VERSION ""

NS_ :

BS_:

BU_: VMCU VGGSECUSystem TECU TACHO RECU_Virt HMIIOM GSSA EMS EBS DACU CIOM BBM ATCU ACM

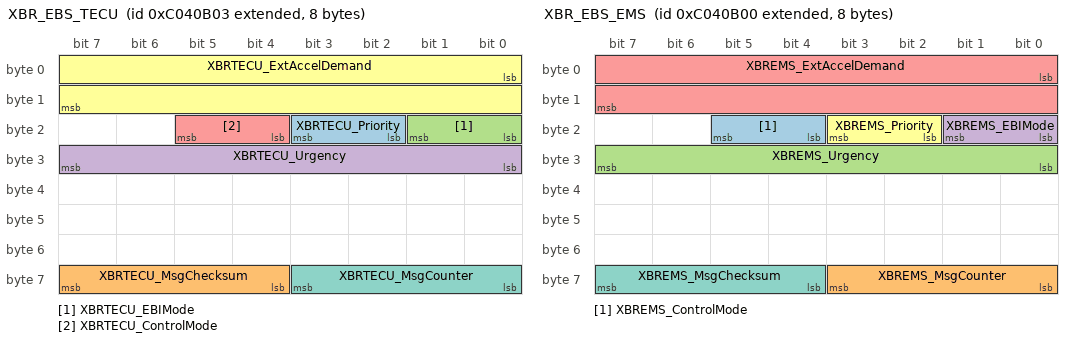
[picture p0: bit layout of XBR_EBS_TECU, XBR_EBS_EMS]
BO_ 2349075203 XBR_EBS_TECU: 8 TECU
 SG_ XBRTECU_Priority : 18|2@1+ (1,0) [0|0] ""  EBS
 SG_ XBRTECU_MsgChecksum : 60|4@1+ (1,0) [0|15] "Count"  EBS
 SG_ XBRTECU_EBIMode : 16|2@1+ (1,0) [0|0] ""  EBS
 SG_ XBRTECU_Urgency : 24|8@1+ (0.4,0) [0|102] "Percent"  EBS
 SG_ XBRTECU_ControlMode : 20|2@1+ (1,0) [0|0] ""  EBS
 SG_ XBRTECU_ExtAccelDemand : 0|16@1+ (0.00048828125,-15.687) [-15.687|16.31251171875] "m_per_s_squared"  EBS
 SG_ XBRTECU_MsgCounter : 56|4@1+ (1,0) [0|15] "Count"  EBS

BO_ 2349075200 XBR_EBS_EMS: 8 EMS
 SG_ XBREMS_ControlMode : 20|2@1+ (1,0) [0|0] ""  EBS
 SG_ XBREMS_MsgCounter : 56|4@1+ (1,0) [0|15] "Count"  EBS
 SG_ XBREMS_Urgency : 24|8@1+ (0.4,0) [0|102] "Percent"  EBS
 SG_ XBREMS_EBIMode : 16|2@1+ (1,0) [0|0] ""  EBS
 SG_ XBREMS_ExtAccelDemand : 0|16@1+ (0.00048828125,-15.687) [-15.687|16.31251171875] "m_per_s_squared"  EBS
 SG_ XBREMS_Priority : 18|2@1+ (1,0) [0|0] ""  EBS
 SG_ XBREMS_MsgChecksum : 60|4@1+ (1,0) [0|15] "Count"  EBS

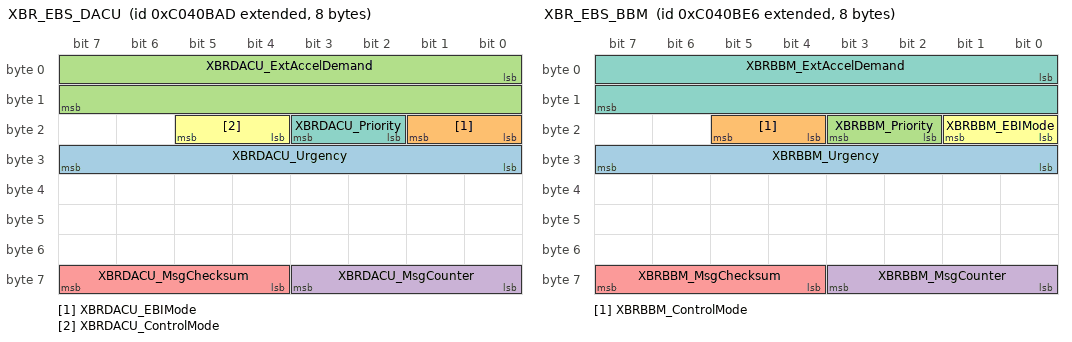
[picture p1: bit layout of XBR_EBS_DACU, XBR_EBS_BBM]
BO_ 2349075373 XBR_EBS_DACU: 8 DACU
 SG_ XBRDACU_Urgency : 24|8@1+ (0.4,0) [0|102] "Percent"  EBS,TECU
 SG_ XBRDACU_EBIMode : 16|2@1+ (1,0) [0|0] ""  EBS,TECU
 SG_ XBRDACU_ExtAccelDemand : 0|16@1+ (0.00048828125,-15.687) [-15.687|16.31251171875] "m_per_s_squared"  EBS,TECU
 SG_ XBRDACU_MsgCounter : 56|4@1+ (1,0) [0|15] "Count"  TECU,EBS
 SG_ XBRDACU_MsgChecksum : 60|4@1+ (1,0) [0|15] "Count"  TECU,EBS
 SG_ XBRDACU_ControlMode : 20|2@1+ (1,0) [0|0] ""  TECU,EBS
 SG_ XBRDACU_Priority : 18|2@1+ (1,0) [0|0] ""  EBS,TECU

BO_ 2349075430 XBR_EBS_BBM: 8 BBM
 SG_ XBRBBM_Urgency : 24|8@1+ (0.4,0) [0|102] "Percent"  EBS,VMCU
 SG_ XBRBBM_ControlMode : 20|2@1+ (1,0) [0|0] ""  EBS,VMCU
 SG_ XBRBBM_Priority : 18|2@1+ (1,0) [0|0] ""  VMCU,EBS
 SG_ XBRBBM_MsgCounter : 56|4@1+ (1,0) [0|15] "Count"  VMCU,EBS
 SG_ XBRBBM_MsgChecksum : 60|4@1+ (1,0) [0|15] "Count"  VMCU,EBS
 SG_ XBRBBM_EBIMode : 16|2@1+ (1,0) [0|0] ""  EBS,VMCU
 SG_ XBRBBM_ExtAccelDemand : 0|16@1+ (0.00048828125,-15.687) [-15.687|16.31251171875] "m_per_s_squared"  VMCU,EBS

BO_ 2566848256 WFI_X_EMS: 8 EMS
 SG_ WaterInFuelAlarm_ISig_3 : 0|2@1+ (1,0) [0|0] ""  BBM,HMIIOM,VGGSECUSystem

BO_ 2499751697 VMCU_BB1_04P: 8 VMCU
 SG_ TrailerConnected_UB_ISig_3 : 23|1@1+ (1,0) [0|0] ""  EBS
 SG_ RearAxle2DiffLock_stat_ISig_3 : 2|2@1+ (1,0) [0|0] ""  BBM,TECU,HMIIOM
 SG_ EngineStopReqBackup : 12|2@1+ (1,0) [0|0] ""  EMS
 SG_ DifferentialLockStateCentral_ISi : 6|2@1+ (1,0) [0|0] ""  HMIIOM,BBM,TECU,EBS,EMS
 SG_ RearAxle2DiffLock_stat_UB_ISig_3 : 17|1@1+ (1,0) [0|0] ""  BBM,TECU,HMIIOM
 SG_ RearPropulsionStat_Rear1Axle_ISi : 24|4@1+ (1,0) [0|0] ""  HMIIOM,EBS,EMS,TECU,BBM,DACU
 SG_ DifferentialLockStateCentral2 : 36|2@1+ (1,0) [0|0] ""  EBS,HMIIOM
 SG_ SetHSAOperation_ISig_3 : 40|3@1+ (1,0) [0|0] ""  HMIIOM,EBS
 SG_ CentralRearDiffLock_stat_ISig_3 : 4|2@1+ (1,0) [0|0] ""  HMIIOM,TECU,BBM
 SG_ LowAirPressureAlert_ISig_3 : 10|2@1+ (1,0) [0|0] ""  VGGSECUSystem,HMIIOM,EMS
 SG_ RearPropulsionStat_Rear3Axle_ISi : 32|4@1+ (1,0) [0|0] ""  DACU,HMIIOM,EMS,BBM,EBS,TECU
 SG_ DifferentialLockStateFrAxle2 : 38|2@1+ (1,0) [0|0] ""  HMIIOM,EBS
 SG_ TrailerConnected_ISig_3 : 21|2@1+ (1,0) [0|0] ""  EBS
 SG_ TrailerWithoutABS_ISig_3 : 18|2@1+ (1,0) [0|0] ""  TECU,EMS,DACU,EBS,HMIIOM
 SG_ DifferentialLockStateFrAxle1_UB_ : 14|1@1+ (1,0) [0|0] ""  BBM,EBS,HMIIOM
 SG_ DifferentialLockStateFrAxle1_ISi : 8|2@1+ (1,0) [0|0] ""  EBS,HMIIOM,BBM
 SG_ RearAxle1DiffLock_stat_UB_ISig_3 : 16|1@1+ (1,0) [0|0] ""  BBM,TECU,HMIIOM
 SG_ RearPropulsionStat_Rear2Axle_ISi : 28|4@1+ (1,0) [0|0] ""  EBS,BBM,EMS,HMIIOM,DACU,TECU
 SG_ CentralRearDiffLock_stat_UB_ISig : 15|1@1+ (1,0) [0|0] ""  HMIIOM,BBM,TECU
 SG_ RearAxle1DiffLock_stat_ISig_3 : 0|2@1+ (1,0) [0|0] ""  HMIIOM,BBM,TECU
 SG_ TrailerWithoutABS_UB_ISig_3 : 20|1@1+ (1,0) [0|0] ""  TECU,DACU,EBS,EMS,HMIIOM

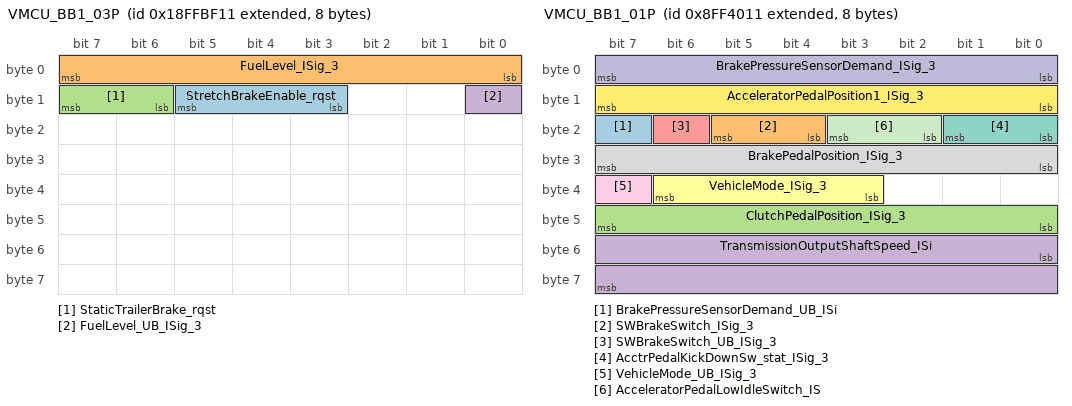
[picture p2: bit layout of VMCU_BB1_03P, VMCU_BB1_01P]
BO_ 2566897425 VMCU_BB1_03P: 8 VMCU
 SG_ StretchBrakeEnable_rqst : 11|3@1+ (1,0) [0|0] ""  EBS
 SG_ FuelLevel_ISig_3 : 0|8@1+ (0.4,0) [0|102] "Percent"  HMIIOM,BBM,CIOM,EMS
 SG_ StaticTrailerBrake_rqst : 14|2@1+ (1,0) [0|0] ""  EBS
 SG_ FuelLevel_UB_ISig_3 : 8|1@1+ (1,0) [0|0] ""  BBM,HMIIOM,CIOM,EMS

BO_ 2298429457 VMCU_BB1_01P: 8 VMCU
 SG_ BrakePressureSensorDemand_UB_ISi : 23|1@1+ (1,0) [0|0] ""  EBS
 SG_ SWBrakeSwitch_ISig_3 : 20|2@1+ (1,0) [0|0] ""  HMIIOM,EBS
 SG_ ClutchPedalPosition_ISig_3 : 40|8@1+ (0.4,0) [0|102] "Percent"  EBS
 SG_ TransmissionOutputShaftSpeed_ISi : 48|16@1+ (0.125,0) [0|8191.875] "rpm"  RECU_Virt,EMS,BBM
 SG_ SWBrakeSwitch_UB_ISig_3 : 22|1@1+ (1,0) [0|0] ""  HMIIOM,EBS
 SG_ VehicleMode_ISig_3 : 35|4@1+ (1,0) [0|0] ""  ACM,HMIIOM,CIOM,DACU,TECU,TACHO,EMS,VGGSECUSystem,BBM,EBS
 SG_ AcctrPedalKickDownSw_stat_ISig_3 : 16|2@1+ (1,0) [0|0] ""  BBM,TECU,HMIIOM,EMS,DACU
 SG_ BrakePedalPosition_ISig_3 : 24|8@1+ (0.4,0) [0|102] "Percent"  HMIIOM,TECU,EBS,CIOM,DACU,BBM
 SG_ VehicleMode_UB_ISig_3 : 39|1@1+ (1,0) [0|0] ""  EMS,CIOM,HMIIOM,DACU,TECU,VGGSECUSystem,ACM,TACHO,BBM,EBS
 SG_ BrakePressureSensorDemand_ISig_3 : 0|8@1+ (1,0) [0|255] "Percent"  EBS
 SG_ AcceleratorPedalLowIdleSwitch_IS : 18|2@1+ (1,0) [0|0] ""  HMIIOM,BBM,TECU
 SG_ AcceleratorPedalPosition1_ISig_3 : 8|8@1+ (0.4,0) [0|102] "Percent"  EMS,BBM,DACU,EBS,HMIIOM,TECU,CIOM

BO_ 2566906094 VDO1prop_X_TACHO: 32 TACHO
 SG_ RemningTimeTillNxtWklyRestPrd_IS : 160|16@1+ (1,0) [0|65535] "min"  HMIIOM
 SG_ RemainingCurDailyDrivingTime_ISi : 96|16@1+ (1,0) [0|65535] "min"  HMIIOM
 SG_ RemainingCurrentDrivingTime_ISig : 0|16@1+ (1,0) [0|65535] "min"  HMIIOM
 SG_ SingleMultiDriver_ISig_3 : 252|2@1+ (1,0) [0|0] ""  HMIIOM
 SG_ UnknownPeriods_ISig_3 : 246|2@1+ (1,0) [0|0] ""  HMIIOM
 SG_ OpenCompensationWeekBfrLast_ISig : 208|16@1+ (1,0) [0|65535] "min"  HMIIOM
 SG_ RemainingReducedDailyRestPrd_ISi : 243|3@1+ (1,0) [0|0] ""  HMIIOM
 SG_ RemainingDurOfCurBreakRest_ISig_ : 48|16@1+ (1,0) [0|65535] "min"  HMIIOM
 SG_ RemainingTimeTillNextRestBreak_I : 16|16@1+ (1,0) [0|65535] "min"  HMIIOM
 SG_ NextDrivingPeriod_ISig_3 : 80|16@1+ (1,0) [0|65535] "min"  HMIIOM
 SG_ DurationOfNextRestBreak_ISig_3 : 32|16@1+ (1,0) [0|65535] "min"  HMIIOM
 SG_ RemainingDrivTimeOfCurWeek_ISig_ : 144|16@1+ (1,0) [0|65535] "min"  HMIIOM
 SG_ DurationOfNextDailyRestPeriod_IS : 128|16@1+ (1,0) [0|65535] "min"  HMIIOM
 SG_ OpenCompensationInTheLastWeek_IS : 192|16@1+ (1,0) [0|65535] "min"  HMIIOM
 SG_ TimeOverlap_ISig_3 : 254|2@1+ (1,0) [0|0] ""  HMIIOM
 SG_ TimeBeforeStartOfNxtDrvngPrd_ISi : 64|16@1+ (1,0) [0|65535] "min"  HMIIOM
 SG_ WklyRestPrdCalcEnabledDisabled_I : 250|2@1+ (1,0) [0|0] ""  HMIIOM
 SG_ Remaining10hDrvTime_ISig_3 : 240|3@1+ (1,0) [0|0] ""  HMIIOM
 SG_ RemnngTimeTillNxtDailyRestPrd_IS : 112|16@1+ (1,0) [0|65535] "min"  HMIIOM
 SG_ DurationOfNextWeeklyRestPeriod_I : 176|16@1+ (1,0) [0|65535] "min"  HMIIOM
 SG_ OpenCompensation2ndWeekBfrLast_I : 224|16@1+ (1,0) [0|65535] "min"  HMIIOM
 SG_ SufficientData_ISig_3 : 248|2@1+ (1,0) [0|0] ""  HMIIOM

BO_ 2566832401 VDHR_X_VMCU: 8 VMCU
 SG_ TotalVehicleDistanceHighRes_ISig : 0|32@1+ (5,0) [0|21474836475] "m"  HMIIOM,EBS,EMS,ACM,DACU,TECU,CIOM,BBM,VGGSECUSystem

BO_ 2566832622 VDHR_X_TACHO: 8 TACHO
 SG_ TachoHighResTotalVehDistance : 0|32@1+ (5,0) [0|21474836475] "m"  VMCU

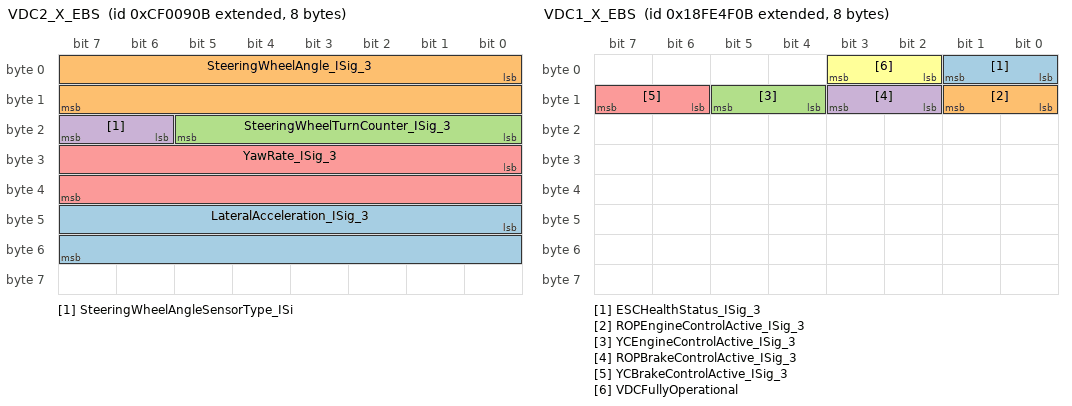
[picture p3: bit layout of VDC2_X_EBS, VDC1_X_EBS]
BO_ 2364541195 VDC2_X_EBS: 8 EBS
 SG_ LateralAcceleration_ISig_3 : 40|16@1+ (0.00048828125,-15.687) [-15.687|16.31251171875] "m_per_s_squared"  HMIIOM,BBM,DACU
 SG_ SteeringWheelAngle_ISig_3 : 0|16@1+ (0.0009765625,-31.374) [-31.374|32.6250234375] "rad"  CIOM,BBM,VMCU,DACU,VGGSECUSystem
 SG_ SteeringWheelTurnCounter_ISig_3 : 16|6@1+ (1,-32) [-32|31] "turns"  BBM
 SG_ SteeringWheelAngleSensorType_ISi : 22|2@1+ (1,0) [0|0] ""  BBM
 SG_ YawRate_ISig_3 : 24|16@1+ (0.000122,-3.92) [-3.92|4.07527] "Rad_per_s"  HMIIOM,BBM,DACU

BO_ 2566803211 VDC1_X_EBS: 8 EBS
 SG_ ESCHealthStatus_ISig_3 : 0|2@1+ (1,0) [0|0] ""  HMIIOM
 SG_ ROPEngineControlActive_ISig_3 : 8|2@1+ (1,0) [0|0] ""  VMCU,HMIIOM,DACU,TECU
 SG_ YCEngineControlActive_ISig_3 : 12|2@1+ (1,0) [0|0] ""  HMIIOM,DACU,VMCU,TECU
 SG_ ROPBrakeControlActive_ISig_3 : 10|2@1+ (1,0) [0|0] ""  TECU,VMCU,CIOM,DACU,HMIIOM
 SG_ YCBrakeControlActive_ISig_3 : 14|2@1+ (1,0) [0|0] ""  HMIIOM,DACU,TECU,VMCU,CIOM
 SG_ VDCFullyOperational : 2|2@1+ (1,0) [0|0] ""  DACU,HMIIOM

BO_ 2671902706 TesterFuncDiagMsg_BB1: 8 VMCU
 SG_ FuncDiagDataTester_ISig_3 : 0|64@1+ (1,0) [0|0] ""  EBS,TACHO,ACM

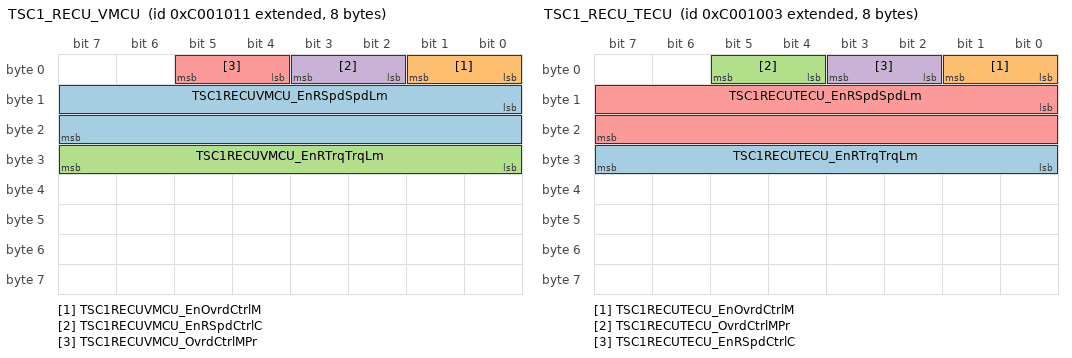
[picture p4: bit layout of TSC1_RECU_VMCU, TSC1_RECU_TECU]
BO_ 2348814353 TSC1_RECU_VMCU: 8 VMCU
 SG_ TSC1RECUVMCU_EnRSpdSpdLm : 8|16@1+ (0.125,0) [0|8191.875] "rpm"  RECU_Virt,EBS,VGGSECUSystem
 SG_ TSC1RECUVMCU_EnOvrdCtrlM : 0|2@1+ (1,0) [0|0] ""  EBS,VGGSECUSystem,RECU_Virt
 SG_ TSC1RECUVMCU_EnRTrqTrqLm : 24|8@1+ (1,-125) [-125|130] "Percent"  RECU_Virt,EBS,VGGSECUSystem
 SG_ TSC1RECUVMCU_EnRSpdCtrlC : 2|2@1+ (1,0) [0|0] ""  VGGSECUSystem,RECU_Virt,EBS
 SG_ TSC1RECUVMCU_OvrdCtrlMPr : 4|2@1+ (1,0) [0|0] ""  EBS,VGGSECUSystem,RECU_Virt

BO_ 2348814339 TSC1_RECU_TECU: 8 TECU
 SG_ TSC1RECUTECU_EnRTrqTrqLm : 24|8@1+ (1,-125) [-125|130] "Percent"  RECU_Virt
 SG_ TSC1RECUTECU_EnOvrdCtrlM : 0|2@1+ (1,0) [0|0] ""  RECU_Virt
 SG_ TSC1RECUTECU_OvrdCtrlMPr : 4|2@1+ (1,0) [0|0] ""  RECU_Virt
 SG_ TSC1RECUTECU_EnRSpdCtrlC : 2|2@1+ (1,0) [0|0] ""  RECU_Virt
 SG_ TSC1RECUTECU_EnRSpdSpdLm : 8|16@1+ (0.125,0) [0|8191.875] "rpm"  RECU_Virt

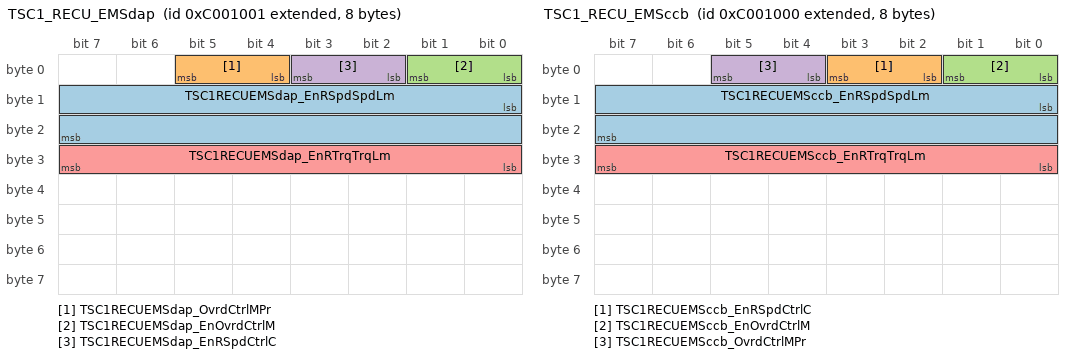
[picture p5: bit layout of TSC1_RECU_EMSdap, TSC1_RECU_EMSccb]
BO_ 2348814337 TSC1_RECU_EMSdap: 8 EMS
 SG_ TSC1RECUEMSdap_EnRSpdSpdLm : 8|16@1+ (0.125,0) [0|8191.875] "rpm"  VGGSECUSystem,RECU_Virt
 SG_ TSC1RECUEMSdap_OvrdCtrlMPr : 4|2@1+ (1,0) [0|0] ""  VGGSECUSystem,RECU_Virt
 SG_ TSC1RECUEMSdap_EnOvrdCtrlM : 0|2@1+ (1,0) [0|0] ""  RECU_Virt,VGGSECUSystem
 SG_ TSC1RECUEMSdap_EnRSpdCtrlC : 2|2@1+ (1,0) [0|0] ""  RECU_Virt,VGGSECUSystem
 SG_ TSC1RECUEMSdap_EnRTrqTrqLm : 24|8@1+ (1,-125) [-125|130] "Percent"  RECU_Virt,VGGSECUSystem

BO_ 2348814336 TSC1_RECU_EMSccb: 8 EMS
 SG_ TSC1RECUEMSccb_EnRSpdSpdLm : 8|16@1+ (0.125,0) [0|8191.875] "rpm"  RECU_Virt
 SG_ TSC1RECUEMSccb_EnRSpdCtrlC : 2|2@1+ (1,0) [0|0] ""  RECU_Virt
 SG_ TSC1RECUEMSccb_EnOvrdCtrlM : 0|2@1+ (1,0) [0|0] ""  RECU_Virt
 SG_ TSC1RECUEMSccb_OvrdCtrlMPr : 4|2@1+ (1,0) [0|0] ""  RECU_Virt
 SG_ TSC1RECUEMSccb_EnRTrqTrqLm : 24|8@1+ (1,-125) [-125|130] "Percent"  RECU_Virt

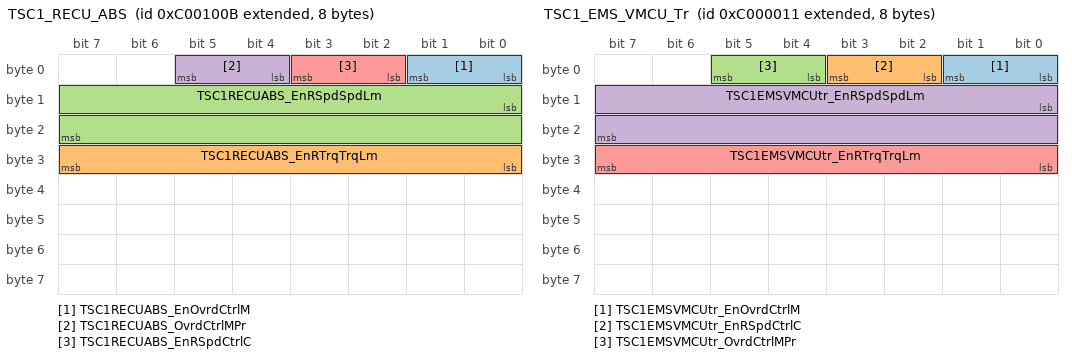
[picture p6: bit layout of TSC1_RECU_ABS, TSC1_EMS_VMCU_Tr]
BO_ 2348814347 TSC1_RECU_ABS: 8 EBS
 SG_ TSC1RECUABS_EnOvrdCtrlM : 0|2@1+ (1,0) [0|0] ""  VGGSECUSystem,RECU_Virt
 SG_ TSC1RECUABS_EnRTrqTrqLm : 24|8@1+ (1,-125) [-125|130] "Percent"  VGGSECUSystem,RECU_Virt
 SG_ TSC1RECUABS_EnRSpdSpdLm : 8|16@1+ (0.125,0) [0|8191.875] "rpm"  RECU_Virt,VGGSECUSystem
 SG_ TSC1RECUABS_OvrdCtrlMPr : 4|2@1+ (1,0) [0|0] ""  RECU_Virt,VGGSECUSystem
 SG_ TSC1RECUABS_EnRSpdCtrlC : 2|2@1+ (1,0) [0|0] ""  RECU_Virt,VGGSECUSystem

BO_ 2348810257 TSC1_EMS_VMCU_Tr: 8 VMCU
 SG_ TSC1EMSVMCUtr_EnOvrdCtrlM : 0|2@1+ (1,0) [0|0] ""  EMS
 SG_ TSC1EMSVMCUtr_EnRSpdCtrlC : 2|2@1+ (1,0) [0|0] ""  EMS
 SG_ TSC1EMSVMCUtr_OvrdCtrlMPr : 4|2@1+ (1,0) [0|0] ""  EMS
 SG_ TSC1EMSVMCUtr_EnRSpdSpdLm : 8|16@1+ (0.125,0) [0|8191.875] "rpm"  EMS
 SG_ TSC1EMSVMCUtr_EnRTrqTrqLm : 24|8@1+ (1,-125) [-125|130] "Percent"  EMS

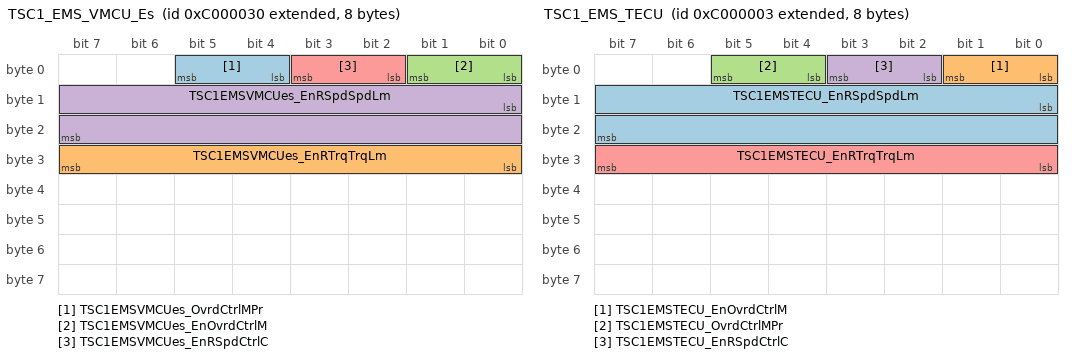
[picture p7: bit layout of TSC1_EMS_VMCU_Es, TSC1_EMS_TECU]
BO_ 2348810288 TSC1_EMS_VMCU_Es: 8 VMCU
 SG_ TSC1EMSVMCUes_OvrdCtrlMPr : 4|2@1+ (1,0) [0|0] ""  EMS,TECU
 SG_ TSC1EMSVMCUes_EnRTrqTrqLm : 24|8@1+ (1,-125) [-125|130] "Percent"  TECU,EMS
 SG_ TSC1EMSVMCUes_EnOvrdCtrlM : 0|2@1+ (1,0) [0|0] ""  TECU,EMS
 SG_ TSC1EMSVMCUes_EnRSpdSpdLm : 8|16@1+ (0.125,0) [0|8191.875] "rpm"  TECU,EMS
 SG_ TSC1EMSVMCUes_EnRSpdCtrlC : 2|2@1+ (1,0) [0|0] ""  EMS,TECU

BO_ 2348810243 TSC1_EMS_TECU: 8 TECU
 SG_ TSC1EMSTECU_EnRSpdSpdLm : 8|16@1+ (0.125,0) [0|8191.875] "rpm"  EMS
 SG_ TSC1EMSTECU_EnOvrdCtrlM : 0|2@1+ (1,0) [0|0] ""  EMS
 SG_ TSC1EMSTECU_OvrdCtrlMPr : 4|2@1+ (1,0) [0|0] ""  EMS
 SG_ TSC1EMSTECU_EnRSpdCtrlC : 2|2@1+ (1,0) [0|0] ""  EMS
 SG_ TSC1EMSTECU_EnRTrqTrqLm : 24|8@1+ (1,-125) [-125|130] "Percent"  EMS

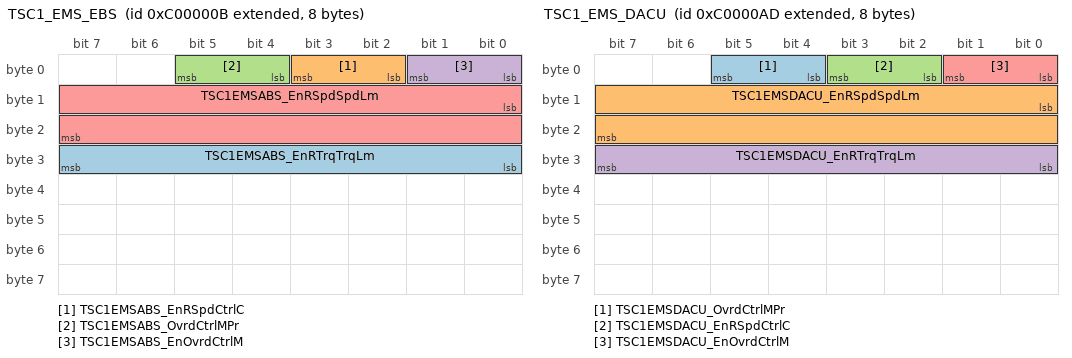
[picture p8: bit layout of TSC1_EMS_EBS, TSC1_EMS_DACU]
BO_ 2348810251 TSC1_EMS_EBS: 8 EBS
 SG_ TSC1EMSABS_EnRTrqTrqLm : 24|8@1+ (1,-125) [-125|130] "Percent"  EMS
 SG_ TSC1EMSABS_EnRSpdCtrlC : 2|2@1+ (1,0) [0|0] ""  EMS
 SG_ TSC1EMSABS_OvrdCtrlMPr : 4|2@1+ (1,0) [0|0] ""  EMS
 SG_ TSC1EMSABS_EnOvrdCtrlM : 0|2@1+ (1,0) [0|0] ""  EMS
 SG_ TSC1EMSABS_EnRSpdSpdLm : 8|16@1+ (0.125,0) [0|8191.875] "rpm"  EMS

BO_ 2348810413 TSC1_EMS_DACU: 8 DACU
 SG_ TSC1EMSDACU_OvrdCtrlMPr : 4|2@1+ (1,0) [0|0] ""  EMS
 SG_ TSC1EMSDACU_EnRSpdSpdLm : 8|16@1+ (0.125,0) [0|8191.875] "rpm"  EMS
 SG_ TSC1EMSDACU_EnRSpdCtrlC : 2|2@1+ (1,0) [0|0] ""  EMS
 SG_ TSC1EMSDACU_EnRTrqTrqLm : 24|8@1+ (1,-125) [-125|130] "Percent"  EMS
 SG_ TSC1EMSDACU_EnOvrdCtrlM : 0|2@1+ (1,0) [0|0] ""  EMS

CM_ "COM_MATRIX_1.31.X0";
CM_ BU_ VGGSECUSystem "Describes interfaces used by a couple of ECUs within VGGS system.";
CM_ BU_ GSSA "Gearshift Selector, Vendor";
CM_ BU_ ATCU "ATCU Represents Allison Transmission, reception of signal on BB1 to avoid that TECU receives signal on both BB1 & BB2.";
CM_ BO_ 2349075203 "PGN 1024 External Brake Request";
CM_ SG_ 2349075203 XBRTECU_Urgency "254 Error ; 255 Not available";
CM_ SG_ 2349075203 XBRTECU_ExtAccelDemand "65024 - 65279 Error ; 65280 - 65535 Not available";
CM_ BO_ 2349075200 "PGN 1024 External Brake Request";
CM_ BO_ 2349075373 "PGN 1024 External Brake Request";
CM_ SG_ 2349075373 XBRDACU_Urgency "254 Error ; 255 Not available";
CM_ SG_ 2349075373 XBRDACU_ExtAccelDemand "65024 - 65279 Error ; 65280 - 65535 Not available";
CM_ BO_ 2349075430 "PGN 1024 External Brake Request";
CM_ SG_ 2349075430 XBRBBM_Urgency "254 Error ; 255 Not available";
CM_ SG_ 2349075430 XBRBBM_ExtAccelDemand "65024 - 65279 Error ; 65280 - 65535 Not available";
CM_ BO_ 2566848256 "PGN 65279 Water in Fuel Indicator";
CM_ SG_ 2566897425 FuelLevel_ISig_3 "254 Error ; 255 Not available";
CM_ SG_ 2298429457 ClutchPedalPosition_ISig_3 "254 Error ; 255 Not available";
CM_ SG_ 2298429457 TransmissionOutputShaftSpeed_ISi "65024 - 65279 Error ; 65280 - 65535 Not available";
CM_ SG_ 2298429457 BrakePedalPosition_ISig_3 "254 Error ; 255 Not available";
CM_ SG_ 2298429457 BrakePressureSensorDemand_ISig_3 "254 Error ; 255 Not available";
CM_ SG_ 2298429457 AcceleratorPedalPosition1_ISig_3 "254 Error ; 255 Not available";
CM_ SG_ 2566906094 RemningTimeTillNxtWklyRestPrd_IS "65024 - 65279 Error ; 65280 - 65535 Not available";
CM_ SG_ 2566906094 RemainingCurDailyDrivingTime_ISi "65024 - 65279 Error ; 65280 - 65535 Not available";
CM_ SG_ 2566906094 RemainingCurrentDrivingTime_ISig "65024 - 65279 Error ; 65280 - 65535 Not available";
CM_ SG_ 2566906094 OpenCompensationWeekBfrLast_ISig "65024 - 65279 Error ; 65280 - 65535 Not available";
CM_ SG_ 2566906094 RemainingDurOfCurBreakRest_ISig_ "65024 - 65279 Error ; 65280 - 65535 Not available";
CM_ SG_ 2566906094 RemainingTimeTillNextRestBreak_I "65024 - 65279 Error ; 65280 - 65535 Not available";
CM_ SG_ 2566906094 NextDrivingPeriod_ISig_3 "65024 - 65279 Error ; 65280 - 65535 Not available";
CM_ SG_ 2566906094 DurationOfNextRestBreak_ISig_3 "65024 - 65279 Error ; 65280 - 65535 Not available";
CM_ SG_ 2566906094 RemainingDrivTimeOfCurWeek_ISig_ "65024 - 65279 Error ; 65280 - 65535 Not available";
CM_ SG_ 2566906094 DurationOfNextDailyRestPeriod_IS "65024 - 65279 Error ; 65280 - 65535 Not available";
CM_ SG_ 2566906094 OpenCompensationInTheLastWeek_IS "65024 - 65279 Error ; 65280 - 65535 Not available";
CM_ SG_ 2566906094 TimeBeforeStartOfNxtDrvngPrd_ISi "65024 - 65279 Error ; 65280 - 65535 Not available";
CM_ SG_ 2566906094 RemnngTimeTillNxtDailyRestPrd_IS "65024 - 65279 Error ; 65280 - 65535 Not available";
CM_ SG_ 2566906094 DurationOfNextWeeklyRestPeriod_I "65024 - 65279 Error ; 65280 - 65535 Not available";
CM_ SG_ 2566906094 OpenCompensation2ndWeekBfrLast_I "65024 - 65279 Error ; 65280 - 65535 Not available";
CM_ BO_ 2566832401 "PGN 65217 High Resolution Vehicle Distance";
CM_ SG_ 2566832401 TotalVehicleDistanceHighRes_ISig "4261412864 - 4278190079 Error ; 4278190080 - 4294967295 Not available";
CM_ BO_ 2566832622 "PGN 65217 High Resolution Vehicle Distance, From TACHO";
CM_ SG_ 2566832622 TachoHighResTotalVehDistance "4261412864 - 4278190079 Error ; 4278190080 - 4294967295 Not available";
CM_ BO_ 2364541195 "PGN 61449 Vehicle Dynamic Stability Control 2";
CM_ SG_ 2364541195 LateralAcceleration_ISig_3 "65024 - 65279 Error ; 65280 - 65535 Not available";
CM_ SG_ 2364541195 SteeringWheelAngle_ISig_3 "65024 - 65279 Error ; 65280 - 65535 Not available";
CM_ SG_ 2364541195 SteeringWheelTurnCounter_ISig_3 "62 Error; 63 Not available";
CM_ SG_ 2364541195 YawRate_ISig_3 "65024 - 65279 Error ; 65280 - 65535 Not available";
CM_ BO_ 2566803211 "PGN 65103 Vehicle Dynamic Stability Control 1";
CM_ BO_ 2348814353 "PGN 0 Torque/Speed Control 1, From VMCU to RECU";
CM_ SG_ 2348814353 TSC1RECUVMCU_EnRSpdSpdLm "65024 - 65279 Error ; 65280 - 65535 Not available";
CM_ SG_ 2348814353 TSC1RECUVMCU_EnRTrqTrqLm "254 Error ; 255 Not available";
CM_ BO_ 2348814339 "PGN 0 Torque/Speed Control 1";
CM_ BO_ 2348814337 "PGN 0 Torque/Speed Control 1";
CM_ SG_ 2348814337 TSC1RECUEMSdap_EnRSpdSpdLm "65024 - 65279 Error ; 65280 - 65535 Not available";
CM_ SG_ 2348814337 TSC1RECUEMSdap_EnRTrqTrqLm "254 Error ; 255 Not available";
CM_ BO_ 2348814336 "PGN 0 Torque/Speed Control 1";
CM_ SG_ 2348814336 TSC1RECUEMSccb_EnRSpdSpdLm "65024 - 65279 Error ; 65280 - 65535 Not available";
CM_ SG_ 2348814336 TSC1RECUEMSccb_EnRTrqTrqLm "254 Error ; 255 Not available";
CM_ BO_ 2348814347 "PGN 0 Torque/Speed Control 1";
CM_ SG_ 2348814347 TSC1RECUABS_EnRTrqTrqLm "254 Error ; 255 Not available";
CM_ SG_ 2348814347 TSC1RECUABS_EnRSpdSpdLm "65024 - 65279 Error ; 65280 - 65535 Not available";
CM_ BO_ 2348810257 "PGN 0 Torque/Speed Control 1, Torque control, From VMCU to EMS";
CM_ SG_ 2348810257 TSC1EMSVMCUtr_EnRSpdSpdLm "65024 - 65279 Error ; 65280 - 65535 Not available";
CM_ SG_ 2348810257 TSC1EMSVMCUtr_EnRTrqTrqLm "254 Error ; 255 Not available";
CM_ BO_ 2348810288 "PGN 0 Torque/Speed Control 1, Engine speed control, From VMCU to EMS";
CM_ SG_ 2348810288 TSC1EMSVMCUes_EnRTrqTrqLm "254 Error ; 255 Not available";
CM_ SG_ 2348810288 TSC1EMSVMCUes_EnRSpdSpdLm "65024 - 65279 Error ; 65280 - 65535 Not available";
CM_ BO_ 2348810243 "PGN 0 Torque/Speed Control 1, From TECU to EMS";
CM_ SG_ 2348810243 TSC1EMSTECU_EnRSpdSpdLm "65024 - 65279 Error ; 65280 - 65535 Not available";
CM_ SG_ 2348810243 TSC1EMSTECU_EnRTrqTrqLm "254 Error ; 255 Not available";
CM_ BO_ 2348810251 "PGN 0 Torque/Speed Control 1, From EBS to EMS";
CM_ SG_ 2348810251 TSC1EMSABS_EnRTrqTrqLm "254 Error ; 255 Not available";
CM_ SG_ 2348810251 TSC1EMSABS_EnRSpdSpdLm "65024 - 65279 Error ; 65280 - 65535 Not available";
CM_ BO_ 2348810413 "PGN 0 Torque/Speed Control 1, From DACU to EMS";
CM_ SG_ 2348810413 TSC1EMSDACU_EnRSpdSpdLm "65024 - 65279 Error ; 65280 - 65535 Not available";
CM_ SG_ 2348810413 TSC1EMSDACU_EnRTrqTrqLm "254 Error ; 255 Not available";
BA_DEF_ BO_  "GenMsgStartDelayTime" INT 0 0;
BA_DEF_ BO_  "GenMsgDelayTime" INT 0 0;
BA_DEF_ BO_  "GenMsgNrOfRepetition" INT 0 0;
BA_DEF_ BO_  "GenMsgCycleTimeFast" INT 0 0;
BA_DEF_ BO_  "GenMsgCycleTime" INT 0 0;
BA_DEF_ BO_  "GenMsgSendType" ENUM  "Cyclic","NotUsed","NotUsed","NotUsed","NotUsed","NotUsed","NotUsed","IfActive","NoMsgSendType","NotUsed";
BA_DEF_ SG_  "GenSigStartValue" INT 0 0;
BA_DEF_ SG_  "GenSigCycleTimeActive" INT 0 0;
BA_DEF_ SG_  "GenSigCycleTime" INT 0 0;
BA_DEF_ SG_  "GenSigSendType" ENUM  "Cyclic","OnWrite","OnWriteWithRepetition","OnChange","OnChangeWithRepetition","IfActive","IfActiveWithRepetition","NoSigSendType","NotUsed","NotUsed","NotUsed","NotUsed","NotUsed";
BA_DEF_  "Baudrate" INT 0 1000000;
BA_DEF_  "BusType" STRING ;
BA_DEF_  "NmType" STRING ;
BA_DEF_  "Manufacturer" STRING ;
BA_DEF_  "VersionYear" INT 0 99;
BA_DEF_  "VersionNumber" INT 0 99;
BA_DEF_  "VersionMonth" INT 1 12;
BA_DEF_  "VersionDay" INT 1 31;
BA_DEF_ BO_  "VFrameFormat" ENUM  "StandardCAN","ExtendedCAN","reserved","J1939PG";
BA_DEF_ BU_  "TpOwnSystemEcuNumber" HEX 0 255;
BA_DEF_ BO_  "TpJ1939VarDlc" ENUM  "No","Yes";
BA_DEF_ SG_  "SigType" ENUM  "Default","Range","RangeSigned","ASCII","Discrete","Control","ReferencePGN","DTC","StringDelimiter","StringLength","StringLengthControl";
BA_DEF_ SG_  "SeToolVersion_SIGNAL" STRING ;
BA_DEF_ SG_  "SeToolUniqueID_SIGNAL" STRING ;
BA_DEF_ SG_  "SeToolOwnerSigGroup_SIGNAL" STRING ;
BA_DEF_ SG_  "SeToolOwnerSigGroupID_SIGNAL" STRING ;
BA_DEF_ SG_  "SeToolName_SIGNAL" STRING ;
BA_DEF_ SG_  "SeToolItemID_SIGNAL" STRING ;
BA_DEF_ SG_  "SeToolAncestorID_SIGNAL" STRING ;
BA_DEF_ SG_  "SPN" INT 0 524287;
BA_DEF_  "ProtocolType" STRING ;
BA_DEF_ SG_  "Platform_VMCU1_Sig" ENUM  "No","Yes";
BA_DEF_ BU_  "NmStationAddress" INT 0 255;
BA_DEF_ BU_  "NmJ1939IdentityNumber" INT 0 2097151;
BA_DEF_  "NmAsrWaitBusSleepTime" INT 0 65535;
BA_DEF_  "NmAsrTimeoutTime" INT 0 65535;
BA_DEF_  "NmAsrRepeatMessageTime" INT 0 65535;
BA_DEF_ BU_  "NmAsrNodeIdentifier" HEX 0 253;
BA_DEF_ BU_  "NmAsrNode" ENUM  "No","Yes";
BA_DEF_  "NmAsrMessageCount" INT 1 256;
BA_DEF_  "NmAsrCanMsgCycleTime" INT 0 65535;
BA_DEF_  "NmAsrBaseAddress" HEX 0 536870911;
BA_DEF_ SG_  "NeedsUpdateBit" ENUM  "No","Yes";
BA_DEF_ BU_  "IsOBDrelevant" ENUM  "No","Yes";
BA_DEF_ SG_  "GenSigMaxLatency" INT 0 65535;
BA_DEF_ SG_  "GenSigILSupport" ENUM  "Yes","No";
BA_DEF_ BO_  "GenMsgRequestable" INT 0 1;
BA_DEF_ BO_  "GenMsgILSupport" ENUM  "No","Yes";
BA_DEF_ BU_  "DiagnosticClientAddress" HEX 0 255;
BA_DEF_ BO_  "DiagUUDTResponse" ENUM  "No","Yes";
BA_DEF_ BO_  "DiagState" ENUM  "No","Yes";
BA_DEF_ BU_  "DiagRole" ENUM  "None","OBDTester","ExternalTester","InternalTester";
BA_DEF_ BO_  "DiagResponse" ENUM  "No","Yes";
BA_DEF_ BO_  "DiagRequest" ENUM  "No","Yes";
BA_DEF_ BO_  "DiagConnection" HEX 0 65535;
BA_DEF_  "DBName" STRING ;
BA_DEF_ BO_  "CanTpFcFrameId" HEX 0 2147483647;
BA_DEF_ BO_  "CanTpBs" INT 0 255;
BA_DEF_ SG_  "SystemSignalLongSymbol" STRING ;
BA_DEF_REL_ BU_SG_REL_  "GenSigTimeoutTime" INT 0 65535;
BA_DEF_REL_ BU_SG_REL_  "GenSigFirstTimeoutTime" INT 0 65535;
BA_DEF_DEF_  "GenMsgStartDelayTime" 0;
BA_DEF_DEF_  "GenMsgDelayTime" 0;
BA_DEF_DEF_  "GenMsgNrOfRepetition" 0;
BA_DEF_DEF_  "GenMsgCycleTimeFast" 0;
BA_DEF_DEF_  "GenMsgCycleTime" 0;
BA_DEF_DEF_  "GenMsgSendType" "Cyclic";
BA_DEF_DEF_  "GenSigStartValue" 0;
BA_DEF_DEF_  "GenSigCycleTimeActive" 0;
BA_DEF_DEF_  "GenSigCycleTime" 0;
BA_DEF_DEF_  "GenSigSendType" "Cyclic";
BA_DEF_DEF_  "Baudrate" 500000;
BA_DEF_DEF_  "BusType" "";
BA_DEF_DEF_  "NmType" "";
BA_DEF_DEF_  "Manufacturer" "VOLVO_AB";
BA_DEF_DEF_  "VersionYear" 0;
BA_DEF_DEF_  "VersionNumber" 0;
BA_DEF_DEF_  "VersionMonth" 1;
BA_DEF_DEF_  "VersionDay" 1;
BA_DEF_DEF_  "VFrameFormat" "ExtendedCAN";
BA_DEF_DEF_  "TpOwnSystemEcuNumber" 0;
BA_DEF_DEF_  "TpJ1939VarDlc" "No";
BA_DEF_DEF_  "SigType" "Default";
BA_DEF_DEF_  "SeToolVersion_SIGNAL" "";
BA_DEF_DEF_  "SeToolUniqueID_SIGNAL" "";
BA_DEF_DEF_  "SeToolOwnerSigGroup_SIGNAL" "";
BA_DEF_DEF_  "SeToolOwnerSigGroupID_SIGNAL" "";
BA_DEF_DEF_  "SeToolName_SIGNAL" "";
BA_DEF_DEF_  "SeToolItemID_SIGNAL" "";
BA_DEF_DEF_  "SeToolAncestorID_SIGNAL" "";
BA_DEF_DEF_  "SPN" 0;
BA_DEF_DEF_  "ProtocolType" "";
BA_DEF_DEF_  "Platform_VMCU1_Sig" "No";
BA_DEF_DEF_  "NmStationAddress" 254;
BA_DEF_DEF_  "NmJ1939IdentityNumber" 0;
BA_DEF_DEF_  "NmAsrWaitBusSleepTime" 750;
BA_DEF_DEF_  "NmAsrTimeoutTime" 5000;
BA_DEF_DEF_  "NmAsrRepeatMessageTime" 300;
BA_DEF_DEF_  "NmAsrNodeIdentifier" 0;
BA_DEF_DEF_  "NmAsrNode" "Yes";
BA_DEF_DEF_  "NmAsrMessageCount" 256;
BA_DEF_DEF_  "NmAsrCanMsgCycleTime" 200;
BA_DEF_DEF_  "NmAsrBaseAddress" 486506496;
BA_DEF_DEF_  "NeedsUpdateBit" "No";
BA_DEF_DEF_  "IsOBDrelevant" "No";
BA_DEF_DEF_  "GenSigMaxLatency" 0;
BA_DEF_DEF_  "GenSigILSupport" "Yes";
BA_DEF_DEF_  "GenMsgRequestable" 1;
BA_DEF_DEF_  "GenMsgILSupport" "Yes";
BA_DEF_DEF_  "DiagnosticClientAddress" 0;
BA_DEF_DEF_  "DiagUUDTResponse" "No";
BA_DEF_DEF_  "DiagState" "No";
BA_DEF_DEF_  "DiagRole" "None";
BA_DEF_DEF_  "DiagResponse" "No";
BA_DEF_DEF_  "DiagRequest" "No";
BA_DEF_DEF_  "DiagConnection" 0;
BA_DEF_DEF_  "DBName" "";
BA_DEF_DEF_  "CanTpFcFrameId" 2147483647;
BA_DEF_DEF_  "CanTpBs" 255;
BA_DEF_DEF_REL_ "GenSigTimeoutTime" 0;
BA_DEF_DEF_REL_ "GenSigFirstTimeoutTime" 0;
BA_DEF_DEF_  "SystemSignalLongSymbol" "";
BA_ "BusType" "CAN";
BA_ "Baudrate" 250000;
BA_ "ProtocolType" "J1939";
BA_ "VersionDay" 28;
BA_ "VersionMonth" 2;
BA_ "VersionNumber" 1;
BA_ "VersionYear" 18;
BA_ "DBName" "Backbone1J1939";
BA_ "IsOBDrelevant" BU_ VMCU 1;
BA_ "TpOwnSystemEcuNumber" BU_ VMCU 36;
BA_ "NmAsrNode" BU_ VMCU 0;
BA_ "NmAsrNodeIdentifier" BU_ VMCU 17;
BA_ "NmJ1939IdentityNumber" BU_ VMCU 17;
BA_ "NmStationAddress" BU_ VMCU 17;
BA_ "NmAsrNode" BU_ VGGSECUSystem 0;
BA_ "TpOwnSystemEcuNumber" BU_ TECU 24;
BA_ "NmAsrNode" BU_ TECU 0;
BA_ "NmAsrNodeIdentifier" BU_ TECU 3;
BA_ "NmJ1939IdentityNumber" BU_ TECU 3;
BA_ "NmStationAddress" BU_ TECU 3;
BA_ "TpOwnSystemEcuNumber" BU_ TACHO 238;
BA_ "NmAsrNode" BU_ TACHO 0;
BA_ "NmAsrNodeIdentifier" BU_ TACHO 238;
BA_ "NmJ1939IdentityNumber" BU_ TACHO 238;
BA_ "NmStationAddress" BU_ TACHO 238;
BA_ "TpOwnSystemEcuNumber" BU_ RECU_Virt 16;
BA_ "NmAsrNode" BU_ RECU_Virt 0;
BA_ "NmAsrNodeIdentifier" BU_ RECU_Virt 16;
BA_ "NmJ1939IdentityNumber" BU_ RECU_Virt 16;
BA_ "NmStationAddress" BU_ RECU_Virt 16;
BA_ "DiagRole" BU_ HMIIOM 3;
BA_ "DiagnosticClientAddress" BU_ HMIIOM 243;
BA_ "TpOwnSystemEcuNumber" BU_ HMIIOM 96;
BA_ "NmAsrNode" BU_ HMIIOM 0;
BA_ "NmAsrNodeIdentifier" BU_ HMIIOM 23;
BA_ "NmJ1939IdentityNumber" BU_ HMIIOM 23;
BA_ "NmStationAddress" BU_ HMIIOM 23;
BA_ "NmAsrNode" BU_ GSSA 0;
BA_ "NmAsrNodeIdentifier" BU_ GSSA 5;
BA_ "NmJ1939IdentityNumber" BU_ GSSA 5;
BA_ "NmStationAddress" BU_ GSSA 5;
BA_ "IsOBDrelevant" BU_ EMS 1;
BA_ "TpOwnSystemEcuNumber" BU_ EMS 16;
BA_ "NmAsrNode" BU_ EMS 0;
BA_ "NmStationAddress" BU_ EMS 0;
BA_ "TpOwnSystemEcuNumber" BU_ EBS 40;
BA_ "NmAsrNode" BU_ EBS 0;
BA_ "NmAsrNodeIdentifier" BU_ EBS 11;
BA_ "NmJ1939IdentityNumber" BU_ EBS 11;
BA_ "NmStationAddress" BU_ EBS 11;
BA_ "TpOwnSystemEcuNumber" BU_ DACU 80;
BA_ "NmAsrNode" BU_ DACU 0;
BA_ "NmAsrNodeIdentifier" BU_ DACU 173;
BA_ "NmJ1939IdentityNumber" BU_ DACU 173;
BA_ "NmStationAddress" BU_ DACU 173;
BA_ "TpOwnSystemEcuNumber" BU_ CIOM 64;
BA_ "NmAsrNode" BU_ CIOM 0;
BA_ "NmAsrNodeIdentifier" BU_ CIOM 49;
BA_ "NmJ1939IdentityNumber" BU_ CIOM 49;
BA_ "NmStationAddress" BU_ CIOM 49;
BA_ "TpOwnSystemEcuNumber" BU_ BBM 230;
BA_ "NmAsrNode" BU_ BBM 0;
BA_ "NmAsrNodeIdentifier" BU_ BBM 230;
BA_ "NmJ1939IdentityNumber" BU_ BBM 230;
BA_ "NmStationAddress" BU_ BBM 230;
BA_ "TpOwnSystemEcuNumber" BU_ ATCU 24;
BA_ "NmAsrNode" BU_ ATCU 0;
BA_ "NmAsrNodeIdentifier" BU_ ATCU 3;
BA_ "NmJ1939IdentityNumber" BU_ ATCU 3;
BA_ "NmStationAddress" BU_ ATCU 3;
BA_ "IsOBDrelevant" BU_ ACM 1;
BA_ "TpOwnSystemEcuNumber" BU_ ACM 17;
BA_ "NmAsrNode" BU_ ACM 0;
BA_ "NmAsrNodeIdentifier" BU_ ACM 61;
BA_ "NmJ1939IdentityNumber" BU_ ACM 61;
BA_ "NmStationAddress" BU_ ACM 61;
BA_ "GenMsgSendType" BO_ 2349075203 8;
BA_ "GenMsgDelayTime" BO_ 2349075203 15;
BA_ "VFrameFormat" BO_ 2349075203 3;
BA_ "GenMsgSendType" BO_ 2349075200 8;
BA_ "GenMsgDelayTime" BO_ 2349075200 15;
BA_ "VFrameFormat" BO_ 2349075200 3;
BA_ "GenMsgSendType" BO_ 2349075373 8;
BA_ "GenMsgDelayTime" BO_ 2349075373 15;
BA_ "VFrameFormat" BO_ 2349075373 3;
BA_ "GenMsgSendType" BO_ 2349075430 8;
BA_ "GenMsgDelayTime" BO_ 2349075430 15;
BA_ "VFrameFormat" BO_ 2349075430 3;
BA_ "GenMsgCycleTime" BO_ 2566848256 10000;
BA_ "GenMsgStartDelayTime" BO_ 2566848256 660;
BA_ "VFrameFormat" BO_ 2566848256 3;
BA_ "GenMsgCycleTime" BO_ 2499751697 100;
BA_ "GenMsgStartDelayTime" BO_ 2499751697 55;
BA_ "VFrameFormat" BO_ 2499751697 3;
BA_ "GenMsgCycleTime" BO_ 2566897425 500;
BA_ "GenMsgStartDelayTime" BO_ 2566897425 15;
BA_ "VFrameFormat" BO_ 2566897425 3;
BA_ "GenMsgCycleTime" BO_ 2298429457 10;
BA_ "VFrameFormat" BO_ 2298429457 3;
BA_ "GenMsgCycleTime" BO_ 2566906094 60000;
BA_ "GenMsgDelayTime" BO_ 2566906094 995;
BA_ "VFrameFormat" BO_ 2566906094 3;
BA_ "GenMsgCycleTime" BO_ 2566832401 1000;
BA_ "GenMsgStartDelayTime" BO_ 2566832401 235;
BA_ "VFrameFormat" BO_ 2566832401 3;
BA_ "GenMsgCycleTime" BO_ 2566832622 1000;
BA_ "VFrameFormat" BO_ 2566832622 3;
BA_ "GenMsgCycleTime" BO_ 2364541195 10;
BA_ "VFrameFormat" BO_ 2364541195 3;
BA_ "GenMsgCycleTime" BO_ 2566803211 100;
BA_ "GenMsgStartDelayTime" BO_ 2566803211 55;
BA_ "VFrameFormat" BO_ 2566803211 3;
BA_ "DiagConnection" BO_ 2671902706 62190;
BA_ "DiagState" BO_ 2671902706 1;
BA_ "GenMsgILSupport" BO_ 2671902706 0;
BA_ "GenMsgSendType" BO_ 2671902706 8;
BA_ "VFrameFormat" BO_ 2671902706 3;
BA_ "GenMsgSendType" BO_ 2348814353 7;
BA_ "GenMsgCycleTimeFast" BO_ 2348814353 50;
BA_ "GenMsgNrOfRepetition" BO_ 2348814353 3;
BA_ "VFrameFormat" BO_ 2348814353 3;
BA_ "GenMsgSendType" BO_ 2348814339 7;
BA_ "GenMsgCycleTimeFast" BO_ 2348814339 50;
BA_ "GenMsgNrOfRepetition" BO_ 2348814339 3;
BA_ "VFrameFormat" BO_ 2348814339 3;
BA_ "GenMsgSendType" BO_ 2348814337 7;
BA_ "GenMsgCycleTimeFast" BO_ 2348814337 50;
BA_ "GenMsgNrOfRepetition" BO_ 2348814337 3;
BA_ "VFrameFormat" BO_ 2348814337 3;
BA_ "GenMsgSendType" BO_ 2348814336 7;
BA_ "GenMsgCycleTimeFast" BO_ 2348814336 50;
BA_ "GenMsgNrOfRepetition" BO_ 2348814336 3;
BA_ "VFrameFormat" BO_ 2348814336 3;
BA_ "GenMsgSendType" BO_ 2348814347 7;
BA_ "GenMsgCycleTimeFast" BO_ 2348814347 50;
BA_ "GenMsgNrOfRepetition" BO_ 2348814347 3;
BA_ "VFrameFormat" BO_ 2348814347 3;
BA_ "GenMsgSendType" BO_ 2348810257 7;
BA_ "GenMsgCycleTimeFast" BO_ 2348810257 20;
BA_ "GenMsgNrOfRepetition" BO_ 2348810257 3;
BA_ "VFrameFormat" BO_ 2348810257 3;
BA_ "GenMsgSendType" BO_ 2348810288 7;
BA_ "GenMsgCycleTimeFast" BO_ 2348810288 20;
BA_ "GenMsgNrOfRepetition" BO_ 2348810288 3;
BA_ "VFrameFormat" BO_ 2348810288 3;
BA_ "GenMsgSendType" BO_ 2348810243 7;
BA_ "GenMsgCycleTimeFast" BO_ 2348810243 10;
BA_ "GenMsgNrOfRepetition" BO_ 2348810243 3;
BA_ "VFrameFormat" BO_ 2348810243 3;
BA_ "GenMsgSendType" BO_ 2348810251 7;
BA_ "GenMsgCycleTimeFast" BO_ 2348810251 10;
BA_ "GenMsgNrOfRepetition" BO_ 2348810251 3;
BA_ "VFrameFormat" BO_ 2348810251 3;
BA_ "GenMsgSendType" BO_ 2348810413 7;
BA_ "GenMsgCycleTimeFast" BO_ 2348810413 20;
BA_ "GenMsgNrOfRepetition" BO_ 2348810413 3;
BA_ "VFrameFormat" BO_ 2348810413 3;
BA_ "GenSigSendType" SG_ 2349075203 XBRTECU_Priority 1;
BA_ "GenSigStartValue" SG_ 2349075203 XBRTECU_Priority 3;
BA_ "Platform_VMCU1_Sig" SG_ 2349075203 XBRTECU_Priority 1;
BA_ "SPN" SG_ 2349075203 XBRTECU_Priority 2915;
BA_ "SeToolAncestorID_SIGNAL" SG_ 2349075203 XBRTECU_Priority "x0000001D0415DF81";
BA_ "SeToolItemID_SIGNAL" SG_ 2349075203 XBRTECU_Priority "x0000001D0415DF81";
BA_ "SeToolName_SIGNAL" SG_ 2349075203 XBRTECU_Priority "Priority";
BA_ "SeToolOwnerSigGroupID_SIGNAL" SG_ 2349075203 XBRTECU_Priority "x0000001D043D6E5C";
BA_ "SeToolOwnerSigGroup_SIGNAL" SG_ 2349075203 XBRTECU_Priority "XBRTECU";
BA_ "SeToolVersion_SIGNAL" SG_ 2349075203 XBRTECU_Priority "1";
BA_ "GenSigSendType" SG_ 2349075203 XBRTECU_MsgChecksum 1;
BA_ "Platform_VMCU1_Sig" SG_ 2349075203 XBRTECU_MsgChecksum 1;
BA_ "SPN" SG_ 2349075203 XBRTECU_MsgChecksum 3188;
BA_ "SeToolAncestorID_SIGNAL" SG_ 2349075203 XBRTECU_MsgChecksum "x0000001D043103C0";
BA_ "SeToolItemID_SIGNAL" SG_ 2349075203 XBRTECU_MsgChecksum "x0000001D043103C0";
BA_ "SeToolName_SIGNAL" SG_ 2349075203 XBRTECU_MsgChecksum "MsgChecksum";
BA_ "SeToolOwnerSigGroupID_SIGNAL" SG_ 2349075203 XBRTECU_MsgChecksum "x0000001D043D6E5C";
BA_ "SeToolOwnerSigGroup_SIGNAL" SG_ 2349075203 XBRTECU_MsgChecksum "XBRTECU";
BA_ "SeToolVersion_SIGNAL" SG_ 2349075203 XBRTECU_MsgChecksum "1";
BA_ "GenSigSendType" SG_ 2349075203 XBRTECU_EBIMode 1;
BA_ "GenSigStartValue" SG_ 2349075203 XBRTECU_EBIMode 3;
BA_ "Platform_VMCU1_Sig" SG_ 2349075203 XBRTECU_EBIMode 1;
BA_ "SPN" SG_ 2349075203 XBRTECU_EBIMode 2914;
BA_ "SeToolAncestorID_SIGNAL" SG_ 2349075203 XBRTECU_EBIMode "x0000001D0410D0BE";
BA_ "SeToolItemID_SIGNAL" SG_ 2349075203 XBRTECU_EBIMode "x0000001D0410D0BE";
BA_ "SeToolName_SIGNAL" SG_ 2349075203 XBRTECU_EBIMode "EBIMode";
BA_ "SeToolOwnerSigGroupID_SIGNAL" SG_ 2349075203 XBRTECU_EBIMode "x0000001D043D6E5C";
BA_ "SeToolOwnerSigGroup_SIGNAL" SG_ 2349075203 XBRTECU_EBIMode "XBRTECU";
BA_ "SeToolVersion_SIGNAL" SG_ 2349075203 XBRTECU_EBIMode "1";
BA_ "GenSigSendType" SG_ 2349075203 XBRTECU_Urgency 1;
BA_ "GenSigStartValue" SG_ 2349075203 XBRTECU_Urgency 255;
BA_ "Platform_VMCU1_Sig" SG_ 2349075203 XBRTECU_Urgency 1;
BA_ "SPN" SG_ 2349075203 XBRTECU_Urgency 4099;
BA_ "SeToolAncestorID_SIGNAL" SG_ 2349075203 XBRTECU_Urgency "x0000001D04162231";
BA_ "SeToolItemID_SIGNAL" SG_ 2349075203 XBRTECU_Urgency "x0000001D04162231";
BA_ "SeToolName_SIGNAL" SG_ 2349075203 XBRTECU_Urgency "Urgency";
BA_ "SeToolOwnerSigGroupID_SIGNAL" SG_ 2349075203 XBRTECU_Urgency "x0000001D043D6E5C";
BA_ "SeToolOwnerSigGroup_SIGNAL" SG_ 2349075203 XBRTECU_Urgency "XBRTECU";
BA_ "SeToolVersion_SIGNAL" SG_ 2349075203 XBRTECU_Urgency "1";
BA_ "GenSigSendType" SG_ 2349075203 XBRTECU_ControlMode 1;
BA_ "GenSigStartValue" SG_ 2349075203 XBRTECU_ControlMode 3;
BA_ "Platform_VMCU1_Sig" SG_ 2349075203 XBRTECU_ControlMode 1;
BA_ "SPN" SG_ 2349075203 XBRTECU_ControlMode 2916;
BA_ "SeToolAncestorID_SIGNAL" SG_ 2349075203 XBRTECU_ControlMode "x0000001D0415DF83";
BA_ "SeToolItemID_SIGNAL" SG_ 2349075203 XBRTECU_ControlMode "x0000001D0415DF83";
BA_ "SeToolName_SIGNAL" SG_ 2349075203 XBRTECU_ControlMode "ControlMode";
BA_ "SeToolOwnerSigGroupID_SIGNAL" SG_ 2349075203 XBRTECU_ControlMode "x0000001D043D6E5C";
BA_ "SeToolOwnerSigGroup_SIGNAL" SG_ 2349075203 XBRTECU_ControlMode "XBRTECU";
BA_ "SeToolVersion_SIGNAL" SG_ 2349075203 XBRTECU_ControlMode "1";
BA_ "GenSigSendType" SG_ 2349075203 XBRTECU_ExtAccelDemand 1;
BA_ "GenSigStartValue" SG_ 2349075203 XBRTECU_ExtAccelDemand 65535;
BA_ "Platform_VMCU1_Sig" SG_ 2349075203 XBRTECU_ExtAccelDemand 1;
BA_ "SPN" SG_ 2349075203 XBRTECU_ExtAccelDemand 2920;
BA_ "SeToolAncestorID_SIGNAL" SG_ 2349075203 XBRTECU_ExtAccelDemand "x0000001D0410D936";
BA_ "SeToolItemID_SIGNAL" SG_ 2349075203 XBRTECU_ExtAccelDemand "x0000001D0410D936";
BA_ "SeToolName_SIGNAL" SG_ 2349075203 XBRTECU_ExtAccelDemand "ExtAccelDemand";
BA_ "SeToolOwnerSigGroupID_SIGNAL" SG_ 2349075203 XBRTECU_ExtAccelDemand "x0000001D043D6E5C";
BA_ "SeToolOwnerSigGroup_SIGNAL" SG_ 2349075203 XBRTECU_ExtAccelDemand "XBRTECU";
BA_ "SeToolVersion_SIGNAL" SG_ 2349075203 XBRTECU_ExtAccelDemand "1";
BA_ "GenSigSendType" SG_ 2349075203 XBRTECU_MsgCounter 1;
BA_ "Platform_VMCU1_Sig" SG_ 2349075203 XBRTECU_MsgCounter 1;
BA_ "SPN" SG_ 2349075203 XBRTECU_MsgCounter 3189;
BA_ "SeToolAncestorID_SIGNAL" SG_ 2349075203 XBRTECU_MsgCounter "x0000001D043103C8";
BA_ "SeToolItemID_SIGNAL" SG_ 2349075203 XBRTECU_MsgCounter "x0000001D043103C8";
BA_ "SeToolName_SIGNAL" SG_ 2349075203 XBRTECU_MsgCounter "MsgCounter";
BA_ "SeToolOwnerSigGroupID_SIGNAL" SG_ 2349075203 XBRTECU_MsgCounter "x0000001D043D6E5C";
BA_ "SeToolOwnerSigGroup_SIGNAL" SG_ 2349075203 XBRTECU_MsgCounter "XBRTECU";
BA_ "SeToolVersion_SIGNAL" SG_ 2349075203 XBRTECU_MsgCounter "1";
BA_ "GenSigSendType" SG_ 2349075200 XBREMS_ControlMode 1;
BA_ "GenSigStartValue" SG_ 2349075200 XBREMS_ControlMode 3;
BA_ "Platform_VMCU1_Sig" SG_ 2349075200 XBREMS_ControlMode 1;
BA_ "SPN" SG_ 2349075200 XBREMS_ControlMode 2916;
BA_ "GenSigSendType" SG_ 2349075200 XBREMS_MsgCounter 1;
BA_ "GenSigStartValue" SG_ 2349075200 XBREMS_MsgCounter 15;
BA_ "Platform_VMCU1_Sig" SG_ 2349075200 XBREMS_MsgCounter 1;
BA_ "SPN" SG_ 2349075200 XBREMS_MsgCounter 3189;
BA_ "GenSigSendType" SG_ 2349075200 XBREMS_Urgency 1;
BA_ "GenSigStartValue" SG_ 2349075200 XBREMS_Urgency 255;
BA_ "Platform_VMCU1_Sig" SG_ 2349075200 XBREMS_Urgency 1;
BA_ "SPN" SG_ 2349075200 XBREMS_Urgency 4099;
BA_ "GenSigSendType" SG_ 2349075200 XBREMS_EBIMode 1;
BA_ "GenSigStartValue" SG_ 2349075200 XBREMS_EBIMode 3;
BA_ "Platform_VMCU1_Sig" SG_ 2349075200 XBREMS_EBIMode 1;
BA_ "SPN" SG_ 2349075200 XBREMS_EBIMode 2914;
BA_ "GenSigSendType" SG_ 2349075200 XBREMS_ExtAccelDemand 1;
BA_ "GenSigStartValue" SG_ 2349075200 XBREMS_ExtAccelDemand 65535;
BA_ "Platform_VMCU1_Sig" SG_ 2349075200 XBREMS_ExtAccelDemand 1;
BA_ "SPN" SG_ 2349075200 XBREMS_ExtAccelDemand 2920;
BA_ "GenSigSendType" SG_ 2349075200 XBREMS_Priority 1;
BA_ "GenSigStartValue" SG_ 2349075200 XBREMS_Priority 3;
BA_ "Platform_VMCU1_Sig" SG_ 2349075200 XBREMS_Priority 1;
BA_ "SPN" SG_ 2349075200 XBREMS_Priority 2915;
BA_ "GenSigSendType" SG_ 2349075200 XBREMS_MsgChecksum 1;
BA_ "GenSigStartValue" SG_ 2349075200 XBREMS_MsgChecksum 15;
BA_ "Platform_VMCU1_Sig" SG_ 2349075200 XBREMS_MsgChecksum 1;
BA_ "SPN" SG_ 2349075200 XBREMS_MsgChecksum 3188;
BA_ "GenSigSendType" SG_ 2349075373 XBRDACU_Urgency 1;
BA_ "GenSigStartValue" SG_ 2349075373 XBRDACU_Urgency 255;
BA_ "Platform_VMCU1_Sig" SG_ 2349075373 XBRDACU_Urgency 1;
BA_ "SPN" SG_ 2349075373 XBRDACU_Urgency 4099;
BA_ "SeToolAncestorID_SIGNAL" SG_ 2349075373 XBRDACU_Urgency "x0000001D04162231";
BA_ "SeToolItemID_SIGNAL" SG_ 2349075373 XBRDACU_Urgency "x0000001D04162231";
BA_ "SeToolName_SIGNAL" SG_ 2349075373 XBRDACU_Urgency "Urgency";
BA_ "SeToolOwnerSigGroupID_SIGNAL" SG_ 2349075373 XBRDACU_Urgency "x0000001D043D6E8E";
BA_ "SeToolOwnerSigGroup_SIGNAL" SG_ 2349075373 XBRDACU_Urgency "XBRDACU";
BA_ "SeToolVersion_SIGNAL" SG_ 2349075373 XBRDACU_Urgency "1";
BA_ "GenSigSendType" SG_ 2349075373 XBRDACU_EBIMode 1;
BA_ "GenSigStartValue" SG_ 2349075373 XBRDACU_EBIMode 3;
BA_ "Platform_VMCU1_Sig" SG_ 2349075373 XBRDACU_EBIMode 1;
BA_ "SPN" SG_ 2349075373 XBRDACU_EBIMode 2914;
BA_ "SeToolAncestorID_SIGNAL" SG_ 2349075373 XBRDACU_EBIMode "x0000001D0410D0BE";
BA_ "SeToolItemID_SIGNAL" SG_ 2349075373 XBRDACU_EBIMode "x0000001D0410D0BE";
BA_ "SeToolName_SIGNAL" SG_ 2349075373 XBRDACU_EBIMode "EBIMode";
BA_ "SeToolOwnerSigGroupID_SIGNAL" SG_ 2349075373 XBRDACU_EBIMode "x0000001D043D6E8E";
BA_ "SeToolOwnerSigGroup_SIGNAL" SG_ 2349075373 XBRDACU_EBIMode "XBRDACU";
BA_ "SeToolVersion_SIGNAL" SG_ 2349075373 XBRDACU_EBIMode "1";
BA_ "GenSigSendType" SG_ 2349075373 XBRDACU_ExtAccelDemand 1;
BA_ "GenSigStartValue" SG_ 2349075373 XBRDACU_ExtAccelDemand 65535;
BA_ "Platform_VMCU1_Sig" SG_ 2349075373 XBRDACU_ExtAccelDemand 1;
BA_ "SPN" SG_ 2349075373 XBRDACU_ExtAccelDemand 2920;
BA_ "SeToolAncestorID_SIGNAL" SG_ 2349075373 XBRDACU_ExtAccelDemand "x0000001D0410D936";
BA_ "SeToolItemID_SIGNAL" SG_ 2349075373 XBRDACU_ExtAccelDemand "x0000001D0410D936";
BA_ "SeToolName_SIGNAL" SG_ 2349075373 XBRDACU_ExtAccelDemand "ExtAccelDemand";
BA_ "SeToolOwnerSigGroupID_SIGNAL" SG_ 2349075373 XBRDACU_ExtAccelDemand "x0000001D043D6E8E";
BA_ "SeToolOwnerSigGroup_SIGNAL" SG_ 2349075373 XBRDACU_ExtAccelDemand "XBRDACU";
BA_ "SeToolVersion_SIGNAL" SG_ 2349075373 XBRDACU_ExtAccelDemand "1";
BA_ "GenSigSendType" SG_ 2349075373 XBRDACU_MsgCounter 1;
BA_ "Platform_VMCU1_Sig" SG_ 2349075373 XBRDACU_MsgCounter 1;
BA_ "SPN" SG_ 2349075373 XBRDACU_MsgCounter 3189;
BA_ "SeToolAncestorID_SIGNAL" SG_ 2349075373 XBRDACU_MsgCounter "x0000001D043103C8";
BA_ "SeToolItemID_SIGNAL" SG_ 2349075373 XBRDACU_MsgCounter "x0000001D043103C8";
BA_ "SeToolName_SIGNAL" SG_ 2349075373 XBRDACU_MsgCounter "MsgCounter";
BA_ "SeToolOwnerSigGroupID_SIGNAL" SG_ 2349075373 XBRDACU_MsgCounter "x0000001D043D6E8E";
BA_ "SeToolOwnerSigGroup_SIGNAL" SG_ 2349075373 XBRDACU_MsgCounter "XBRDACU";
BA_ "SeToolVersion_SIGNAL" SG_ 2349075373 XBRDACU_MsgCounter "1";
BA_ "GenSigSendType" SG_ 2349075373 XBRDACU_MsgChecksum 1;
BA_ "Platform_VMCU1_Sig" SG_ 2349075373 XBRDACU_MsgChecksum 1;
BA_ "SPN" SG_ 2349075373 XBRDACU_MsgChecksum 3188;
BA_ "SeToolAncestorID_SIGNAL" SG_ 2349075373 XBRDACU_MsgChecksum "x0000001D043103C0";
BA_ "SeToolItemID_SIGNAL" SG_ 2349075373 XBRDACU_MsgChecksum "x0000001D043103C0";
BA_ "SeToolName_SIGNAL" SG_ 2349075373 XBRDACU_MsgChecksum "MsgChecksum";
BA_ "SeToolOwnerSigGroupID_SIGNAL" SG_ 2349075373 XBRDACU_MsgChecksum "x0000001D043D6E8E";
BA_ "SeToolOwnerSigGroup_SIGNAL" SG_ 2349075373 XBRDACU_MsgChecksum "XBRDACU";
BA_ "SeToolVersion_SIGNAL" SG_ 2349075373 XBRDACU_MsgChecksum "1";
BA_ "GenSigSendType" SG_ 2349075373 XBRDACU_ControlMode 1;
BA_ "GenSigStartValue" SG_ 2349075373 XBRDACU_ControlMode 3;
BA_ "Platform_VMCU1_Sig" SG_ 2349075373 XBRDACU_ControlMode 1;
BA_ "SPN" SG_ 2349075373 XBRDACU_ControlMode 2916;
BA_ "SeToolAncestorID_SIGNAL" SG_ 2349075373 XBRDACU_ControlMode "x0000001D0415DF83";
BA_ "SeToolItemID_SIGNAL" SG_ 2349075373 XBRDACU_ControlMode "x0000001D0415DF83";
BA_ "SeToolName_SIGNAL" SG_ 2349075373 XBRDACU_ControlMode "ControlMode";
BA_ "SeToolOwnerSigGroupID_SIGNAL" SG_ 2349075373 XBRDACU_ControlMode "x0000001D043D6E8E";
BA_ "SeToolOwnerSigGroup_SIGNAL" SG_ 2349075373 XBRDACU_ControlMode "XBRDACU";
BA_ "SeToolVersion_SIGNAL" SG_ 2349075373 XBRDACU_ControlMode "1";
BA_ "GenSigSendType" SG_ 2349075373 XBRDACU_Priority 1;
BA_ "GenSigStartValue" SG_ 2349075373 XBRDACU_Priority 3;
BA_ "Platform_VMCU1_Sig" SG_ 2349075373 XBRDACU_Priority 1;
BA_ "SPN" SG_ 2349075373 XBRDACU_Priority 2915;
BA_ "SeToolAncestorID_SIGNAL" SG_ 2349075373 XBRDACU_Priority "x0000001D0415DF81";
BA_ "SeToolItemID_SIGNAL" SG_ 2349075373 XBRDACU_Priority "x0000001D0415DF81";
BA_ "SeToolName_SIGNAL" SG_ 2349075373 XBRDACU_Priority "Priority";
BA_ "SeToolOwnerSigGroupID_SIGNAL" SG_ 2349075373 XBRDACU_Priority "x0000001D043D6E8E";
BA_ "SeToolOwnerSigGroup_SIGNAL" SG_ 2349075373 XBRDACU_Priority "XBRDACU";
BA_ "SeToolVersion_SIGNAL" SG_ 2349075373 XBRDACU_Priority "1";
BA_ "GenSigSendType" SG_ 2349075430 XBRBBM_Urgency 1;
BA_ "GenSigStartValue" SG_ 2349075430 XBRBBM_Urgency 255;
BA_ "Platform_VMCU1_Sig" SG_ 2349075430 XBRBBM_Urgency 1;
BA_ "SPN" SG_ 2349075430 XBRBBM_Urgency 4099;
BA_ "GenSigSendType" SG_ 2349075430 XBRBBM_ControlMode 1;
BA_ "Platform_VMCU1_Sig" SG_ 2349075430 XBRBBM_ControlMode 1;
BA_ "SPN" SG_ 2349075430 XBRBBM_ControlMode 2916;
BA_ "GenSigSendType" SG_ 2349075430 XBRBBM_Priority 1;
BA_ "GenSigStartValue" SG_ 2349075430 XBRBBM_Priority 3;
BA_ "Platform_VMCU1_Sig" SG_ 2349075430 XBRBBM_Priority 1;
BA_ "SPN" SG_ 2349075430 XBRBBM_Priority 2915;
BA_ "GenSigSendType" SG_ 2349075430 XBRBBM_MsgCounter 1;
BA_ "Platform_VMCU1_Sig" SG_ 2349075430 XBRBBM_MsgCounter 1;
BA_ "SPN" SG_ 2349075430 XBRBBM_MsgCounter 3189;
BA_ "GenSigSendType" SG_ 2349075430 XBRBBM_MsgChecksum 1;
BA_ "Platform_VMCU1_Sig" SG_ 2349075430 XBRBBM_MsgChecksum 1;
BA_ "SPN" SG_ 2349075430 XBRBBM_MsgChecksum 3188;
BA_ "GenSigSendType" SG_ 2349075430 XBRBBM_EBIMode 1;
BA_ "Platform_VMCU1_Sig" SG_ 2349075430 XBRBBM_EBIMode 1;
BA_ "SPN" SG_ 2349075430 XBRBBM_EBIMode 2914;
BA_ "GenSigSendType" SG_ 2349075430 XBRBBM_ExtAccelDemand 1;
BA_ "GenSigStartValue" SG_ 2349075430 XBRBBM_ExtAccelDemand 65535;
BA_ "Platform_VMCU1_Sig" SG_ 2349075430 XBRBBM_ExtAccelDemand 1;
BA_ "SPN" SG_ 2349075430 XBRBBM_ExtAccelDemand 2920;
BA_ "GenSigCycleTime" SG_ 2566848256 WaterInFuelAlarm_ISig_3 100;
BA_ "GenSigCycleTimeActive" SG_ 2566848256 WaterInFuelAlarm_ISig_3 100;
BA_ "GenSigStartValue" SG_ 2566848256 WaterInFuelAlarm_ISig_3 3;
BA_ "Platform_VMCU1_Sig" SG_ 2566848256 WaterInFuelAlarm_ISig_3 1;
BA_ "SPN" SG_ 2566848256 WaterInFuelAlarm_ISig_3 97;
BA_ "SeToolAncestorID_SIGNAL" SG_ 2566848256 WaterInFuelAlarm_ISig_3 "x0000001D041412F3";
BA_ "SeToolItemID_SIGNAL" SG_ 2566848256 WaterInFuelAlarm_ISig_3 "x0000001D041412F3";
BA_ "SeToolName_SIGNAL" SG_ 2566848256 WaterInFuelAlarm_ISig_3 "WaterInFuelAlarm";
BA_ "SeToolVersion_SIGNAL" SG_ 2566848256 WaterInFuelAlarm_ISig_3 "1";
BA_ "GenSigSendType" SG_ 2499751697 TrailerConnected_UB_ISig_3 7;
BA_ "Platform_VMCU1_Sig" SG_ 2499751697 TrailerConnected_UB_ISig_3 1;
BA_ "GenSigCycleTime" SG_ 2499751697 RearAxle2DiffLock_stat_ISig_3 100;
BA_ "GenSigCycleTimeActive" SG_ 2499751697 RearAxle2DiffLock_stat_ISig_3 100;
BA_ "GenSigStartValue" SG_ 2499751697 RearAxle2DiffLock_stat_ISig_3 3;
BA_ "GenSigMaxLatency" SG_ 2499751697 RearAxle2DiffLock_stat_ISig_3 35;
BA_ "NeedsUpdateBit" SG_ 2499751697 RearAxle2DiffLock_stat_ISig_3 1;
BA_ "Platform_VMCU1_Sig" SG_ 2499751697 RearAxle2DiffLock_stat_ISig_3 1;
BA_ "SeToolAncestorID_SIGNAL" SG_ 2499751697 RearAxle2DiffLock_stat_ISig_3 "x0000001D04128800";
BA_ "SeToolItemID_SIGNAL" SG_ 2499751697 RearAxle2DiffLock_stat_ISig_3 "x0000001D04128800";
BA_ "SeToolName_SIGNAL" SG_ 2499751697 RearAxle2DiffLock_stat_ISig_3 "DifferentialLockState-RearAxle2";
BA_ "SeToolVersion_SIGNAL" SG_ 2499751697 RearAxle2DiffLock_stat_ISig_3 "1";
BA_ "GenSigCycleTime" SG_ 2499751697 EngineStopReqBackup 100;
BA_ "GenSigCycleTimeActive" SG_ 2499751697 EngineStopReqBackup 100;
BA_ "GenSigStartValue" SG_ 2499751697 EngineStopReqBackup 3;
BA_ "GenSigMaxLatency" SG_ 2499751697 EngineStopReqBackup 100;
BA_ "Platform_VMCU1_Sig" SG_ 2499751697 EngineStopReqBackup 1;
BA_ "GenSigCycleTime" SG_ 2499751697 DifferentialLockStateCentral_ISi 100;
BA_ "GenSigCycleTimeActive" SG_ 2499751697 DifferentialLockStateCentral_ISi 100;
BA_ "GenSigStartValue" SG_ 2499751697 DifferentialLockStateCentral_ISi 3;
BA_ "Platform_VMCU1_Sig" SG_ 2499751697 DifferentialLockStateCentral_ISi 1;
BA_ "SystemSignalLongSymbol" SG_ 2499751697 DifferentialLockStateCentral_ISi "DifferentialLockStateCentral_ISig_3";
BA_ "GenSigSendType" SG_ 2499751697 RearAxle2DiffLock_stat_UB_ISig_3 7;
BA_ "Platform_VMCU1_Sig" SG_ 2499751697 RearAxle2DiffLock_stat_UB_ISig_3 1;
BA_ "GenSigCycleTime" SG_ 2499751697 RearPropulsionStat_Rear1Axle_ISi 100;
BA_ "GenSigCycleTimeActive" SG_ 2499751697 RearPropulsionStat_Rear1Axle_ISi 100;
BA_ "GenSigStartValue" SG_ 2499751697 RearPropulsionStat_Rear1Axle_ISi 15;
BA_ "Platform_VMCU1_Sig" SG_ 2499751697 RearPropulsionStat_Rear1Axle_ISi 1;
BA_ "SystemSignalLongSymbol" SG_ 2499751697 RearPropulsionStat_Rear1Axle_ISi "RearPropulsionStat_Rear1Axle_ISig_3";
BA_ "GenSigCycleTime" SG_ 2499751697 DifferentialLockStateCentral2 100;
BA_ "GenSigCycleTimeActive" SG_ 2499751697 DifferentialLockStateCentral2 100;
BA_ "GenSigStartValue" SG_ 2499751697 DifferentialLockStateCentral2 3;
BA_ "Platform_VMCU1_Sig" SG_ 2499751697 DifferentialLockStateCentral2 1;
BA_ "GenSigCycleTime" SG_ 2499751697 SetHSAOperation_ISig_3 100;
BA_ "GenSigCycleTimeActive" SG_ 2499751697 SetHSAOperation_ISig_3 100;
BA_ "GenSigStartValue" SG_ 2499751697 SetHSAOperation_ISig_3 7;
BA_ "Platform_VMCU1_Sig" SG_ 2499751697 SetHSAOperation_ISig_3 1;
BA_ "GenSigCycleTime" SG_ 2499751697 CentralRearDiffLock_stat_ISig_3 100;
BA_ "GenSigCycleTimeActive" SG_ 2499751697 CentralRearDiffLock_stat_ISig_3 100;
BA_ "GenSigStartValue" SG_ 2499751697 CentralRearDiffLock_stat_ISig_3 3;
BA_ "GenSigMaxLatency" SG_ 2499751697 CentralRearDiffLock_stat_ISig_3 35;
BA_ "NeedsUpdateBit" SG_ 2499751697 CentralRearDiffLock_stat_ISig_3 1;
BA_ "Platform_VMCU1_Sig" SG_ 2499751697 CentralRearDiffLock_stat_ISig_3 1;
BA_ "SeToolAncestorID_SIGNAL" SG_ 2499751697 CentralRearDiffLock_stat_ISig_3 "x0000001D04119DA2";
BA_ "SeToolItemID_SIGNAL" SG_ 2499751697 CentralRearDiffLock_stat_ISig_3 "x0000001D04119DA2";
BA_ "SeToolName_SIGNAL" SG_ 2499751697 CentralRearDiffLock_stat_ISig_3 "Differential LockState-CentralRear";
BA_ "SeToolVersion_SIGNAL" SG_ 2499751697 CentralRearDiffLock_stat_ISig_3 "1";
BA_ "GenSigCycleTime" SG_ 2499751697 LowAirPressureAlert_ISig_3 100;
BA_ "GenSigCycleTimeActive" SG_ 2499751697 LowAirPressureAlert_ISig_3 100;
BA_ "GenSigStartValue" SG_ 2499751697 LowAirPressureAlert_ISig_3 3;
BA_ "GenSigMaxLatency" SG_ 2499751697 LowAirPressureAlert_ISig_3 35;
BA_ "Platform_VMCU1_Sig" SG_ 2499751697 LowAirPressureAlert_ISig_3 1;
BA_ "SeToolAncestorID_SIGNAL" SG_ 2499751697 LowAirPressureAlert_ISig_3 "x0000001D0414980D";
BA_ "SeToolItemID_SIGNAL" SG_ 2499751697 LowAirPressureAlert_ISig_3 "x0000001D04357133";
BA_ "SeToolName_SIGNAL" SG_ 2499751697 LowAirPressureAlert_ISig_3 "LowAirPressureAlert";
BA_ "SeToolVersion_SIGNAL" SG_ 2499751697 LowAirPressureAlert_ISig_3 "2";
BA_ "GenSigCycleTime" SG_ 2499751697 RearPropulsionStat_Rear3Axle_ISi 100;
BA_ "GenSigCycleTimeActive" SG_ 2499751697 RearPropulsionStat_Rear3Axle_ISi 100;
BA_ "GenSigStartValue" SG_ 2499751697 RearPropulsionStat_Rear3Axle_ISi 15;
BA_ "Platform_VMCU1_Sig" SG_ 2499751697 RearPropulsionStat_Rear3Axle_ISi 1;
BA_ "SystemSignalLongSymbol" SG_ 2499751697 RearPropulsionStat_Rear3Axle_ISi "RearPropulsionStat_Rear3Axle_ISig_3";
BA_ "GenSigCycleTime" SG_ 2499751697 DifferentialLockStateFrAxle2 100;
BA_ "GenSigCycleTimeActive" SG_ 2499751697 DifferentialLockStateFrAxle2 100;
BA_ "GenSigStartValue" SG_ 2499751697 DifferentialLockStateFrAxle2 3;
BA_ "Platform_VMCU1_Sig" SG_ 2499751697 DifferentialLockStateFrAxle2 1;
BA_ "GenSigCycleTime" SG_ 2499751697 TrailerConnected_ISig_3 100;
BA_ "GenSigCycleTimeActive" SG_ 2499751697 TrailerConnected_ISig_3 100;
BA_ "GenSigStartValue" SG_ 2499751697 TrailerConnected_ISig_3 3;
BA_ "NeedsUpdateBit" SG_ 2499751697 TrailerConnected_ISig_3 1;
BA_ "Platform_VMCU1_Sig" SG_ 2499751697 TrailerConnected_ISig_3 1;
BA_ "GenSigCycleTime" SG_ 2499751697 TrailerWithoutABS_ISig_3 100;
BA_ "GenSigCycleTimeActive" SG_ 2499751697 TrailerWithoutABS_ISig_3 100;
BA_ "GenSigStartValue" SG_ 2499751697 TrailerWithoutABS_ISig_3 3;
BA_ "NeedsUpdateBit" SG_ 2499751697 TrailerWithoutABS_ISig_3 1;
BA_ "Platform_VMCU1_Sig" SG_ 2499751697 TrailerWithoutABS_ISig_3 1;
BA_ "SeToolAncestorID_SIGNAL" SG_ 2499751697 TrailerWithoutABS_ISig_3 "x0000001D0410CF7C";
BA_ "SeToolItemID_SIGNAL" SG_ 2499751697 TrailerWithoutABS_ISig_3 "x0000001D0410CF7C";
BA_ "SeToolName_SIGNAL" SG_ 2499751697 TrailerWithoutABS_ISig_3 "TrailerWithoutABS";
BA_ "SeToolVersion_SIGNAL" SG_ 2499751697 TrailerWithoutABS_ISig_3 "1";
BA_ "GenSigSendType" SG_ 2499751697 DifferentialLockStateFrAxle1_UB_ 7;
BA_ "Platform_VMCU1_Sig" SG_ 2499751697 DifferentialLockStateFrAxle1_UB_ 1;
BA_ "SystemSignalLongSymbol" SG_ 2499751697 DifferentialLockStateFrAxle1_UB_ "DifferentialLockStateFrAxle1_UB_ISig_3";
BA_ "GenSigCycleTime" SG_ 2499751697 DifferentialLockStateFrAxle1_ISi 100;
BA_ "GenSigCycleTimeActive" SG_ 2499751697 DifferentialLockStateFrAxle1_ISi 100;
BA_ "GenSigStartValue" SG_ 2499751697 DifferentialLockStateFrAxle1_ISi 3;
BA_ "NeedsUpdateBit" SG_ 2499751697 DifferentialLockStateFrAxle1_ISi 1;
BA_ "Platform_VMCU1_Sig" SG_ 2499751697 DifferentialLockStateFrAxle1_ISi 1;
BA_ "SystemSignalLongSymbol" SG_ 2499751697 DifferentialLockStateFrAxle1_ISi "DifferentialLockStateFrAxle1_ISig_3";
BA_ "GenSigSendType" SG_ 2499751697 RearAxle1DiffLock_stat_UB_ISig_3 7;
BA_ "Platform_VMCU1_Sig" SG_ 2499751697 RearAxle1DiffLock_stat_UB_ISig_3 1;
BA_ "GenSigCycleTime" SG_ 2499751697 RearPropulsionStat_Rear2Axle_ISi 100;
BA_ "GenSigCycleTimeActive" SG_ 2499751697 RearPropulsionStat_Rear2Axle_ISi 100;
BA_ "GenSigStartValue" SG_ 2499751697 RearPropulsionStat_Rear2Axle_ISi 15;
BA_ "Platform_VMCU1_Sig" SG_ 2499751697 RearPropulsionStat_Rear2Axle_ISi 1;
BA_ "SystemSignalLongSymbol" SG_ 2499751697 RearPropulsionStat_Rear2Axle_ISi "RearPropulsionStat_Rear2Axle_ISig_3";
BA_ "GenSigSendType" SG_ 2499751697 CentralRearDiffLock_stat_UB_ISig 7;
BA_ "Platform_VMCU1_Sig" SG_ 2499751697 CentralRearDiffLock_stat_UB_ISig 1;
BA_ "SystemSignalLongSymbol" SG_ 2499751697 CentralRearDiffLock_stat_UB_ISig "CentralRearDiffLock_stat_UB_ISig_3";
BA_ "GenSigCycleTime" SG_ 2499751697 RearAxle1DiffLock_stat_ISig_3 100;
BA_ "GenSigCycleTimeActive" SG_ 2499751697 RearAxle1DiffLock_stat_ISig_3 100;
BA_ "GenSigStartValue" SG_ 2499751697 RearAxle1DiffLock_stat_ISig_3 3;
BA_ "GenSigMaxLatency" SG_ 2499751697 RearAxle1DiffLock_stat_ISig_3 35;
BA_ "NeedsUpdateBit" SG_ 2499751697 RearAxle1DiffLock_stat_ISig_3 1;
BA_ "Platform_VMCU1_Sig" SG_ 2499751697 RearAxle1DiffLock_stat_ISig_3 1;
BA_ "SeToolAncestorID_SIGNAL" SG_ 2499751697 RearAxle1DiffLock_stat_ISig_3 "x0000001D041287FE";
BA_ "SeToolItemID_SIGNAL" SG_ 2499751697 RearAxle1DiffLock_stat_ISig_3 "x0000001D043FB883";
BA_ "SeToolName_SIGNAL" SG_ 2499751697 RearAxle1DiffLock_stat_ISig_3 "DifferentialLockState-RearAxle1";
BA_ "SeToolVersion_SIGNAL" SG_ 2499751697 RearAxle1DiffLock_stat_ISig_3 "2";
BA_ "GenSigSendType" SG_ 2499751697 TrailerWithoutABS_UB_ISig_3 7;
BA_ "Platform_VMCU1_Sig" SG_ 2499751697 TrailerWithoutABS_UB_ISig_3 1;
BA_ "GenSigCycleTime" SG_ 2566897425 StretchBrakeEnable_rqst 100;
BA_ "GenSigCycleTimeActive" SG_ 2566897425 StretchBrakeEnable_rqst 100;
BA_ "GenSigStartValue" SG_ 2566897425 StretchBrakeEnable_rqst 7;
BA_ "Platform_VMCU1_Sig" SG_ 2566897425 StretchBrakeEnable_rqst 1;
BA_ "GenSigCycleTime" SG_ 2566897425 FuelLevel_ISig_3 100;
BA_ "GenSigCycleTimeActive" SG_ 2566897425 FuelLevel_ISig_3 100;
BA_ "GenSigStartValue" SG_ 2566897425 FuelLevel_ISig_3 255;
BA_ "GenSigMaxLatency" SG_ 2566897425 FuelLevel_ISig_3 510;
BA_ "NeedsUpdateBit" SG_ 2566897425 FuelLevel_ISig_3 1;
BA_ "Platform_VMCU1_Sig" SG_ 2566897425 FuelLevel_ISig_3 1;
BA_ "SeToolAncestorID_SIGNAL" SG_ 2566897425 FuelLevel_ISig_3 "x0000001D0416974D";
BA_ "SeToolItemID_SIGNAL" SG_ 2566897425 FuelLevel_ISig_3 "x0000001D0416974D";
BA_ "SeToolName_SIGNAL" SG_ 2566897425 FuelLevel_ISig_3 "FuelLevel";
BA_ "SeToolVersion_SIGNAL" SG_ 2566897425 FuelLevel_ISig_3 "1";
BA_ "GenSigCycleTime" SG_ 2566897425 StaticTrailerBrake_rqst 100;
BA_ "GenSigCycleTimeActive" SG_ 2566897425 StaticTrailerBrake_rqst 100;
BA_ "GenSigStartValue" SG_ 2566897425 StaticTrailerBrake_rqst 3;
BA_ "Platform_VMCU1_Sig" SG_ 2566897425 StaticTrailerBrake_rqst 1;
BA_ "GenSigSendType" SG_ 2566897425 FuelLevel_UB_ISig_3 7;
BA_ "Platform_VMCU1_Sig" SG_ 2566897425 FuelLevel_UB_ISig_3 1;
BA_ "GenSigSendType" SG_ 2298429457 BrakePressureSensorDemand_UB_ISi 7;
BA_ "Platform_VMCU1_Sig" SG_ 2298429457 BrakePressureSensorDemand_UB_ISi 1;
BA_ "SystemSignalLongSymbol" SG_ 2298429457 BrakePressureSensorDemand_UB_ISi "BrakePressureSensorDemand_UB_ISig_3";
BA_ "GenSigCycleTime" SG_ 2298429457 SWBrakeSwitch_ISig_3 100;
BA_ "GenSigCycleTimeActive" SG_ 2298429457 SWBrakeSwitch_ISig_3 100;
BA_ "GenSigStartValue" SG_ 2298429457 SWBrakeSwitch_ISig_3 3;
BA_ "GenSigMaxLatency" SG_ 2298429457 SWBrakeSwitch_ISig_3 35;
BA_ "NeedsUpdateBit" SG_ 2298429457 SWBrakeSwitch_ISig_3 1;
BA_ "Platform_VMCU1_Sig" SG_ 2298429457 SWBrakeSwitch_ISig_3 1;
BA_ "SeToolAncestorID_SIGNAL" SG_ 2298429457 SWBrakeSwitch_ISig_3 "x0000001D0432AB74";
BA_ "SeToolItemID_SIGNAL" SG_ 2298429457 SWBrakeSwitch_ISig_3 "x0000001D0432AB74";
BA_ "SeToolName_SIGNAL" SG_ 2298429457 SWBrakeSwitch_ISig_3 "SWBrakeSwitch";
BA_ "SeToolVersion_SIGNAL" SG_ 2298429457 SWBrakeSwitch_ISig_3 "1";
BA_ "GenSigCycleTime" SG_ 2298429457 ClutchPedalPosition_ISig_3 100;
BA_ "GenSigCycleTimeActive" SG_ 2298429457 ClutchPedalPosition_ISig_3 100;
BA_ "GenSigStartValue" SG_ 2298429457 ClutchPedalPosition_ISig_3 255;
BA_ "Platform_VMCU1_Sig" SG_ 2298429457 ClutchPedalPosition_ISig_3 1;
BA_ "GenSigCycleTime" SG_ 2298429457 TransmissionOutputShaftSpeed_ISi 100;
BA_ "GenSigCycleTimeActive" SG_ 2298429457 TransmissionOutputShaftSpeed_ISi 100;
BA_ "GenSigStartValue" SG_ 2298429457 TransmissionOutputShaftSpeed_ISi 65535;
BA_ "Platform_VMCU1_Sig" SG_ 2298429457 TransmissionOutputShaftSpeed_ISi 1;
BA_ "SeToolAncestorID_SIGNAL" SG_ 2298429457 TransmissionOutputShaftSpeed_ISi "x0000001D0412AAA9";
BA_ "SeToolItemID_SIGNAL" SG_ 2298429457 TransmissionOutputShaftSpeed_ISi "x0000001D0412AAA9";
BA_ "SeToolName_SIGNAL" SG_ 2298429457 TransmissionOutputShaftSpeed_ISi "TransmissionOutputShaftSpeed";
BA_ "SeToolVersion_SIGNAL" SG_ 2298429457 TransmissionOutputShaftSpeed_ISi "1";
BA_ "SystemSignalLongSymbol" SG_ 2298429457 TransmissionOutputShaftSpeed_ISi "TransmissionOutputShaftSpeed_ISig_3";
BA_ "GenSigSendType" SG_ 2298429457 SWBrakeSwitch_UB_ISig_3 7;
BA_ "Platform_VMCU1_Sig" SG_ 2298429457 SWBrakeSwitch_UB_ISig_3 1;
BA_ "GenSigCycleTime" SG_ 2298429457 VehicleMode_ISig_3 100;
BA_ "GenSigCycleTimeActive" SG_ 2298429457 VehicleMode_ISig_3 100;
BA_ "GenSigStartValue" SG_ 2298429457 VehicleMode_ISig_3 15;
BA_ "NeedsUpdateBit" SG_ 2298429457 VehicleMode_ISig_3 1;
BA_ "Platform_VMCU1_Sig" SG_ 2298429457 VehicleMode_ISig_3 1;
BA_ "GenSigCycleTime" SG_ 2298429457 AcctrPedalKickDownSw_stat_ISig_3 100;
BA_ "GenSigCycleTimeActive" SG_ 2298429457 AcctrPedalKickDownSw_stat_ISig_3 100;
BA_ "GenSigStartValue" SG_ 2298429457 AcctrPedalKickDownSw_stat_ISig_3 3;
BA_ "GenSigMaxLatency" SG_ 2298429457 AcctrPedalKickDownSw_stat_ISig_3 35;
BA_ "Platform_VMCU1_Sig" SG_ 2298429457 AcctrPedalKickDownSw_stat_ISig_3 1;
BA_ "SeToolAncestorID_SIGNAL" SG_ 2298429457 AcctrPedalKickDownSw_stat_ISig_3 "x0000001D0414E38D";
BA_ "SeToolItemID_SIGNAL" SG_ 2298429457 AcctrPedalKickDownSw_stat_ISig_3 "x0000001D0428D480";
BA_ "SeToolName_SIGNAL" SG_ 2298429457 AcctrPedalKickDownSw_stat_ISig_3 "AcceleratorPedalKickDwnSwtchStat";
BA_ "SeToolVersion_SIGNAL" SG_ 2298429457 AcctrPedalKickDownSw_stat_ISig_3 "2";
BA_ "GenSigCycleTime" SG_ 2298429457 BrakePedalPosition_ISig_3 100;
BA_ "GenSigCycleTimeActive" SG_ 2298429457 BrakePedalPosition_ISig_3 100;
BA_ "GenSigStartValue" SG_ 2298429457 BrakePedalPosition_ISig_3 255;
BA_ "GenSigMaxLatency" SG_ 2298429457 BrakePedalPosition_ISig_3 100;
BA_ "Platform_VMCU1_Sig" SG_ 2298429457 BrakePedalPosition_ISig_3 1;
BA_ "SeToolAncestorID_SIGNAL" SG_ 2298429457 BrakePedalPosition_ISig_3 "x0000001D04104A99";
BA_ "SeToolItemID_SIGNAL" SG_ 2298429457 BrakePedalPosition_ISig_3 "x0000001D04104A99";
BA_ "SeToolName_SIGNAL" SG_ 2298429457 BrakePedalPosition_ISig_3 "BrakePedalPosition";
BA_ "SeToolVersion_SIGNAL" SG_ 2298429457 BrakePedalPosition_ISig_3 "1";
BA_ "GenSigSendType" SG_ 2298429457 VehicleMode_UB_ISig_3 7;
BA_ "Platform_VMCU1_Sig" SG_ 2298429457 VehicleMode_UB_ISig_3 1;
BA_ "GenSigCycleTime" SG_ 2298429457 BrakePressureSensorDemand_ISig_3 100;
BA_ "GenSigCycleTimeActive" SG_ 2298429457 BrakePressureSensorDemand_ISig_3 100;
BA_ "GenSigStartValue" SG_ 2298429457 BrakePressureSensorDemand_ISig_3 255;
BA_ "GenSigMaxLatency" SG_ 2298429457 BrakePressureSensorDemand_ISig_3 35;
BA_ "NeedsUpdateBit" SG_ 2298429457 BrakePressureSensorDemand_ISig_3 1;
BA_ "Platform_VMCU1_Sig" SG_ 2298429457 BrakePressureSensorDemand_ISig_3 1;
BA_ "SeToolAncestorID_SIGNAL" SG_ 2298429457 BrakePressureSensorDemand_ISig_3 "x0000001D0422D695";
BA_ "SeToolItemID_SIGNAL" SG_ 2298429457 BrakePressureSensorDemand_ISig_3 "x0000001D042FD0DC";
BA_ "SeToolName_SIGNAL" SG_ 2298429457 BrakePressureSensorDemand_ISig_3 "BrakePressureSensorDemand";
BA_ "SeToolVersion_SIGNAL" SG_ 2298429457 BrakePressureSensorDemand_ISig_3 "2";
BA_ "GenSigCycleTime" SG_ 2298429457 AcceleratorPedalLowIdleSwitch_IS 100;
BA_ "GenSigCycleTimeActive" SG_ 2298429457 AcceleratorPedalLowIdleSwitch_IS 100;
BA_ "GenSigStartValue" SG_ 2298429457 AcceleratorPedalLowIdleSwitch_IS 3;
BA_ "Platform_VMCU1_Sig" SG_ 2298429457 AcceleratorPedalLowIdleSwitch_IS 1;
BA_ "SeToolAncestorID_SIGNAL" SG_ 2298429457 AcceleratorPedalLowIdleSwitch_IS "x0000001D0414E508";
BA_ "SeToolItemID_SIGNAL" SG_ 2298429457 AcceleratorPedalLowIdleSwitch_IS "x0000001D0414E508";
BA_ "SeToolName_SIGNAL" SG_ 2298429457 AcceleratorPedalLowIdleSwitch_IS "AcceleratorPedalLowIdleSwitch";
BA_ "SeToolVersion_SIGNAL" SG_ 2298429457 AcceleratorPedalLowIdleSwitch_IS "1";
BA_ "SystemSignalLongSymbol" SG_ 2298429457 AcceleratorPedalLowIdleSwitch_IS "AcceleratorPedalLowIdleSwitch_ISig_3";
BA_ "GenSigCycleTime" SG_ 2298429457 AcceleratorPedalPosition1_ISig_3 100;
BA_ "GenSigCycleTimeActive" SG_ 2298429457 AcceleratorPedalPosition1_ISig_3 100;
BA_ "GenSigStartValue" SG_ 2298429457 AcceleratorPedalPosition1_ISig_3 255;
BA_ "GenSigMaxLatency" SG_ 2298429457 AcceleratorPedalPosition1_ISig_3 35;
BA_ "Platform_VMCU1_Sig" SG_ 2298429457 AcceleratorPedalPosition1_ISig_3 1;
BA_ "SeToolAncestorID_SIGNAL" SG_ 2298429457 AcceleratorPedalPosition1_ISig_3 "x0000001D0410BACD";
BA_ "SeToolItemID_SIGNAL" SG_ 2298429457 AcceleratorPedalPosition1_ISig_3 "x0000001D04227E9E";
BA_ "SeToolName_SIGNAL" SG_ 2298429457 AcceleratorPedalPosition1_ISig_3 "AcceleratorPedalPosition1";
BA_ "SeToolVersion_SIGNAL" SG_ 2298429457 AcceleratorPedalPosition1_ISig_3 "2";
BA_ "GenSigSendType" SG_ 2566906094 RemningTimeTillNxtWklyRestPrd_IS 1;
BA_ "GenSigCycleTime" SG_ 2566906094 RemningTimeTillNxtWklyRestPrd_IS 100;
BA_ "GenSigCycleTimeActive" SG_ 2566906094 RemningTimeTillNxtWklyRestPrd_IS 100;
BA_ "GenSigStartValue" SG_ 2566906094 RemningTimeTillNxtWklyRestPrd_IS 65535;
BA_ "Platform_VMCU1_Sig" SG_ 2566906094 RemningTimeTillNxtWklyRestPrd_IS 1;
BA_ "SystemSignalLongSymbol" SG_ 2566906094 RemningTimeTillNxtWklyRestPrd_IS "RemningTimeTillNxtWklyRestPrd_ISig_3";
BA_ "GenSigSendType" SG_ 2566906094 RemainingCurDailyDrivingTime_ISi 1;
BA_ "GenSigCycleTime" SG_ 2566906094 RemainingCurDailyDrivingTime_ISi 100;
BA_ "GenSigCycleTimeActive" SG_ 2566906094 RemainingCurDailyDrivingTime_ISi 100;
BA_ "GenSigStartValue" SG_ 2566906094 RemainingCurDailyDrivingTime_ISi 65535;
BA_ "Platform_VMCU1_Sig" SG_ 2566906094 RemainingCurDailyDrivingTime_ISi 1;
BA_ "SystemSignalLongSymbol" SG_ 2566906094 RemainingCurDailyDrivingTime_ISi "RemainingCurDailyDrivingTime_ISig_3";
BA_ "GenSigSendType" SG_ 2566906094 RemainingCurrentDrivingTime_ISig 1;
BA_ "GenSigCycleTime" SG_ 2566906094 RemainingCurrentDrivingTime_ISig 100;
BA_ "GenSigCycleTimeActive" SG_ 2566906094 RemainingCurrentDrivingTime_ISig 100;
BA_ "GenSigStartValue" SG_ 2566906094 RemainingCurrentDrivingTime_ISig 65535;
BA_ "Platform_VMCU1_Sig" SG_ 2566906094 RemainingCurrentDrivingTime_ISig 1;
BA_ "SystemSignalLongSymbol" SG_ 2566906094 RemainingCurrentDrivingTime_ISig "RemainingCurrentDrivingTime_ISig_3";
BA_ "GenSigSendType" SG_ 2566906094 SingleMultiDriver_ISig_3 1;
BA_ "GenSigCycleTime" SG_ 2566906094 SingleMultiDriver_ISig_3 100;
BA_ "GenSigCycleTimeActive" SG_ 2566906094 SingleMultiDriver_ISig_3 100;
BA_ "GenSigStartValue" SG_ 2566906094 SingleMultiDriver_ISig_3 3;
BA_ "Platform_VMCU1_Sig" SG_ 2566906094 SingleMultiDriver_ISig_3 1;
BA_ "GenSigSendType" SG_ 2566906094 UnknownPeriods_ISig_3 1;
BA_ "GenSigCycleTime" SG_ 2566906094 UnknownPeriods_ISig_3 100;
BA_ "GenSigCycleTimeActive" SG_ 2566906094 UnknownPeriods_ISig_3 100;
BA_ "GenSigStartValue" SG_ 2566906094 UnknownPeriods_ISig_3 3;
BA_ "Platform_VMCU1_Sig" SG_ 2566906094 UnknownPeriods_ISig_3 1;
BA_ "GenSigSendType" SG_ 2566906094 OpenCompensationWeekBfrLast_ISig 1;
BA_ "GenSigCycleTime" SG_ 2566906094 OpenCompensationWeekBfrLast_ISig 100;
BA_ "GenSigCycleTimeActive" SG_ 2566906094 OpenCompensationWeekBfrLast_ISig 100;
BA_ "GenSigStartValue" SG_ 2566906094 OpenCompensationWeekBfrLast_ISig 65535;
BA_ "Platform_VMCU1_Sig" SG_ 2566906094 OpenCompensationWeekBfrLast_ISig 1;
BA_ "SystemSignalLongSymbol" SG_ 2566906094 OpenCompensationWeekBfrLast_ISig "OpenCompensationWeekBfrLast_ISig_3";
BA_ "GenSigSendType" SG_ 2566906094 RemainingReducedDailyRestPrd_ISi 1;
BA_ "GenSigCycleTime" SG_ 2566906094 RemainingReducedDailyRestPrd_ISi 100;
BA_ "GenSigCycleTimeActive" SG_ 2566906094 RemainingReducedDailyRestPrd_ISi 100;
BA_ "GenSigStartValue" SG_ 2566906094 RemainingReducedDailyRestPrd_ISi 7;
BA_ "Platform_VMCU1_Sig" SG_ 2566906094 RemainingReducedDailyRestPrd_ISi 1;
BA_ "SystemSignalLongSymbol" SG_ 2566906094 RemainingReducedDailyRestPrd_ISi "RemainingReducedDailyRestPrd_ISig_3";
BA_ "GenSigSendType" SG_ 2566906094 RemainingDurOfCurBreakRest_ISig_ 1;
BA_ "GenSigCycleTime" SG_ 2566906094 RemainingDurOfCurBreakRest_ISig_ 100;
BA_ "GenSigCycleTimeActive" SG_ 2566906094 RemainingDurOfCurBreakRest_ISig_ 100;
BA_ "GenSigStartValue" SG_ 2566906094 RemainingDurOfCurBreakRest_ISig_ 65535;
BA_ "Platform_VMCU1_Sig" SG_ 2566906094 RemainingDurOfCurBreakRest_ISig_ 1;
BA_ "SystemSignalLongSymbol" SG_ 2566906094 RemainingDurOfCurBreakRest_ISig_ "RemainingDurOfCurBreakRest_ISig_3";
BA_ "GenSigSendType" SG_ 2566906094 RemainingTimeTillNextRestBreak_I 1;
BA_ "GenSigCycleTime" SG_ 2566906094 RemainingTimeTillNextRestBreak_I 100;
BA_ "GenSigCycleTimeActive" SG_ 2566906094 RemainingTimeTillNextRestBreak_I 100;
BA_ "GenSigStartValue" SG_ 2566906094 RemainingTimeTillNextRestBreak_I 65535;
BA_ "Platform_VMCU1_Sig" SG_ 2566906094 RemainingTimeTillNextRestBreak_I 1;
BA_ "SystemSignalLongSymbol" SG_ 2566906094 RemainingTimeTillNextRestBreak_I "RemainingTimeTillNextRestBreak_ISig_3";
BA_ "GenSigSendType" SG_ 2566906094 NextDrivingPeriod_ISig_3 1;
BA_ "GenSigCycleTime" SG_ 2566906094 NextDrivingPeriod_ISig_3 100;
BA_ "GenSigCycleTimeActive" SG_ 2566906094 NextDrivingPeriod_ISig_3 100;
BA_ "GenSigStartValue" SG_ 2566906094 NextDrivingPeriod_ISig_3 65535;
BA_ "Platform_VMCU1_Sig" SG_ 2566906094 NextDrivingPeriod_ISig_3 1;
BA_ "GenSigSendType" SG_ 2566906094 DurationOfNextRestBreak_ISig_3 1;
BA_ "GenSigCycleTime" SG_ 2566906094 DurationOfNextRestBreak_ISig_3 100;
BA_ "GenSigCycleTimeActive" SG_ 2566906094 DurationOfNextRestBreak_ISig_3 100;
BA_ "GenSigStartValue" SG_ 2566906094 DurationOfNextRestBreak_ISig_3 65535;
BA_ "Platform_VMCU1_Sig" SG_ 2566906094 DurationOfNextRestBreak_ISig_3 1;
BA_ "GenSigSendType" SG_ 2566906094 RemainingDrivTimeOfCurWeek_ISig_ 1;
BA_ "GenSigCycleTime" SG_ 2566906094 RemainingDrivTimeOfCurWeek_ISig_ 100;
BA_ "GenSigCycleTimeActive" SG_ 2566906094 RemainingDrivTimeOfCurWeek_ISig_ 100;
BA_ "GenSigStartValue" SG_ 2566906094 RemainingDrivTimeOfCurWeek_ISig_ 65535;
BA_ "Platform_VMCU1_Sig" SG_ 2566906094 RemainingDrivTimeOfCurWeek_ISig_ 1;
BA_ "SystemSignalLongSymbol" SG_ 2566906094 RemainingDrivTimeOfCurWeek_ISig_ "RemainingDrivTimeOfCurWeek_ISig_3";
BA_ "GenSigSendType" SG_ 2566906094 DurationOfNextDailyRestPeriod_IS 1;
BA_ "GenSigCycleTime" SG_ 2566906094 DurationOfNextDailyRestPeriod_IS 100;
BA_ "GenSigCycleTimeActive" SG_ 2566906094 DurationOfNextDailyRestPeriod_IS 100;
BA_ "GenSigStartValue" SG_ 2566906094 DurationOfNextDailyRestPeriod_IS 65535;
BA_ "Platform_VMCU1_Sig" SG_ 2566906094 DurationOfNextDailyRestPeriod_IS 1;
BA_ "SystemSignalLongSymbol" SG_ 2566906094 DurationOfNextDailyRestPeriod_IS "DurationOfNextDailyRestPeriod_ISig_3";
BA_ "GenSigSendType" SG_ 2566906094 OpenCompensationInTheLastWeek_IS 1;
BA_ "GenSigCycleTime" SG_ 2566906094 OpenCompensationInTheLastWeek_IS 100;
BA_ "GenSigCycleTimeActive" SG_ 2566906094 OpenCompensationInTheLastWeek_IS 100;
BA_ "GenSigStartValue" SG_ 2566906094 OpenCompensationInTheLastWeek_IS 65535;
BA_ "Platform_VMCU1_Sig" SG_ 2566906094 OpenCompensationInTheLastWeek_IS 1;
BA_ "SystemSignalLongSymbol" SG_ 2566906094 OpenCompensationInTheLastWeek_IS "OpenCompensationInTheLastWeek_ISig_3";
BA_ "GenSigSendType" SG_ 2566906094 TimeOverlap_ISig_3 1;
BA_ "GenSigStartValue" SG_ 2566906094 TimeOverlap_ISig_3 3;
BA_ "Platform_VMCU1_Sig" SG_ 2566906094 TimeOverlap_ISig_3 1;
BA_ "GenSigSendType" SG_ 2566906094 TimeBeforeStartOfNxtDrvngPrd_ISi 1;
BA_ "GenSigCycleTime" SG_ 2566906094 TimeBeforeStartOfNxtDrvngPrd_ISi 100;
BA_ "GenSigCycleTimeActive" SG_ 2566906094 TimeBeforeStartOfNxtDrvngPrd_ISi 100;
BA_ "GenSigStartValue" SG_ 2566906094 TimeBeforeStartOfNxtDrvngPrd_ISi 65535;
BA_ "Platform_VMCU1_Sig" SG_ 2566906094 TimeBeforeStartOfNxtDrvngPrd_ISi 1;
BA_ "SystemSignalLongSymbol" SG_ 2566906094 TimeBeforeStartOfNxtDrvngPrd_ISi "TimeBeforeStartOfNxtDrvngPrd_ISig_3";
BA_ "GenSigSendType" SG_ 2566906094 WklyRestPrdCalcEnabledDisabled_I 1;
BA_ "GenSigCycleTime" SG_ 2566906094 WklyRestPrdCalcEnabledDisabled_I 100;
BA_ "GenSigCycleTimeActive" SG_ 2566906094 WklyRestPrdCalcEnabledDisabled_I 100;
BA_ "GenSigStartValue" SG_ 2566906094 WklyRestPrdCalcEnabledDisabled_I 3;
BA_ "Platform_VMCU1_Sig" SG_ 2566906094 WklyRestPrdCalcEnabledDisabled_I 1;
BA_ "SystemSignalLongSymbol" SG_ 2566906094 WklyRestPrdCalcEnabledDisabled_I "WklyRestPrdCalcEnabledDisabled_ISig_3";
BA_ "GenSigSendType" SG_ 2566906094 Remaining10hDrvTime_ISig_3 1;
BA_ "GenSigCycleTime" SG_ 2566906094 Remaining10hDrvTime_ISig_3 100;
BA_ "GenSigCycleTimeActive" SG_ 2566906094 Remaining10hDrvTime_ISig_3 100;
BA_ "GenSigStartValue" SG_ 2566906094 Remaining10hDrvTime_ISig_3 7;
BA_ "Platform_VMCU1_Sig" SG_ 2566906094 Remaining10hDrvTime_ISig_3 1;
BA_ "GenSigSendType" SG_ 2566906094 RemnngTimeTillNxtDailyRestPrd_IS 1;
BA_ "GenSigCycleTime" SG_ 2566906094 RemnngTimeTillNxtDailyRestPrd_IS 100;
BA_ "GenSigCycleTimeActive" SG_ 2566906094 RemnngTimeTillNxtDailyRestPrd_IS 100;
BA_ "GenSigStartValue" SG_ 2566906094 RemnngTimeTillNxtDailyRestPrd_IS 65535;
BA_ "Platform_VMCU1_Sig" SG_ 2566906094 RemnngTimeTillNxtDailyRestPrd_IS 1;
BA_ "SystemSignalLongSymbol" SG_ 2566906094 RemnngTimeTillNxtDailyRestPrd_IS "RemnngTimeTillNxtDailyRestPrd_ISig_3";
BA_ "GenSigSendType" SG_ 2566906094 DurationOfNextWeeklyRestPeriod_I 1;
BA_ "GenSigCycleTime" SG_ 2566906094 DurationOfNextWeeklyRestPeriod_I 100;
BA_ "GenSigCycleTimeActive" SG_ 2566906094 DurationOfNextWeeklyRestPeriod_I 100;
BA_ "GenSigStartValue" SG_ 2566906094 DurationOfNextWeeklyRestPeriod_I 65535;
BA_ "Platform_VMCU1_Sig" SG_ 2566906094 DurationOfNextWeeklyRestPeriod_I 1;
BA_ "SystemSignalLongSymbol" SG_ 2566906094 DurationOfNextWeeklyRestPeriod_I "DurationOfNextWeeklyRestPeriod_ISig_3";
BA_ "GenSigSendType" SG_ 2566906094 OpenCompensation2ndWeekBfrLast_I 1;
BA_ "GenSigCycleTime" SG_ 2566906094 OpenCompensation2ndWeekBfrLast_I 100;
BA_ "GenSigCycleTimeActive" SG_ 2566906094 OpenCompensation2ndWeekBfrLast_I 100;
BA_ "GenSigStartValue" SG_ 2566906094 OpenCompensation2ndWeekBfrLast_I 65535;
BA_ "Platform_VMCU1_Sig" SG_ 2566906094 OpenCompensation2ndWeekBfrLast_I 1;
BA_ "SystemSignalLongSymbol" SG_ 2566906094 OpenCompensation2ndWeekBfrLast_I "OpenCompensation2ndWeekBfrLast_ISig_3";
BA_ "GenSigSendType" SG_ 2566906094 SufficientData_ISig_3 1;
BA_ "GenSigCycleTime" SG_ 2566906094 SufficientData_ISig_3 100;
BA_ "GenSigCycleTimeActive" SG_ 2566906094 SufficientData_ISig_3 100;
BA_ "GenSigStartValue" SG_ 2566906094 SufficientData_ISig_3 3;
BA_ "Platform_VMCU1_Sig" SG_ 2566906094 SufficientData_ISig_3 1;
BA_ "GenSigCycleTime" SG_ 2566832401 TotalVehicleDistanceHighRes_ISig 100;
BA_ "GenSigCycleTimeActive" SG_ 2566832401 TotalVehicleDistanceHighRes_ISig 100;
BA_ "GenSigStartValue" SG_ 2566832401 TotalVehicleDistanceHighRes_ISig 4294967295;
BA_ "Platform_VMCU1_Sig" SG_ 2566832401 TotalVehicleDistanceHighRes_ISig 1;
BA_ "SPN" SG_ 2566832401 TotalVehicleDistanceHighRes_ISig 917;
BA_ "SeToolAncestorID_SIGNAL" SG_ 2566832401 TotalVehicleDistanceHighRes_ISig "x0000001D04109E2B";
BA_ "SeToolItemID_SIGNAL" SG_ 2566832401 TotalVehicleDistanceHighRes_ISig "x0000001D04109E2B";
BA_ "SeToolName_SIGNAL" SG_ 2566832401 TotalVehicleDistanceHighRes_ISig "HighResolutionTotalVehicleDistance";
BA_ "SeToolVersion_SIGNAL" SG_ 2566832401 TotalVehicleDistanceHighRes_ISig "1";
BA_ "SystemSignalLongSymbol" SG_ 2566832401 TotalVehicleDistanceHighRes_ISig "TotalVehicleDistanceHighRes_ISig_3";
BA_ "GenSigCycleTime" SG_ 2566832622 TachoHighResTotalVehDistance 100;
BA_ "GenSigCycleTimeActive" SG_ 2566832622 TachoHighResTotalVehDistance 100;
BA_ "GenSigStartValue" SG_ 2566832622 TachoHighResTotalVehDistance 4294967295;
BA_ "Platform_VMCU1_Sig" SG_ 2566832622 TachoHighResTotalVehDistance 1;
BA_ "SPN" SG_ 2566832622 TachoHighResTotalVehDistance 917;
BA_ "SeToolAncestorID_SIGNAL" SG_ 2566832622 TachoHighResTotalVehDistance "x0000001D041A218B";
BA_ "SeToolItemID_SIGNAL" SG_ 2566832622 TachoHighResTotalVehDistance "x0000001D041A218B";
BA_ "SeToolName_SIGNAL" SG_ 2566832622 TachoHighResTotalVehDistance "TachographHighResolutionTotalVehicleDistance";
BA_ "SeToolVersion_SIGNAL" SG_ 2566832622 TachoHighResTotalVehDistance "1";
BA_ "GenSigCycleTime" SG_ 2364541195 LateralAcceleration_ISig_3 100;
BA_ "GenSigCycleTimeActive" SG_ 2364541195 LateralAcceleration_ISig_3 100;
BA_ "GenSigStartValue" SG_ 2364541195 LateralAcceleration_ISig_3 65535;
BA_ "Platform_VMCU1_Sig" SG_ 2364541195 LateralAcceleration_ISig_3 1;
BA_ "SPN" SG_ 2364541195 LateralAcceleration_ISig_3 1809;
BA_ "GenSigCycleTime" SG_ 2364541195 SteeringWheelAngle_ISig_3 100;
BA_ "GenSigCycleTimeActive" SG_ 2364541195 SteeringWheelAngle_ISig_3 100;
BA_ "GenSigStartValue" SG_ 2364541195 SteeringWheelAngle_ISig_3 65535;
BA_ "Platform_VMCU1_Sig" SG_ 2364541195 SteeringWheelAngle_ISig_3 1;
BA_ "SPN" SG_ 2364541195 SteeringWheelAngle_ISig_3 1807;
BA_ "SeToolAncestorID_SIGNAL" SG_ 2364541195 SteeringWheelAngle_ISig_3 "x0000001D041258E9";
BA_ "SeToolItemID_SIGNAL" SG_ 2364541195 SteeringWheelAngle_ISig_3 "x0000001D041258E9";
BA_ "SeToolName_SIGNAL" SG_ 2364541195 SteeringWheelAngle_ISig_3 "SteeringWheelAngle";
BA_ "SeToolVersion_SIGNAL" SG_ 2364541195 SteeringWheelAngle_ISig_3 "1";
BA_ "GenSigCycleTime" SG_ 2364541195 SteeringWheelTurnCounter_ISig_3 100;
BA_ "GenSigCycleTimeActive" SG_ 2364541195 SteeringWheelTurnCounter_ISig_3 100;
BA_ "GenSigStartValue" SG_ 2364541195 SteeringWheelTurnCounter_ISig_3 63;
BA_ "Platform_VMCU1_Sig" SG_ 2364541195 SteeringWheelTurnCounter_ISig_3 1;
BA_ "SPN" SG_ 2364541195 SteeringWheelTurnCounter_ISig_3 1811;
BA_ "GenSigCycleTime" SG_ 2364541195 SteeringWheelAngleSensorType_ISi 100;
BA_ "GenSigCycleTimeActive" SG_ 2364541195 SteeringWheelAngleSensorType_ISi 100;
BA_ "GenSigStartValue" SG_ 2364541195 SteeringWheelAngleSensorType_ISi 3;
BA_ "Platform_VMCU1_Sig" SG_ 2364541195 SteeringWheelAngleSensorType_ISi 1;
BA_ "SPN" SG_ 2364541195 SteeringWheelAngleSensorType_ISi 1812;
BA_ "SystemSignalLongSymbol" SG_ 2364541195 SteeringWheelAngleSensorType_ISi "SteeringWheelAngleSensorType_ISig_3";
BA_ "GenSigCycleTime" SG_ 2364541195 YawRate_ISig_3 100;
BA_ "GenSigCycleTimeActive" SG_ 2364541195 YawRate_ISig_3 100;
BA_ "GenSigStartValue" SG_ 2364541195 YawRate_ISig_3 65535;
BA_ "Platform_VMCU1_Sig" SG_ 2364541195 YawRate_ISig_3 1;
BA_ "SPN" SG_ 2364541195 YawRate_ISig_3 1808;
BA_ "SeToolAncestorID_SIGNAL" SG_ 2364541195 YawRate_ISig_3 "x0000001D04146F42";
BA_ "SeToolItemID_SIGNAL" SG_ 2364541195 YawRate_ISig_3 "x0000001D04146F42";
BA_ "SeToolName_SIGNAL" SG_ 2364541195 YawRate_ISig_3 "YawRate";
BA_ "SeToolVersion_SIGNAL" SG_ 2364541195 YawRate_ISig_3 "1";
BA_ "GenSigCycleTime" SG_ 2566803211 ESCHealthStatus_ISig_3 100;
BA_ "GenSigCycleTimeActive" SG_ 2566803211 ESCHealthStatus_ISig_3 100;
BA_ "GenSigStartValue" SG_ 2566803211 ESCHealthStatus_ISig_3 3;
BA_ "Platform_VMCU1_Sig" SG_ 2566803211 ESCHealthStatus_ISig_3 1;
BA_ "SPN" SG_ 2566803211 ESCHealthStatus_ISig_3 1813;
BA_ "GenSigCycleTime" SG_ 2566803211 ROPEngineControlActive_ISig_3 100;
BA_ "GenSigCycleTimeActive" SG_ 2566803211 ROPEngineControlActive_ISig_3 100;
BA_ "GenSigStartValue" SG_ 2566803211 ROPEngineControlActive_ISig_3 3;
BA_ "Platform_VMCU1_Sig" SG_ 2566803211 ROPEngineControlActive_ISig_3 1;
BA_ "SPN" SG_ 2566803211 ROPEngineControlActive_ISig_3 1816;
BA_ "GenSigCycleTime" SG_ 2566803211 YCEngineControlActive_ISig_3 100;
BA_ "GenSigCycleTimeActive" SG_ 2566803211 YCEngineControlActive_ISig_3 100;
BA_ "GenSigStartValue" SG_ 2566803211 YCEngineControlActive_ISig_3 3;
BA_ "Platform_VMCU1_Sig" SG_ 2566803211 YCEngineControlActive_ISig_3 1;
BA_ "SPN" SG_ 2566803211 YCEngineControlActive_ISig_3 1817;
BA_ "GenSigCycleTime" SG_ 2566803211 ROPBrakeControlActive_ISig_3 100;
BA_ "GenSigCycleTimeActive" SG_ 2566803211 ROPBrakeControlActive_ISig_3 100;
BA_ "GenSigStartValue" SG_ 2566803211 ROPBrakeControlActive_ISig_3 3;
BA_ "Platform_VMCU1_Sig" SG_ 2566803211 ROPBrakeControlActive_ISig_3 1;
BA_ "SPN" SG_ 2566803211 ROPBrakeControlActive_ISig_3 1818;
BA_ "GenSigCycleTime" SG_ 2566803211 YCBrakeControlActive_ISig_3 100;
BA_ "GenSigCycleTimeActive" SG_ 2566803211 YCBrakeControlActive_ISig_3 100;
BA_ "GenSigStartValue" SG_ 2566803211 YCBrakeControlActive_ISig_3 3;
BA_ "Platform_VMCU1_Sig" SG_ 2566803211 YCBrakeControlActive_ISig_3 1;
BA_ "SPN" SG_ 2566803211 YCBrakeControlActive_ISig_3 1819;
BA_ "GenSigCycleTime" SG_ 2566803211 VDCFullyOperational 100;
BA_ "GenSigCycleTimeActive" SG_ 2566803211 VDCFullyOperational 100;
BA_ "GenSigStartValue" SG_ 2566803211 VDCFullyOperational 3;
BA_ "GenSigMaxLatency" SG_ 2566803211 VDCFullyOperational 60;
BA_ "Platform_VMCU1_Sig" SG_ 2566803211 VDCFullyOperational 1;
BA_ "SPN" SG_ 2566803211 VDCFullyOperational 1814;
BA_ "SeToolAncestorID_SIGNAL" SG_ 2566803211 VDCFullyOperational "x0000001D0414256F";
BA_ "SeToolItemID_SIGNAL" SG_ 2566803211 VDCFullyOperational "x0000001D0414256F";
BA_ "SeToolName_SIGNAL" SG_ 2566803211 VDCFullyOperational "VDCFullyOperational";
BA_ "SeToolVersion_SIGNAL" SG_ 2566803211 VDCFullyOperational "1";
BA_ "GenSigSendType" SG_ 2671902706 FuncDiagDataTester_ISig_3 7;
BA_ "Platform_VMCU1_Sig" SG_ 2671902706 FuncDiagDataTester_ISig_3 1;
BA_ "GenSigSendType" SG_ 2348814353 TSC1RECUVMCU_EnRSpdSpdLm 7;
BA_ "GenSigCycleTime" SG_ 2348814353 TSC1RECUVMCU_EnRSpdSpdLm 100;
BA_ "GenSigCycleTimeActive" SG_ 2348814353 TSC1RECUVMCU_EnRSpdSpdLm 100;
BA_ "GenSigStartValue" SG_ 2348814353 TSC1RECUVMCU_EnRSpdSpdLm 65535;
BA_ "Platform_VMCU1_Sig" SG_ 2348814353 TSC1RECUVMCU_EnRSpdSpdLm 1;
BA_ "SPN" SG_ 2348814353 TSC1RECUVMCU_EnRSpdSpdLm 898;
BA_ "GenSigSendType" SG_ 2348814353 TSC1RECUVMCU_EnOvrdCtrlM 6;
BA_ "Platform_VMCU1_Sig" SG_ 2348814353 TSC1RECUVMCU_EnOvrdCtrlM 1;
BA_ "SPN" SG_ 2348814353 TSC1RECUVMCU_EnOvrdCtrlM 695;
BA_ "GenSigSendType" SG_ 2348814353 TSC1RECUVMCU_EnRTrqTrqLm 7;
BA_ "GenSigCycleTime" SG_ 2348814353 TSC1RECUVMCU_EnRTrqTrqLm 100;
BA_ "GenSigCycleTimeActive" SG_ 2348814353 TSC1RECUVMCU_EnRTrqTrqLm 100;
BA_ "GenSigStartValue" SG_ 2348814353 TSC1RECUVMCU_EnRTrqTrqLm 255;
BA_ "Platform_VMCU1_Sig" SG_ 2348814353 TSC1RECUVMCU_EnRTrqTrqLm 1;
BA_ "SPN" SG_ 2348814353 TSC1RECUVMCU_EnRTrqTrqLm 518;
BA_ "GenSigSendType" SG_ 2348814353 TSC1RECUVMCU_EnRSpdCtrlC 7;
BA_ "GenSigCycleTime" SG_ 2348814353 TSC1RECUVMCU_EnRSpdCtrlC 100;
BA_ "GenSigCycleTimeActive" SG_ 2348814353 TSC1RECUVMCU_EnRSpdCtrlC 100;
BA_ "Platform_VMCU1_Sig" SG_ 2348814353 TSC1RECUVMCU_EnRSpdCtrlC 1;
BA_ "SPN" SG_ 2348814353 TSC1RECUVMCU_EnRSpdCtrlC 696;
BA_ "GenSigSendType" SG_ 2348814353 TSC1RECUVMCU_OvrdCtrlMPr 7;
BA_ "GenSigCycleTime" SG_ 2348814353 TSC1RECUVMCU_OvrdCtrlMPr 100;
BA_ "GenSigCycleTimeActive" SG_ 2348814353 TSC1RECUVMCU_OvrdCtrlMPr 100;
BA_ "GenSigStartValue" SG_ 2348814353 TSC1RECUVMCU_OvrdCtrlMPr 3;
BA_ "Platform_VMCU1_Sig" SG_ 2348814353 TSC1RECUVMCU_OvrdCtrlMPr 1;
BA_ "SPN" SG_ 2348814353 TSC1RECUVMCU_OvrdCtrlMPr 897;
BA_ "GenSigSendType" SG_ 2348814339 TSC1RECUTECU_EnRTrqTrqLm 7;
BA_ "GenSigStartValue" SG_ 2348814339 TSC1RECUTECU_EnRTrqTrqLm 255;
BA_ "Platform_VMCU1_Sig" SG_ 2348814339 TSC1RECUTECU_EnRTrqTrqLm 1;
BA_ "SPN" SG_ 2348814339 TSC1RECUTECU_EnRTrqTrqLm 518;
BA_ "GenSigSendType" SG_ 2348814339 TSC1RECUTECU_EnOvrdCtrlM 6;
BA_ "Platform_VMCU1_Sig" SG_ 2348814339 TSC1RECUTECU_EnOvrdCtrlM 1;
BA_ "SPN" SG_ 2348814339 TSC1RECUTECU_EnOvrdCtrlM 695;
BA_ "GenSigSendType" SG_ 2348814339 TSC1RECUTECU_OvrdCtrlMPr 7;
BA_ "GenSigStartValue" SG_ 2348814339 TSC1RECUTECU_OvrdCtrlMPr 3;
BA_ "Platform_VMCU1_Sig" SG_ 2348814339 TSC1RECUTECU_OvrdCtrlMPr 1;
BA_ "SPN" SG_ 2348814339 TSC1RECUTECU_OvrdCtrlMPr 897;
BA_ "GenSigSendType" SG_ 2348814339 TSC1RECUTECU_EnRSpdCtrlC 7;
BA_ "Platform_VMCU1_Sig" SG_ 2348814339 TSC1RECUTECU_EnRSpdCtrlC 1;
BA_ "SPN" SG_ 2348814339 TSC1RECUTECU_EnRSpdCtrlC 696;
BA_ "GenSigSendType" SG_ 2348814339 TSC1RECUTECU_EnRSpdSpdLm 7;
BA_ "GenSigStartValue" SG_ 2348814339 TSC1RECUTECU_EnRSpdSpdLm 65535;
BA_ "Platform_VMCU1_Sig" SG_ 2348814339 TSC1RECUTECU_EnRSpdSpdLm 1;
BA_ "SPN" SG_ 2348814339 TSC1RECUTECU_EnRSpdSpdLm 898;
BA_ "GenSigSendType" SG_ 2348814337 TSC1RECUEMSdap_EnRSpdSpdLm 7;
BA_ "GenSigCycleTime" SG_ 2348814337 TSC1RECUEMSdap_EnRSpdSpdLm 100;
BA_ "GenSigCycleTimeActive" SG_ 2348814337 TSC1RECUEMSdap_EnRSpdSpdLm 100;
BA_ "GenSigStartValue" SG_ 2348814337 TSC1RECUEMSdap_EnRSpdSpdLm 65535;
BA_ "Platform_VMCU1_Sig" SG_ 2348814337 TSC1RECUEMSdap_EnRSpdSpdLm 1;
BA_ "SPN" SG_ 2348814337 TSC1RECUEMSdap_EnRSpdSpdLm 898;
BA_ "GenSigSendType" SG_ 2348814337 TSC1RECUEMSdap_OvrdCtrlMPr 7;
BA_ "GenSigCycleTime" SG_ 2348814337 TSC1RECUEMSdap_OvrdCtrlMPr 100;
BA_ "GenSigCycleTimeActive" SG_ 2348814337 TSC1RECUEMSdap_OvrdCtrlMPr 100;
BA_ "GenSigStartValue" SG_ 2348814337 TSC1RECUEMSdap_OvrdCtrlMPr 3;
BA_ "Platform_VMCU1_Sig" SG_ 2348814337 TSC1RECUEMSdap_OvrdCtrlMPr 1;
BA_ "SPN" SG_ 2348814337 TSC1RECUEMSdap_OvrdCtrlMPr 897;
BA_ "GenSigSendType" SG_ 2348814337 TSC1RECUEMSdap_EnOvrdCtrlM 6;
BA_ "Platform_VMCU1_Sig" SG_ 2348814337 TSC1RECUEMSdap_EnOvrdCtrlM 1;
BA_ "SPN" SG_ 2348814337 TSC1RECUEMSdap_EnOvrdCtrlM 695;
BA_ "GenSigSendType" SG_ 2348814337 TSC1RECUEMSdap_EnRSpdCtrlC 7;
BA_ "GenSigCycleTime" SG_ 2348814337 TSC1RECUEMSdap_EnRSpdCtrlC 100;
BA_ "GenSigCycleTimeActive" SG_ 2348814337 TSC1RECUEMSdap_EnRSpdCtrlC 100;
BA_ "Platform_VMCU1_Sig" SG_ 2348814337 TSC1RECUEMSdap_EnRSpdCtrlC 1;
BA_ "SPN" SG_ 2348814337 TSC1RECUEMSdap_EnRSpdCtrlC 696;
BA_ "GenSigSendType" SG_ 2348814337 TSC1RECUEMSdap_EnRTrqTrqLm 7;
BA_ "GenSigCycleTime" SG_ 2348814337 TSC1RECUEMSdap_EnRTrqTrqLm 100;
BA_ "GenSigCycleTimeActive" SG_ 2348814337 TSC1RECUEMSdap_EnRTrqTrqLm 100;
BA_ "GenSigStartValue" SG_ 2348814337 TSC1RECUEMSdap_EnRTrqTrqLm 255;
BA_ "Platform_VMCU1_Sig" SG_ 2348814337 TSC1RECUEMSdap_EnRTrqTrqLm 1;
BA_ "SPN" SG_ 2348814337 TSC1RECUEMSdap_EnRTrqTrqLm 518;
BA_ "GenSigSendType" SG_ 2348814336 TSC1RECUEMSccb_EnRSpdSpdLm 7;
BA_ "GenSigCycleTime" SG_ 2348814336 TSC1RECUEMSccb_EnRSpdSpdLm 100;
BA_ "GenSigCycleTimeActive" SG_ 2348814336 TSC1RECUEMSccb_EnRSpdSpdLm 100;
BA_ "GenSigStartValue" SG_ 2348814336 TSC1RECUEMSccb_EnRSpdSpdLm 65535;
BA_ "Platform_VMCU1_Sig" SG_ 2348814336 TSC1RECUEMSccb_EnRSpdSpdLm 1;
BA_ "SPN" SG_ 2348814336 TSC1RECUEMSccb_EnRSpdSpdLm 898;
BA_ "GenSigSendType" SG_ 2348814336 TSC1RECUEMSccb_EnRSpdCtrlC 7;
BA_ "GenSigCycleTime" SG_ 2348814336 TSC1RECUEMSccb_EnRSpdCtrlC 100;
BA_ "GenSigCycleTimeActive" SG_ 2348814336 TSC1RECUEMSccb_EnRSpdCtrlC 100;
BA_ "Platform_VMCU1_Sig" SG_ 2348814336 TSC1RECUEMSccb_EnRSpdCtrlC 1;
BA_ "SPN" SG_ 2348814336 TSC1RECUEMSccb_EnRSpdCtrlC 696;
BA_ "GenSigSendType" SG_ 2348814336 TSC1RECUEMSccb_EnOvrdCtrlM 6;
BA_ "Platform_VMCU1_Sig" SG_ 2348814336 TSC1RECUEMSccb_EnOvrdCtrlM 1;
BA_ "SPN" SG_ 2348814336 TSC1RECUEMSccb_EnOvrdCtrlM 695;
BA_ "GenSigSendType" SG_ 2348814336 TSC1RECUEMSccb_OvrdCtrlMPr 7;
BA_ "GenSigCycleTime" SG_ 2348814336 TSC1RECUEMSccb_OvrdCtrlMPr 100;
BA_ "GenSigCycleTimeActive" SG_ 2348814336 TSC1RECUEMSccb_OvrdCtrlMPr 100;
BA_ "GenSigStartValue" SG_ 2348814336 TSC1RECUEMSccb_OvrdCtrlMPr 3;
BA_ "Platform_VMCU1_Sig" SG_ 2348814336 TSC1RECUEMSccb_OvrdCtrlMPr 1;
BA_ "SPN" SG_ 2348814336 TSC1RECUEMSccb_OvrdCtrlMPr 897;
BA_ "GenSigSendType" SG_ 2348814336 TSC1RECUEMSccb_EnRTrqTrqLm 7;
BA_ "GenSigCycleTime" SG_ 2348814336 TSC1RECUEMSccb_EnRTrqTrqLm 100;
BA_ "GenSigCycleTimeActive" SG_ 2348814336 TSC1RECUEMSccb_EnRTrqTrqLm 100;
BA_ "GenSigStartValue" SG_ 2348814336 TSC1RECUEMSccb_EnRTrqTrqLm 255;
BA_ "Platform_VMCU1_Sig" SG_ 2348814336 TSC1RECUEMSccb_EnRTrqTrqLm 1;
BA_ "SPN" SG_ 2348814336 TSC1RECUEMSccb_EnRTrqTrqLm 518;
BA_ "GenSigSendType" SG_ 2348814347 TSC1RECUABS_EnOvrdCtrlM 6;
BA_ "Platform_VMCU1_Sig" SG_ 2348814347 TSC1RECUABS_EnOvrdCtrlM 1;
BA_ "SPN" SG_ 2348814347 TSC1RECUABS_EnOvrdCtrlM 695;
BA_ "GenSigSendType" SG_ 2348814347 TSC1RECUABS_EnRTrqTrqLm 7;
BA_ "GenSigCycleTime" SG_ 2348814347 TSC1RECUABS_EnRTrqTrqLm 100;
BA_ "GenSigCycleTimeActive" SG_ 2348814347 TSC1RECUABS_EnRTrqTrqLm 100;
BA_ "GenSigStartValue" SG_ 2348814347 TSC1RECUABS_EnRTrqTrqLm 255;
BA_ "Platform_VMCU1_Sig" SG_ 2348814347 TSC1RECUABS_EnRTrqTrqLm 1;
BA_ "SPN" SG_ 2348814347 TSC1RECUABS_EnRTrqTrqLm 518;
BA_ "GenSigSendType" SG_ 2348814347 TSC1RECUABS_EnRSpdSpdLm 7;
BA_ "GenSigCycleTime" SG_ 2348814347 TSC1RECUABS_EnRSpdSpdLm 100;
BA_ "GenSigCycleTimeActive" SG_ 2348814347 TSC1RECUABS_EnRSpdSpdLm 100;
BA_ "GenSigStartValue" SG_ 2348814347 TSC1RECUABS_EnRSpdSpdLm 65535;
BA_ "Platform_VMCU1_Sig" SG_ 2348814347 TSC1RECUABS_EnRSpdSpdLm 1;
BA_ "SPN" SG_ 2348814347 TSC1RECUABS_EnRSpdSpdLm 898;
BA_ "GenSigSendType" SG_ 2348814347 TSC1RECUABS_OvrdCtrlMPr 7;
BA_ "GenSigCycleTime" SG_ 2348814347 TSC1RECUABS_OvrdCtrlMPr 100;
BA_ "GenSigCycleTimeActive" SG_ 2348814347 TSC1RECUABS_OvrdCtrlMPr 100;
BA_ "GenSigStartValue" SG_ 2348814347 TSC1RECUABS_OvrdCtrlMPr 3;
BA_ "Platform_VMCU1_Sig" SG_ 2348814347 TSC1RECUABS_OvrdCtrlMPr 1;
BA_ "SPN" SG_ 2348814347 TSC1RECUABS_OvrdCtrlMPr 897;
BA_ "GenSigSendType" SG_ 2348814347 TSC1RECUABS_EnRSpdCtrlC 7;
BA_ "GenSigCycleTime" SG_ 2348814347 TSC1RECUABS_EnRSpdCtrlC 100;
BA_ "GenSigCycleTimeActive" SG_ 2348814347 TSC1RECUABS_EnRSpdCtrlC 100;
BA_ "Platform_VMCU1_Sig" SG_ 2348814347 TSC1RECUABS_EnRSpdCtrlC 1;
BA_ "SPN" SG_ 2348814347 TSC1RECUABS_EnRSpdCtrlC 696;
BA_ "GenSigSendType" SG_ 2348810257 TSC1EMSVMCUtr_EnOvrdCtrlM 6;
BA_ "Platform_VMCU1_Sig" SG_ 2348810257 TSC1EMSVMCUtr_EnOvrdCtrlM 1;
BA_ "SPN" SG_ 2348810257 TSC1EMSVMCUtr_EnOvrdCtrlM 695;
BA_ "SeToolAncestorID_SIGNAL" SG_ 2348810257 TSC1EMSVMCUtr_EnOvrdCtrlM "x0000001D042564C7";
BA_ "SeToolItemID_SIGNAL" SG_ 2348810257 TSC1EMSVMCUtr_EnOvrdCtrlM "x0000001D042564C7";
BA_ "SeToolName_SIGNAL" SG_ 2348810257 TSC1EMSVMCUtr_EnOvrdCtrlM "EnOvrdCtrlM";
BA_ "SeToolOwnerSigGroupID_SIGNAL" SG_ 2348810257 TSC1EMSVMCUtr_EnOvrdCtrlM "x0000001D043FB710";
BA_ "SeToolOwnerSigGroup_SIGNAL" SG_ 2348810257 TSC1EMSVMCUtr_EnOvrdCtrlM "TSC1EMSVMCUtr";
BA_ "SeToolVersion_SIGNAL" SG_ 2348810257 TSC1EMSVMCUtr_EnOvrdCtrlM "1";
BA_ "GenSigSendType" SG_ 2348810257 TSC1EMSVMCUtr_EnRSpdCtrlC 7;
BA_ "GenSigCycleTime" SG_ 2348810257 TSC1EMSVMCUtr_EnRSpdCtrlC 100;
BA_ "GenSigCycleTimeActive" SG_ 2348810257 TSC1EMSVMCUtr_EnRSpdCtrlC 100;
BA_ "Platform_VMCU1_Sig" SG_ 2348810257 TSC1EMSVMCUtr_EnRSpdCtrlC 1;
BA_ "SPN" SG_ 2348810257 TSC1EMSVMCUtr_EnRSpdCtrlC 696;
BA_ "SeToolAncestorID_SIGNAL" SG_ 2348810257 TSC1EMSVMCUtr_EnRSpdCtrlC "x0000001D042564C9";
BA_ "SeToolItemID_SIGNAL" SG_ 2348810257 TSC1EMSVMCUtr_EnRSpdCtrlC "x0000001D042564C9";
BA_ "SeToolName_SIGNAL" SG_ 2348810257 TSC1EMSVMCUtr_EnRSpdCtrlC "EnRSpdCtrlC";
BA_ "SeToolOwnerSigGroupID_SIGNAL" SG_ 2348810257 TSC1EMSVMCUtr_EnRSpdCtrlC "x0000001D043FB710";
BA_ "SeToolOwnerSigGroup_SIGNAL" SG_ 2348810257 TSC1EMSVMCUtr_EnRSpdCtrlC "TSC1EMSVMCUtr";
BA_ "SeToolVersion_SIGNAL" SG_ 2348810257 TSC1EMSVMCUtr_EnRSpdCtrlC "1";
BA_ "GenSigSendType" SG_ 2348810257 TSC1EMSVMCUtr_OvrdCtrlMPr 7;
BA_ "GenSigCycleTime" SG_ 2348810257 TSC1EMSVMCUtr_OvrdCtrlMPr 100;
BA_ "GenSigCycleTimeActive" SG_ 2348810257 TSC1EMSVMCUtr_OvrdCtrlMPr 100;
BA_ "GenSigStartValue" SG_ 2348810257 TSC1EMSVMCUtr_OvrdCtrlMPr 3;
BA_ "Platform_VMCU1_Sig" SG_ 2348810257 TSC1EMSVMCUtr_OvrdCtrlMPr 1;
BA_ "SPN" SG_ 2348810257 TSC1EMSVMCUtr_OvrdCtrlMPr 897;
BA_ "SeToolAncestorID_SIGNAL" SG_ 2348810257 TSC1EMSVMCUtr_OvrdCtrlMPr "x0000001D042564CE";
BA_ "SeToolItemID_SIGNAL" SG_ 2348810257 TSC1EMSVMCUtr_OvrdCtrlMPr "x0000001D042564CE";
BA_ "SeToolName_SIGNAL" SG_ 2348810257 TSC1EMSVMCUtr_OvrdCtrlMPr "OvrdCtrlMPr";
BA_ "SeToolOwnerSigGroupID_SIGNAL" SG_ 2348810257 TSC1EMSVMCUtr_OvrdCtrlMPr "x0000001D043FB710";
BA_ "SeToolOwnerSigGroup_SIGNAL" SG_ 2348810257 TSC1EMSVMCUtr_OvrdCtrlMPr "TSC1EMSVMCUtr";
BA_ "SeToolVersion_SIGNAL" SG_ 2348810257 TSC1EMSVMCUtr_OvrdCtrlMPr "1";
BA_ "GenSigSendType" SG_ 2348810257 TSC1EMSVMCUtr_EnRSpdSpdLm 7;
BA_ "GenSigCycleTime" SG_ 2348810257 TSC1EMSVMCUtr_EnRSpdSpdLm 100;
BA_ "GenSigCycleTimeActive" SG_ 2348810257 TSC1EMSVMCUtr_EnRSpdSpdLm 100;
BA_ "GenSigStartValue" SG_ 2348810257 TSC1EMSVMCUtr_EnRSpdSpdLm 65535;
BA_ "Platform_VMCU1_Sig" SG_ 2348810257 TSC1EMSVMCUtr_EnRSpdSpdLm 1;
BA_ "SPN" SG_ 2348810257 TSC1EMSVMCUtr_EnRSpdSpdLm 898;
BA_ "SeToolAncestorID_SIGNAL" SG_ 2348810257 TSC1EMSVMCUtr_EnRSpdSpdLm "x0000001D042564D1";
BA_ "SeToolItemID_SIGNAL" SG_ 2348810257 TSC1EMSVMCUtr_EnRSpdSpdLm "x0000001D042564D1";
BA_ "SeToolName_SIGNAL" SG_ 2348810257 TSC1EMSVMCUtr_EnRSpdSpdLm "EnRSpdSpdLm";
BA_ "SeToolOwnerSigGroupID_SIGNAL" SG_ 2348810257 TSC1EMSVMCUtr_EnRSpdSpdLm "x0000001D043FB710";
BA_ "SeToolOwnerSigGroup_SIGNAL" SG_ 2348810257 TSC1EMSVMCUtr_EnRSpdSpdLm "TSC1EMSVMCUtr";
BA_ "SeToolVersion_SIGNAL" SG_ 2348810257 TSC1EMSVMCUtr_EnRSpdSpdLm "1";
BA_ "GenSigSendType" SG_ 2348810257 TSC1EMSVMCUtr_EnRTrqTrqLm 7;
BA_ "GenSigCycleTime" SG_ 2348810257 TSC1EMSVMCUtr_EnRTrqTrqLm 100;
BA_ "GenSigCycleTimeActive" SG_ 2348810257 TSC1EMSVMCUtr_EnRTrqTrqLm 100;
BA_ "GenSigStartValue" SG_ 2348810257 TSC1EMSVMCUtr_EnRTrqTrqLm 255;
BA_ "Platform_VMCU1_Sig" SG_ 2348810257 TSC1EMSVMCUtr_EnRTrqTrqLm 1;
BA_ "SPN" SG_ 2348810257 TSC1EMSVMCUtr_EnRTrqTrqLm 518;
BA_ "SeToolAncestorID_SIGNAL" SG_ 2348810257 TSC1EMSVMCUtr_EnRTrqTrqLm "x0000001D042564D4";
BA_ "SeToolItemID_SIGNAL" SG_ 2348810257 TSC1EMSVMCUtr_EnRTrqTrqLm "x0000001D042564D4";
BA_ "SeToolName_SIGNAL" SG_ 2348810257 TSC1EMSVMCUtr_EnRTrqTrqLm "EnRTrqTrqLm";
BA_ "SeToolOwnerSigGroupID_SIGNAL" SG_ 2348810257 TSC1EMSVMCUtr_EnRTrqTrqLm "x0000001D043FB710";
BA_ "SeToolOwnerSigGroup_SIGNAL" SG_ 2348810257 TSC1EMSVMCUtr_EnRTrqTrqLm "TSC1EMSVMCUtr";
BA_ "SeToolVersion_SIGNAL" SG_ 2348810257 TSC1EMSVMCUtr_EnRTrqTrqLm "1";
BA_ "GenSigSendType" SG_ 2348810288 TSC1EMSVMCUes_OvrdCtrlMPr 7;
BA_ "GenSigCycleTime" SG_ 2348810288 TSC1EMSVMCUes_OvrdCtrlMPr 100;
BA_ "GenSigCycleTimeActive" SG_ 2348810288 TSC1EMSVMCUes_OvrdCtrlMPr 100;
BA_ "GenSigStartValue" SG_ 2348810288 TSC1EMSVMCUes_OvrdCtrlMPr 3;
BA_ "Platform_VMCU1_Sig" SG_ 2348810288 TSC1EMSVMCUes_OvrdCtrlMPr 1;
BA_ "SPN" SG_ 2348810288 TSC1EMSVMCUes_OvrdCtrlMPr 897;
BA_ "SeToolAncestorID_SIGNAL" SG_ 2348810288 TSC1EMSVMCUes_OvrdCtrlMPr "x0000001D042564CE";
BA_ "SeToolItemID_SIGNAL" SG_ 2348810288 TSC1EMSVMCUes_OvrdCtrlMPr "x0000001D042564CE";
BA_ "SeToolName_SIGNAL" SG_ 2348810288 TSC1EMSVMCUes_OvrdCtrlMPr "OvrdCtrlMPr";
BA_ "SeToolOwnerSigGroupID_SIGNAL" SG_ 2348810288 TSC1EMSVMCUes_OvrdCtrlMPr "x0000001D0436B0FF";
BA_ "SeToolOwnerSigGroup_SIGNAL" SG_ 2348810288 TSC1EMSVMCUes_OvrdCtrlMPr "TSC1EMSVMCUes";
BA_ "SeToolVersion_SIGNAL" SG_ 2348810288 TSC1EMSVMCUes_OvrdCtrlMPr "1";
BA_ "GenSigSendType" SG_ 2348810288 TSC1EMSVMCUes_EnRTrqTrqLm 7;
BA_ "GenSigCycleTime" SG_ 2348810288 TSC1EMSVMCUes_EnRTrqTrqLm 100;
BA_ "GenSigCycleTimeActive" SG_ 2348810288 TSC1EMSVMCUes_EnRTrqTrqLm 100;
BA_ "GenSigStartValue" SG_ 2348810288 TSC1EMSVMCUes_EnRTrqTrqLm 255;
BA_ "Platform_VMCU1_Sig" SG_ 2348810288 TSC1EMSVMCUes_EnRTrqTrqLm 1;
BA_ "SPN" SG_ 2348810288 TSC1EMSVMCUes_EnRTrqTrqLm 518;
BA_ "SeToolAncestorID_SIGNAL" SG_ 2348810288 TSC1EMSVMCUes_EnRTrqTrqLm "x0000001D042564D4";
BA_ "SeToolItemID_SIGNAL" SG_ 2348810288 TSC1EMSVMCUes_EnRTrqTrqLm "x0000001D042564D4";
BA_ "SeToolName_SIGNAL" SG_ 2348810288 TSC1EMSVMCUes_EnRTrqTrqLm "EnRTrqTrqLm";
BA_ "SeToolOwnerSigGroupID_SIGNAL" SG_ 2348810288 TSC1EMSVMCUes_EnRTrqTrqLm "x0000001D0436B0FF";
BA_ "SeToolOwnerSigGroup_SIGNAL" SG_ 2348810288 TSC1EMSVMCUes_EnRTrqTrqLm "TSC1EMSVMCUes";
BA_ "SeToolVersion_SIGNAL" SG_ 2348810288 TSC1EMSVMCUes_EnRTrqTrqLm "1";
BA_ "GenSigSendType" SG_ 2348810288 TSC1EMSVMCUes_EnOvrdCtrlM 6;
BA_ "Platform_VMCU1_Sig" SG_ 2348810288 TSC1EMSVMCUes_EnOvrdCtrlM 1;
BA_ "SPN" SG_ 2348810288 TSC1EMSVMCUes_EnOvrdCtrlM 695;
BA_ "SeToolAncestorID_SIGNAL" SG_ 2348810288 TSC1EMSVMCUes_EnOvrdCtrlM "x0000001D042564C7";
BA_ "SeToolItemID_SIGNAL" SG_ 2348810288 TSC1EMSVMCUes_EnOvrdCtrlM "x0000001D042564C7";
BA_ "SeToolName_SIGNAL" SG_ 2348810288 TSC1EMSVMCUes_EnOvrdCtrlM "EnOvrdCtrlM";
BA_ "SeToolOwnerSigGroupID_SIGNAL" SG_ 2348810288 TSC1EMSVMCUes_EnOvrdCtrlM "x0000001D0436B0FF";
BA_ "SeToolOwnerSigGroup_SIGNAL" SG_ 2348810288 TSC1EMSVMCUes_EnOvrdCtrlM "TSC1EMSVMCUes";
BA_ "SeToolVersion_SIGNAL" SG_ 2348810288 TSC1EMSVMCUes_EnOvrdCtrlM "1";
BA_ "GenSigSendType" SG_ 2348810288 TSC1EMSVMCUes_EnRSpdSpdLm 7;
BA_ "GenSigCycleTime" SG_ 2348810288 TSC1EMSVMCUes_EnRSpdSpdLm 100;
BA_ "GenSigCycleTimeActive" SG_ 2348810288 TSC1EMSVMCUes_EnRSpdSpdLm 100;
BA_ "GenSigStartValue" SG_ 2348810288 TSC1EMSVMCUes_EnRSpdSpdLm 65535;
BA_ "Platform_VMCU1_Sig" SG_ 2348810288 TSC1EMSVMCUes_EnRSpdSpdLm 1;
BA_ "SPN" SG_ 2348810288 TSC1EMSVMCUes_EnRSpdSpdLm 898;
BA_ "SeToolAncestorID_SIGNAL" SG_ 2348810288 TSC1EMSVMCUes_EnRSpdSpdLm "x0000001D042564D1";
BA_ "SeToolItemID_SIGNAL" SG_ 2348810288 TSC1EMSVMCUes_EnRSpdSpdLm "x0000001D042564D1";
BA_ "SeToolName_SIGNAL" SG_ 2348810288 TSC1EMSVMCUes_EnRSpdSpdLm "EnRSpdSpdLm";
BA_ "SeToolOwnerSigGroupID_SIGNAL" SG_ 2348810288 TSC1EMSVMCUes_EnRSpdSpdLm "x0000001D0436B0FF";
BA_ "SeToolOwnerSigGroup_SIGNAL" SG_ 2348810288 TSC1EMSVMCUes_EnRSpdSpdLm "TSC1EMSVMCUes";
BA_ "SeToolVersion_SIGNAL" SG_ 2348810288 TSC1EMSVMCUes_EnRSpdSpdLm "1";
BA_ "GenSigSendType" SG_ 2348810288 TSC1EMSVMCUes_EnRSpdCtrlC 7;
BA_ "GenSigCycleTime" SG_ 2348810288 TSC1EMSVMCUes_EnRSpdCtrlC 100;
BA_ "GenSigCycleTimeActive" SG_ 2348810288 TSC1EMSVMCUes_EnRSpdCtrlC 100;
BA_ "Platform_VMCU1_Sig" SG_ 2348810288 TSC1EMSVMCUes_EnRSpdCtrlC 1;
BA_ "SPN" SG_ 2348810288 TSC1EMSVMCUes_EnRSpdCtrlC 696;
BA_ "SeToolAncestorID_SIGNAL" SG_ 2348810288 TSC1EMSVMCUes_EnRSpdCtrlC "x0000001D042564C9";
BA_ "SeToolItemID_SIGNAL" SG_ 2348810288 TSC1EMSVMCUes_EnRSpdCtrlC "x0000001D042564C9";
BA_ "SeToolName_SIGNAL" SG_ 2348810288 TSC1EMSVMCUes_EnRSpdCtrlC "EnRSpdCtrlC";
BA_ "SeToolOwnerSigGroupID_SIGNAL" SG_ 2348810288 TSC1EMSVMCUes_EnRSpdCtrlC "x0000001D0436B0FF";
BA_ "SeToolOwnerSigGroup_SIGNAL" SG_ 2348810288 TSC1EMSVMCUes_EnRSpdCtrlC "TSC1EMSVMCUes";
BA_ "SeToolVersion_SIGNAL" SG_ 2348810288 TSC1EMSVMCUes_EnRSpdCtrlC "1";
BA_ "GenSigSendType" SG_ 2348810243 TSC1EMSTECU_EnRSpdSpdLm 7;
BA_ "GenSigCycleTime" SG_ 2348810243 TSC1EMSTECU_EnRSpdSpdLm 100;
BA_ "GenSigCycleTimeActive" SG_ 2348810243 TSC1EMSTECU_EnRSpdSpdLm 100;
BA_ "GenSigStartValue" SG_ 2348810243 TSC1EMSTECU_EnRSpdSpdLm 65535;
BA_ "Platform_VMCU1_Sig" SG_ 2348810243 TSC1EMSTECU_EnRSpdSpdLm 1;
BA_ "SPN" SG_ 2348810243 TSC1EMSTECU_EnRSpdSpdLm 898;
BA_ "SeToolAncestorID_SIGNAL" SG_ 2348810243 TSC1EMSTECU_EnRSpdSpdLm "x0000001D042564D1";
BA_ "SeToolItemID_SIGNAL" SG_ 2348810243 TSC1EMSTECU_EnRSpdSpdLm "x0000001D042564D1";
BA_ "SeToolName_SIGNAL" SG_ 2348810243 TSC1EMSTECU_EnRSpdSpdLm "EnRSpdSpdLm";
BA_ "SeToolOwnerSigGroupID_SIGNAL" SG_ 2348810243 TSC1EMSTECU_EnRSpdSpdLm "x0000001D043D7655";
BA_ "SeToolOwnerSigGroup_SIGNAL" SG_ 2348810243 TSC1EMSTECU_EnRSpdSpdLm "TSC1_TECU_EMS";
BA_ "SeToolVersion_SIGNAL" SG_ 2348810243 TSC1EMSTECU_EnRSpdSpdLm "1";
BA_ "GenSigSendType" SG_ 2348810243 TSC1EMSTECU_EnOvrdCtrlM 6;
BA_ "Platform_VMCU1_Sig" SG_ 2348810243 TSC1EMSTECU_EnOvrdCtrlM 1;
BA_ "SPN" SG_ 2348810243 TSC1EMSTECU_EnOvrdCtrlM 695;
BA_ "SeToolAncestorID_SIGNAL" SG_ 2348810243 TSC1EMSTECU_EnOvrdCtrlM "x0000001D042564C7";
BA_ "SeToolItemID_SIGNAL" SG_ 2348810243 TSC1EMSTECU_EnOvrdCtrlM "x0000001D042564C7";
BA_ "SeToolName_SIGNAL" SG_ 2348810243 TSC1EMSTECU_EnOvrdCtrlM "EnOvrdCtrlM";
BA_ "SeToolOwnerSigGroupID_SIGNAL" SG_ 2348810243 TSC1EMSTECU_EnOvrdCtrlM "x0000001D043D7655";
BA_ "SeToolOwnerSigGroup_SIGNAL" SG_ 2348810243 TSC1EMSTECU_EnOvrdCtrlM "TSC1_TECU_EMS";
BA_ "SeToolVersion_SIGNAL" SG_ 2348810243 TSC1EMSTECU_EnOvrdCtrlM "1";
BA_ "GenSigSendType" SG_ 2348810243 TSC1EMSTECU_OvrdCtrlMPr 7;
BA_ "GenSigCycleTime" SG_ 2348810243 TSC1EMSTECU_OvrdCtrlMPr 100;
BA_ "GenSigCycleTimeActive" SG_ 2348810243 TSC1EMSTECU_OvrdCtrlMPr 100;
BA_ "GenSigStartValue" SG_ 2348810243 TSC1EMSTECU_OvrdCtrlMPr 3;
BA_ "Platform_VMCU1_Sig" SG_ 2348810243 TSC1EMSTECU_OvrdCtrlMPr 1;
BA_ "SPN" SG_ 2348810243 TSC1EMSTECU_OvrdCtrlMPr 897;
BA_ "SeToolAncestorID_SIGNAL" SG_ 2348810243 TSC1EMSTECU_OvrdCtrlMPr "x0000001D042564CE";
BA_ "SeToolItemID_SIGNAL" SG_ 2348810243 TSC1EMSTECU_OvrdCtrlMPr "x0000001D042564CE";
BA_ "SeToolName_SIGNAL" SG_ 2348810243 TSC1EMSTECU_OvrdCtrlMPr "OvrdCtrlMPr";
BA_ "SeToolOwnerSigGroupID_SIGNAL" SG_ 2348810243 TSC1EMSTECU_OvrdCtrlMPr "x0000001D043D7655";
BA_ "SeToolOwnerSigGroup_SIGNAL" SG_ 2348810243 TSC1EMSTECU_OvrdCtrlMPr "TSC1_TECU_EMS";
BA_ "SeToolVersion_SIGNAL" SG_ 2348810243 TSC1EMSTECU_OvrdCtrlMPr "1";
BA_ "GenSigSendType" SG_ 2348810243 TSC1EMSTECU_EnRSpdCtrlC 7;
BA_ "GenSigCycleTime" SG_ 2348810243 TSC1EMSTECU_EnRSpdCtrlC 100;
BA_ "GenSigCycleTimeActive" SG_ 2348810243 TSC1EMSTECU_EnRSpdCtrlC 100;
BA_ "Platform_VMCU1_Sig" SG_ 2348810243 TSC1EMSTECU_EnRSpdCtrlC 1;
BA_ "SPN" SG_ 2348810243 TSC1EMSTECU_EnRSpdCtrlC 696;
BA_ "SeToolAncestorID_SIGNAL" SG_ 2348810243 TSC1EMSTECU_EnRSpdCtrlC "x0000001D042564C9";
BA_ "SeToolItemID_SIGNAL" SG_ 2348810243 TSC1EMSTECU_EnRSpdCtrlC "x0000001D042564C9";
BA_ "SeToolName_SIGNAL" SG_ 2348810243 TSC1EMSTECU_EnRSpdCtrlC "EnRSpdCtrlC";
BA_ "SeToolOwnerSigGroupID_SIGNAL" SG_ 2348810243 TSC1EMSTECU_EnRSpdCtrlC "x0000001D043D7655";
BA_ "SeToolOwnerSigGroup_SIGNAL" SG_ 2348810243 TSC1EMSTECU_EnRSpdCtrlC "TSC1_TECU_EMS";
BA_ "SeToolVersion_SIGNAL" SG_ 2348810243 TSC1EMSTECU_EnRSpdCtrlC "1";
BA_ "GenSigSendType" SG_ 2348810243 TSC1EMSTECU_EnRTrqTrqLm 7;
BA_ "GenSigCycleTime" SG_ 2348810243 TSC1EMSTECU_EnRTrqTrqLm 100;
BA_ "GenSigCycleTimeActive" SG_ 2348810243 TSC1EMSTECU_EnRTrqTrqLm 100;
BA_ "GenSigStartValue" SG_ 2348810243 TSC1EMSTECU_EnRTrqTrqLm 255;
BA_ "Platform_VMCU1_Sig" SG_ 2348810243 TSC1EMSTECU_EnRTrqTrqLm 1;
BA_ "SPN" SG_ 2348810243 TSC1EMSTECU_EnRTrqTrqLm 518;
BA_ "SeToolAncestorID_SIGNAL" SG_ 2348810243 TSC1EMSTECU_EnRTrqTrqLm "x0000001D042564D4";
BA_ "SeToolItemID_SIGNAL" SG_ 2348810243 TSC1EMSTECU_EnRTrqTrqLm "x0000001D042564D4";
BA_ "SeToolName_SIGNAL" SG_ 2348810243 TSC1EMSTECU_EnRTrqTrqLm "EnRTrqTrqLm";
BA_ "SeToolOwnerSigGroupID_SIGNAL" SG_ 2348810243 TSC1EMSTECU_EnRTrqTrqLm "x0000001D043D7655";
BA_ "SeToolOwnerSigGroup_SIGNAL" SG_ 2348810243 TSC1EMSTECU_EnRTrqTrqLm "TSC1_TECU_EMS";
BA_ "SeToolVersion_SIGNAL" SG_ 2348810243 TSC1EMSTECU_EnRTrqTrqLm "1";
BA_ "GenSigSendType" SG_ 2348810251 TSC1EMSABS_EnRTrqTrqLm 7;
BA_ "GenSigCycleTime" SG_ 2348810251 TSC1EMSABS_EnRTrqTrqLm 100;
BA_ "GenSigCycleTimeActive" SG_ 2348810251 TSC1EMSABS_EnRTrqTrqLm 100;
BA_ "GenSigStartValue" SG_ 2348810251 TSC1EMSABS_EnRTrqTrqLm 255;
BA_ "Platform_VMCU1_Sig" SG_ 2348810251 TSC1EMSABS_EnRTrqTrqLm 1;
BA_ "SPN" SG_ 2348810251 TSC1EMSABS_EnRTrqTrqLm 518;
BA_ "SeToolAncestorID_SIGNAL" SG_ 2348810251 TSC1EMSABS_EnRTrqTrqLm "x0000001D042564D4";
BA_ "SeToolItemID_SIGNAL" SG_ 2348810251 TSC1EMSABS_EnRTrqTrqLm "x0000001D042564D4";
BA_ "SeToolName_SIGNAL" SG_ 2348810251 TSC1EMSABS_EnRTrqTrqLm "EnRTrqTrqLm";
BA_ "SeToolOwnerSigGroupID_SIGNAL" SG_ 2348810251 TSC1EMSABS_EnRTrqTrqLm "x0000001D043D6E46";
BA_ "SeToolOwnerSigGroup_SIGNAL" SG_ 2348810251 TSC1EMSABS_EnRTrqTrqLm "TSC1EMSABS";
BA_ "SeToolVersion_SIGNAL" SG_ 2348810251 TSC1EMSABS_EnRTrqTrqLm "1";
BA_ "GenSigSendType" SG_ 2348810251 TSC1EMSABS_EnRSpdCtrlC 7;
BA_ "GenSigCycleTime" SG_ 2348810251 TSC1EMSABS_EnRSpdCtrlC 100;
BA_ "GenSigCycleTimeActive" SG_ 2348810251 TSC1EMSABS_EnRSpdCtrlC 100;
BA_ "Platform_VMCU1_Sig" SG_ 2348810251 TSC1EMSABS_EnRSpdCtrlC 1;
BA_ "SPN" SG_ 2348810251 TSC1EMSABS_EnRSpdCtrlC 696;
BA_ "SeToolAncestorID_SIGNAL" SG_ 2348810251 TSC1EMSABS_EnRSpdCtrlC "x0000001D042564C9";
BA_ "SeToolItemID_SIGNAL" SG_ 2348810251 TSC1EMSABS_EnRSpdCtrlC "x0000001D042564C9";
BA_ "SeToolName_SIGNAL" SG_ 2348810251 TSC1EMSABS_EnRSpdCtrlC "EnRSpdCtrlC";
BA_ "SeToolOwnerSigGroupID_SIGNAL" SG_ 2348810251 TSC1EMSABS_EnRSpdCtrlC "x0000001D043D6E46";
BA_ "SeToolOwnerSigGroup_SIGNAL" SG_ 2348810251 TSC1EMSABS_EnRSpdCtrlC "TSC1EMSABS";
BA_ "SeToolVersion_SIGNAL" SG_ 2348810251 TSC1EMSABS_EnRSpdCtrlC "1";
BA_ "GenSigSendType" SG_ 2348810251 TSC1EMSABS_OvrdCtrlMPr 7;
BA_ "GenSigCycleTime" SG_ 2348810251 TSC1EMSABS_OvrdCtrlMPr 100;
BA_ "GenSigCycleTimeActive" SG_ 2348810251 TSC1EMSABS_OvrdCtrlMPr 100;
BA_ "GenSigStartValue" SG_ 2348810251 TSC1EMSABS_OvrdCtrlMPr 3;
BA_ "Platform_VMCU1_Sig" SG_ 2348810251 TSC1EMSABS_OvrdCtrlMPr 1;
BA_ "SPN" SG_ 2348810251 TSC1EMSABS_OvrdCtrlMPr 897;
BA_ "SeToolAncestorID_SIGNAL" SG_ 2348810251 TSC1EMSABS_OvrdCtrlMPr "x0000001D042564CE";
BA_ "SeToolItemID_SIGNAL" SG_ 2348810251 TSC1EMSABS_OvrdCtrlMPr "x0000001D042564CE";
BA_ "SeToolName_SIGNAL" SG_ 2348810251 TSC1EMSABS_OvrdCtrlMPr "OvrdCtrlMPr";
BA_ "SeToolOwnerSigGroupID_SIGNAL" SG_ 2348810251 TSC1EMSABS_OvrdCtrlMPr "x0000001D043D6E46";
BA_ "SeToolOwnerSigGroup_SIGNAL" SG_ 2348810251 TSC1EMSABS_OvrdCtrlMPr "TSC1EMSABS";
BA_ "SeToolVersion_SIGNAL" SG_ 2348810251 TSC1EMSABS_OvrdCtrlMPr "1";
BA_ "GenSigSendType" SG_ 2348810251 TSC1EMSABS_EnOvrdCtrlM 6;
BA_ "Platform_VMCU1_Sig" SG_ 2348810251 TSC1EMSABS_EnOvrdCtrlM 1;
BA_ "SPN" SG_ 2348810251 TSC1EMSABS_EnOvrdCtrlM 695;
BA_ "SeToolAncestorID_SIGNAL" SG_ 2348810251 TSC1EMSABS_EnOvrdCtrlM "x0000001D042564C7";
BA_ "SeToolItemID_SIGNAL" SG_ 2348810251 TSC1EMSABS_EnOvrdCtrlM "x0000001D042564C7";
BA_ "SeToolName_SIGNAL" SG_ 2348810251 TSC1EMSABS_EnOvrdCtrlM "EnOvrdCtrlM";
BA_ "SeToolOwnerSigGroupID_SIGNAL" SG_ 2348810251 TSC1EMSABS_EnOvrdCtrlM "x0000001D043D6E46";
BA_ "SeToolOwnerSigGroup_SIGNAL" SG_ 2348810251 TSC1EMSABS_EnOvrdCtrlM "TSC1EMSABS";
BA_ "SeToolVersion_SIGNAL" SG_ 2348810251 TSC1EMSABS_EnOvrdCtrlM "1";
BA_ "GenSigSendType" SG_ 2348810251 TSC1EMSABS_EnRSpdSpdLm 7;
BA_ "GenSigCycleTime" SG_ 2348810251 TSC1EMSABS_EnRSpdSpdLm 100;
BA_ "GenSigCycleTimeActive" SG_ 2348810251 TSC1EMSABS_EnRSpdSpdLm 100;
BA_ "GenSigStartValue" SG_ 2348810251 TSC1EMSABS_EnRSpdSpdLm 65535;
BA_ "Platform_VMCU1_Sig" SG_ 2348810251 TSC1EMSABS_EnRSpdSpdLm 1;
BA_ "SPN" SG_ 2348810251 TSC1EMSABS_EnRSpdSpdLm 898;
BA_ "SeToolAncestorID_SIGNAL" SG_ 2348810251 TSC1EMSABS_EnRSpdSpdLm "x0000001D042564D1";
BA_ "SeToolItemID_SIGNAL" SG_ 2348810251 TSC1EMSABS_EnRSpdSpdLm "x0000001D042564D1";
BA_ "SeToolName_SIGNAL" SG_ 2348810251 TSC1EMSABS_EnRSpdSpdLm "EnRSpdSpdLm";
BA_ "SeToolOwnerSigGroupID_SIGNAL" SG_ 2348810251 TSC1EMSABS_EnRSpdSpdLm "x0000001D043D6E46";
BA_ "SeToolOwnerSigGroup_SIGNAL" SG_ 2348810251 TSC1EMSABS_EnRSpdSpdLm "TSC1EMSABS";
BA_ "SeToolVersion_SIGNAL" SG_ 2348810251 TSC1EMSABS_EnRSpdSpdLm "1";
BA_ "GenSigSendType" SG_ 2348810413 TSC1EMSDACU_OvrdCtrlMPr 7;
BA_ "GenSigCycleTime" SG_ 2348810413 TSC1EMSDACU_OvrdCtrlMPr 100;
BA_ "GenSigCycleTimeActive" SG_ 2348810413 TSC1EMSDACU_OvrdCtrlMPr 100;
BA_ "GenSigStartValue" SG_ 2348810413 TSC1EMSDACU_OvrdCtrlMPr 3;
BA_ "Platform_VMCU1_Sig" SG_ 2348810413 TSC1EMSDACU_OvrdCtrlMPr 1;
BA_ "SPN" SG_ 2348810413 TSC1EMSDACU_OvrdCtrlMPr 897;
BA_ "SeToolAncestorID_SIGNAL" SG_ 2348810413 TSC1EMSDACU_OvrdCtrlMPr "x0000001D042564CE";
BA_ "SeToolItemID_SIGNAL" SG_ 2348810413 TSC1EMSDACU_OvrdCtrlMPr "x0000001D042564CE";
BA_ "SeToolName_SIGNAL" SG_ 2348810413 TSC1EMSDACU_OvrdCtrlMPr "OvrdCtrlMPr";
BA_ "SeToolOwnerSigGroupID_SIGNAL" SG_ 2348810413 TSC1EMSDACU_OvrdCtrlMPr "x0000001D0440D562";
BA_ "SeToolOwnerSigGroup_SIGNAL" SG_ 2348810413 TSC1EMSDACU_OvrdCtrlMPr "TSC1EMSDACU";
BA_ "SeToolVersion_SIGNAL" SG_ 2348810413 TSC1EMSDACU_OvrdCtrlMPr "1";
BA_ "GenSigSendType" SG_ 2348810413 TSC1EMSDACU_EnRSpdSpdLm 7;
BA_ "GenSigCycleTime" SG_ 2348810413 TSC1EMSDACU_EnRSpdSpdLm 100;
BA_ "GenSigCycleTimeActive" SG_ 2348810413 TSC1EMSDACU_EnRSpdSpdLm 100;
BA_ "GenSigStartValue" SG_ 2348810413 TSC1EMSDACU_EnRSpdSpdLm 65535;
BA_ "Platform_VMCU1_Sig" SG_ 2348810413 TSC1EMSDACU_EnRSpdSpdLm 1;
BA_ "SPN" SG_ 2348810413 TSC1EMSDACU_EnRSpdSpdLm 898;
BA_ "SeToolAncestorID_SIGNAL" SG_ 2348810413 TSC1EMSDACU_EnRSpdSpdLm "x0000001D042564D1";
BA_ "SeToolItemID_SIGNAL" SG_ 2348810413 TSC1EMSDACU_EnRSpdSpdLm "x0000001D042564D1";
BA_ "SeToolName_SIGNAL" SG_ 2348810413 TSC1EMSDACU_EnRSpdSpdLm "EnRSpdSpdLm";
BA_ "SeToolOwnerSigGroupID_SIGNAL" SG_ 2348810413 TSC1EMSDACU_EnRSpdSpdLm "x0000001D0440D562";
BA_ "SeToolOwnerSigGroup_SIGNAL" SG_ 2348810413 TSC1EMSDACU_EnRSpdSpdLm "TSC1EMSDACU";
BA_ "SeToolVersion_SIGNAL" SG_ 2348810413 TSC1EMSDACU_EnRSpdSpdLm "1";
BA_ "GenSigSendType" SG_ 2348810413 TSC1EMSDACU_EnRSpdCtrlC 7;
BA_ "GenSigCycleTime" SG_ 2348810413 TSC1EMSDACU_EnRSpdCtrlC 100;
BA_ "GenSigCycleTimeActive" SG_ 2348810413 TSC1EMSDACU_EnRSpdCtrlC 100;
BA_ "Platform_VMCU1_Sig" SG_ 2348810413 TSC1EMSDACU_EnRSpdCtrlC 1;
BA_ "SPN" SG_ 2348810413 TSC1EMSDACU_EnRSpdCtrlC 696;
BA_ "SeToolAncestorID_SIGNAL" SG_ 2348810413 TSC1EMSDACU_EnRSpdCtrlC "x0000001D042564C9";
BA_ "SeToolItemID_SIGNAL" SG_ 2348810413 TSC1EMSDACU_EnRSpdCtrlC "x0000001D042564C9";
BA_ "SeToolName_SIGNAL" SG_ 2348810413 TSC1EMSDACU_EnRSpdCtrlC "EnRSpdCtrlC";
BA_ "SeToolOwnerSigGroupID_SIGNAL" SG_ 2348810413 TSC1EMSDACU_EnRSpdCtrlC "x0000001D0440D562";
BA_ "SeToolOwnerSigGroup_SIGNAL" SG_ 2348810413 TSC1EMSDACU_EnRSpdCtrlC "TSC1EMSDACU";
BA_ "SeToolVersion_SIGNAL" SG_ 2348810413 TSC1EMSDACU_EnRSpdCtrlC "1";
BA_ "GenSigSendType" SG_ 2348810413 TSC1EMSDACU_EnRTrqTrqLm 7;
BA_ "GenSigCycleTime" SG_ 2348810413 TSC1EMSDACU_EnRTrqTrqLm 100;
BA_ "GenSigCycleTimeActive" SG_ 2348810413 TSC1EMSDACU_EnRTrqTrqLm 100;
BA_ "GenSigStartValue" SG_ 2348810413 TSC1EMSDACU_EnRTrqTrqLm 255;
BA_ "Platform_VMCU1_Sig" SG_ 2348810413 TSC1EMSDACU_EnRTrqTrqLm 1;
BA_ "SPN" SG_ 2348810413 TSC1EMSDACU_EnRTrqTrqLm 518;
BA_ "SeToolAncestorID_SIGNAL" SG_ 2348810413 TSC1EMSDACU_EnRTrqTrqLm "x0000001D042564D4";
BA_ "SeToolItemID_SIGNAL" SG_ 2348810413 TSC1EMSDACU_EnRTrqTrqLm "x0000001D042564D4";
BA_ "SeToolName_SIGNAL" SG_ 2348810413 TSC1EMSDACU_EnRTrqTrqLm "EnRTrqTrqLm";
BA_ "SeToolOwnerSigGroupID_SIGNAL" SG_ 2348810413 TSC1EMSDACU_EnRTrqTrqLm "x0000001D0440D562";
BA_ "SeToolOwnerSigGroup_SIGNAL" SG_ 2348810413 TSC1EMSDACU_EnRTrqTrqLm "TSC1EMSDACU";
BA_ "SeToolVersion_SIGNAL" SG_ 2348810413 TSC1EMSDACU_EnRTrqTrqLm "1";
BA_ "GenSigSendType" SG_ 2348810413 TSC1EMSDACU_EnOvrdCtrlM 6;
BA_ "Platform_VMCU1_Sig" SG_ 2348810413 TSC1EMSDACU_EnOvrdCtrlM 1;
BA_ "SPN" SG_ 2348810413 TSC1EMSDACU_EnOvrdCtrlM 695;
BA_ "SeToolAncestorID_SIGNAL" SG_ 2348810413 TSC1EMSDACU_EnOvrdCtrlM "x0000001D042564C7";
BA_ "SeToolItemID_SIGNAL" SG_ 2348810413 TSC1EMSDACU_EnOvrdCtrlM "x0000001D042564C7";
BA_ "SeToolName_SIGNAL" SG_ 2348810413 TSC1EMSDACU_EnOvrdCtrlM "EnOvrdCtrlM";
BA_ "SeToolOwnerSigGroupID_SIGNAL" SG_ 2348810413 TSC1EMSDACU_EnOvrdCtrlM "x0000001D0440D562";
BA_ "SeToolOwnerSigGroup_SIGNAL" SG_ 2348810413 TSC1EMSDACU_EnOvrdCtrlM "TSC1EMSDACU";
BA_ "SeToolVersion_SIGNAL" SG_ 2348810413 TSC1EMSDACU_EnOvrdCtrlM "1";
BA_REL_ "GenSigFirstTimeoutTime" BU_SG_REL_ TECU SG_ 2349075373 XBRDACU_Urgency 3000;
BA_REL_ "GenSigTimeoutTime" BU_SG_REL_ TECU SG_ 2349075373 XBRDACU_Urgency 1200;
BA_REL_ "GenSigFirstTimeoutTime" BU_SG_REL_ TECU SG_ 2349075373 XBRDACU_EBIMode 3000;
BA_REL_ "GenSigTimeoutTime" BU_SG_REL_ TECU SG_ 2349075373 XBRDACU_EBIMode 1200;
BA_REL_ "GenSigFirstTimeoutTime" BU_SG_REL_ TECU SG_ 2349075373 XBRDACU_ExtAccelDemand 3000;
BA_REL_ "GenSigTimeoutTime" BU_SG_REL_ TECU SG_ 2349075373 XBRDACU_ExtAccelDemand 1200;
BA_REL_ "GenSigFirstTimeoutTime" BU_SG_REL_ TECU SG_ 2349075373 XBRDACU_MsgCounter 3000;
BA_REL_ "GenSigTimeoutTime" BU_SG_REL_ TECU SG_ 2349075373 XBRDACU_MsgCounter 1200;
BA_REL_ "GenSigFirstTimeoutTime" BU_SG_REL_ TECU SG_ 2349075373 XBRDACU_MsgChecksum 3000;
BA_REL_ "GenSigTimeoutTime" BU_SG_REL_ TECU SG_ 2349075373 XBRDACU_MsgChecksum 1200;
BA_REL_ "GenSigFirstTimeoutTime" BU_SG_REL_ TECU SG_ 2349075373 XBRDACU_ControlMode 3000;
BA_REL_ "GenSigTimeoutTime" BU_SG_REL_ TECU SG_ 2349075373 XBRDACU_ControlMode 1200;
BA_REL_ "GenSigFirstTimeoutTime" BU_SG_REL_ TECU SG_ 2349075373 XBRDACU_Priority 3000;
BA_REL_ "GenSigTimeoutTime" BU_SG_REL_ TECU SG_ 2349075373 XBRDACU_Priority 1200;
BA_REL_ "GenSigFirstTimeoutTime" BU_SG_REL_ BBM SG_ 2566848256 WaterInFuelAlarm_ISig_3 65000;
BA_REL_ "GenSigTimeoutTime" BU_SG_REL_ BBM SG_ 2566848256 WaterInFuelAlarm_ISig_3 60000;
BA_REL_ "GenSigFirstTimeoutTime" BU_SG_REL_ HMIIOM SG_ 2566848256 WaterInFuelAlarm_ISig_3 65000;
BA_REL_ "GenSigTimeoutTime" BU_SG_REL_ HMIIOM SG_ 2566848256 WaterInFuelAlarm_ISig_3 60000;
BA_REL_ "GenSigFirstTimeoutTime" BU_SG_REL_ VGGSECUSystem SG_ 2566848256 WaterInFuelAlarm_ISig_3 65000;
BA_REL_ "GenSigTimeoutTime" BU_SG_REL_ VGGSECUSystem SG_ 2566848256 WaterInFuelAlarm_ISig_3 60000;
BA_REL_ "GenSigFirstTimeoutTime" BU_SG_REL_ BBM SG_ 2499751697 RearAxle2DiffLock_stat_ISig_3 3000;
BA_REL_ "GenSigTimeoutTime" BU_SG_REL_ BBM SG_ 2499751697 RearAxle2DiffLock_stat_ISig_3 600;
BA_REL_ "GenSigFirstTimeoutTime" BU_SG_REL_ TECU SG_ 2499751697 RearAxle2DiffLock_stat_ISig_3 3000;
BA_REL_ "GenSigTimeoutTime" BU_SG_REL_ TECU SG_ 2499751697 RearAxle2DiffLock_stat_ISig_3 600;
BA_REL_ "GenSigFirstTimeoutTime" BU_SG_REL_ HMIIOM SG_ 2499751697 RearAxle2DiffLock_stat_ISig_3 3000;
BA_REL_ "GenSigTimeoutTime" BU_SG_REL_ HMIIOM SG_ 2499751697 RearAxle2DiffLock_stat_ISig_3 600;
BA_REL_ "GenSigFirstTimeoutTime" BU_SG_REL_ EMS SG_ 2499751697 EngineStopReqBackup 3000;
BA_REL_ "GenSigTimeoutTime" BU_SG_REL_ EMS SG_ 2499751697 EngineStopReqBackup 600;
BA_REL_ "GenSigFirstTimeoutTime" BU_SG_REL_ HMIIOM SG_ 2499751697 DifferentialLockStateCentral_ISi 3000;
BA_REL_ "GenSigTimeoutTime" BU_SG_REL_ HMIIOM SG_ 2499751697 DifferentialLockStateCentral_ISi 600;
BA_REL_ "GenSigFirstTimeoutTime" BU_SG_REL_ BBM SG_ 2499751697 DifferentialLockStateCentral_ISi 3000;
BA_REL_ "GenSigTimeoutTime" BU_SG_REL_ BBM SG_ 2499751697 DifferentialLockStateCentral_ISi 600;
BA_REL_ "GenSigFirstTimeoutTime" BU_SG_REL_ TECU SG_ 2499751697 DifferentialLockStateCentral_ISi 3000;
BA_REL_ "GenSigTimeoutTime" BU_SG_REL_ TECU SG_ 2499751697 DifferentialLockStateCentral_ISi 600;
BA_REL_ "GenSigFirstTimeoutTime" BU_SG_REL_ EBS SG_ 2499751697 DifferentialLockStateCentral_ISi 3000;
BA_REL_ "GenSigTimeoutTime" BU_SG_REL_ EBS SG_ 2499751697 DifferentialLockStateCentral_ISi 600;
BA_REL_ "GenSigFirstTimeoutTime" BU_SG_REL_ EMS SG_ 2499751697 DifferentialLockStateCentral_ISi 3000;
BA_REL_ "GenSigTimeoutTime" BU_SG_REL_ EMS SG_ 2499751697 DifferentialLockStateCentral_ISi 600;
BA_REL_ "GenSigFirstTimeoutTime" BU_SG_REL_ HMIIOM SG_ 2499751697 RearPropulsionStat_Rear1Axle_ISi 3000;
BA_REL_ "GenSigTimeoutTime" BU_SG_REL_ HMIIOM SG_ 2499751697 RearPropulsionStat_Rear1Axle_ISi 600;
BA_REL_ "GenSigFirstTimeoutTime" BU_SG_REL_ EBS SG_ 2499751697 RearPropulsionStat_Rear1Axle_ISi 3000;
BA_REL_ "GenSigTimeoutTime" BU_SG_REL_ EBS SG_ 2499751697 RearPropulsionStat_Rear1Axle_ISi 600;
BA_REL_ "GenSigFirstTimeoutTime" BU_SG_REL_ EMS SG_ 2499751697 RearPropulsionStat_Rear1Axle_ISi 3000;
BA_REL_ "GenSigTimeoutTime" BU_SG_REL_ EMS SG_ 2499751697 RearPropulsionStat_Rear1Axle_ISi 600;
BA_REL_ "GenSigFirstTimeoutTime" BU_SG_REL_ TECU SG_ 2499751697 RearPropulsionStat_Rear1Axle_ISi 3000;
BA_REL_ "GenSigTimeoutTime" BU_SG_REL_ TECU SG_ 2499751697 RearPropulsionStat_Rear1Axle_ISi 600;
BA_REL_ "GenSigFirstTimeoutTime" BU_SG_REL_ BBM SG_ 2499751697 RearPropulsionStat_Rear1Axle_ISi 3000;
BA_REL_ "GenSigTimeoutTime" BU_SG_REL_ BBM SG_ 2499751697 RearPropulsionStat_Rear1Axle_ISi 600;
BA_REL_ "GenSigFirstTimeoutTime" BU_SG_REL_ DACU SG_ 2499751697 RearPropulsionStat_Rear1Axle_ISi 3000;
BA_REL_ "GenSigTimeoutTime" BU_SG_REL_ DACU SG_ 2499751697 RearPropulsionStat_Rear1Axle_ISi 600;
BA_REL_ "GenSigFirstTimeoutTime" BU_SG_REL_ EBS SG_ 2499751697 DifferentialLockStateCentral2 3000;
BA_REL_ "GenSigTimeoutTime" BU_SG_REL_ EBS SG_ 2499751697 DifferentialLockStateCentral2 600;
BA_REL_ "GenSigFirstTimeoutTime" BU_SG_REL_ HMIIOM SG_ 2499751697 DifferentialLockStateCentral2 3000;
BA_REL_ "GenSigTimeoutTime" BU_SG_REL_ HMIIOM SG_ 2499751697 DifferentialLockStateCentral2 600;
BA_REL_ "GenSigFirstTimeoutTime" BU_SG_REL_ HMIIOM SG_ 2499751697 SetHSAOperation_ISig_3 3000;
BA_REL_ "GenSigTimeoutTime" BU_SG_REL_ HMIIOM SG_ 2499751697 SetHSAOperation_ISig_3 600;
BA_REL_ "GenSigFirstTimeoutTime" BU_SG_REL_ EBS SG_ 2499751697 SetHSAOperation_ISig_3 3000;
BA_REL_ "GenSigTimeoutTime" BU_SG_REL_ EBS SG_ 2499751697 SetHSAOperation_ISig_3 600;
BA_REL_ "GenSigFirstTimeoutTime" BU_SG_REL_ HMIIOM SG_ 2499751697 CentralRearDiffLock_stat_ISig_3 3000;
BA_REL_ "GenSigTimeoutTime" BU_SG_REL_ HMIIOM SG_ 2499751697 CentralRearDiffLock_stat_ISig_3 600;
BA_REL_ "GenSigFirstTimeoutTime" BU_SG_REL_ TECU SG_ 2499751697 CentralRearDiffLock_stat_ISig_3 3000;
BA_REL_ "GenSigTimeoutTime" BU_SG_REL_ TECU SG_ 2499751697 CentralRearDiffLock_stat_ISig_3 600;
BA_REL_ "GenSigFirstTimeoutTime" BU_SG_REL_ BBM SG_ 2499751697 CentralRearDiffLock_stat_ISig_3 3000;
BA_REL_ "GenSigTimeoutTime" BU_SG_REL_ BBM SG_ 2499751697 CentralRearDiffLock_stat_ISig_3 600;
BA_REL_ "GenSigFirstTimeoutTime" BU_SG_REL_ VGGSECUSystem SG_ 2499751697 LowAirPressureAlert_ISig_3 3000;
BA_REL_ "GenSigTimeoutTime" BU_SG_REL_ VGGSECUSystem SG_ 2499751697 LowAirPressureAlert_ISig_3 600;
BA_REL_ "GenSigFirstTimeoutTime" BU_SG_REL_ HMIIOM SG_ 2499751697 LowAirPressureAlert_ISig_3 3000;
BA_REL_ "GenSigTimeoutTime" BU_SG_REL_ HMIIOM SG_ 2499751697 LowAirPressureAlert_ISig_3 600;
BA_REL_ "GenSigFirstTimeoutTime" BU_SG_REL_ EMS SG_ 2499751697 LowAirPressureAlert_ISig_3 3000;
BA_REL_ "GenSigTimeoutTime" BU_SG_REL_ EMS SG_ 2499751697 LowAirPressureAlert_ISig_3 600;
BA_REL_ "GenSigFirstTimeoutTime" BU_SG_REL_ DACU SG_ 2499751697 RearPropulsionStat_Rear3Axle_ISi 3000;
BA_REL_ "GenSigTimeoutTime" BU_SG_REL_ DACU SG_ 2499751697 RearPropulsionStat_Rear3Axle_ISi 600;
BA_REL_ "GenSigFirstTimeoutTime" BU_SG_REL_ HMIIOM SG_ 2499751697 RearPropulsionStat_Rear3Axle_ISi 3000;
BA_REL_ "GenSigTimeoutTime" BU_SG_REL_ HMIIOM SG_ 2499751697 RearPropulsionStat_Rear3Axle_ISi 600;
BA_REL_ "GenSigFirstTimeoutTime" BU_SG_REL_ EMS SG_ 2499751697 RearPropulsionStat_Rear3Axle_ISi 3000;
BA_REL_ "GenSigTimeoutTime" BU_SG_REL_ EMS SG_ 2499751697 RearPropulsionStat_Rear3Axle_ISi 600;
BA_REL_ "GenSigFirstTimeoutTime" BU_SG_REL_ BBM SG_ 2499751697 RearPropulsionStat_Rear3Axle_ISi 3000;
BA_REL_ "GenSigTimeoutTime" BU_SG_REL_ BBM SG_ 2499751697 RearPropulsionStat_Rear3Axle_ISi 600;
BA_REL_ "GenSigFirstTimeoutTime" BU_SG_REL_ EBS SG_ 2499751697 RearPropulsionStat_Rear3Axle_ISi 3000;
BA_REL_ "GenSigTimeoutTime" BU_SG_REL_ EBS SG_ 2499751697 RearPropulsionStat_Rear3Axle_ISi 600;
BA_REL_ "GenSigFirstTimeoutTime" BU_SG_REL_ TECU SG_ 2499751697 RearPropulsionStat_Rear3Axle_ISi 3000;
BA_REL_ "GenSigTimeoutTime" BU_SG_REL_ TECU SG_ 2499751697 RearPropulsionStat_Rear3Axle_ISi 600;
BA_REL_ "GenSigFirstTimeoutTime" BU_SG_REL_ HMIIOM SG_ 2499751697 DifferentialLockStateFrAxle2 3000;
BA_REL_ "GenSigTimeoutTime" BU_SG_REL_ HMIIOM SG_ 2499751697 DifferentialLockStateFrAxle2 600;
BA_REL_ "GenSigFirstTimeoutTime" BU_SG_REL_ EBS SG_ 2499751697 DifferentialLockStateFrAxle2 3000;
BA_REL_ "GenSigTimeoutTime" BU_SG_REL_ EBS SG_ 2499751697 DifferentialLockStateFrAxle2 600;
BA_REL_ "GenSigFirstTimeoutTime" BU_SG_REL_ EBS SG_ 2499751697 TrailerConnected_ISig_3 3000;
BA_REL_ "GenSigTimeoutTime" BU_SG_REL_ EBS SG_ 2499751697 TrailerConnected_ISig_3 600;
BA_REL_ "GenSigFirstTimeoutTime" BU_SG_REL_ TECU SG_ 2499751697 TrailerWithoutABS_ISig_3 3000;
BA_REL_ "GenSigTimeoutTime" BU_SG_REL_ TECU SG_ 2499751697 TrailerWithoutABS_ISig_3 600;
BA_REL_ "GenSigFirstTimeoutTime" BU_SG_REL_ EMS SG_ 2499751697 TrailerWithoutABS_ISig_3 3000;
BA_REL_ "GenSigTimeoutTime" BU_SG_REL_ EMS SG_ 2499751697 TrailerWithoutABS_ISig_3 600;
BA_REL_ "GenSigFirstTimeoutTime" BU_SG_REL_ DACU SG_ 2499751697 TrailerWithoutABS_ISig_3 3000;
BA_REL_ "GenSigTimeoutTime" BU_SG_REL_ DACU SG_ 2499751697 TrailerWithoutABS_ISig_3 600;
BA_REL_ "GenSigFirstTimeoutTime" BU_SG_REL_ EBS SG_ 2499751697 TrailerWithoutABS_ISig_3 3000;
BA_REL_ "GenSigTimeoutTime" BU_SG_REL_ EBS SG_ 2499751697 TrailerWithoutABS_ISig_3 600;
BA_REL_ "GenSigFirstTimeoutTime" BU_SG_REL_ HMIIOM SG_ 2499751697 TrailerWithoutABS_ISig_3 3000;
BA_REL_ "GenSigTimeoutTime" BU_SG_REL_ HMIIOM SG_ 2499751697 TrailerWithoutABS_ISig_3 600;
BA_REL_ "GenSigFirstTimeoutTime" BU_SG_REL_ EBS SG_ 2499751697 DifferentialLockStateFrAxle1_ISi 3000;
BA_REL_ "GenSigTimeoutTime" BU_SG_REL_ EBS SG_ 2499751697 DifferentialLockStateFrAxle1_ISi 600;
BA_REL_ "GenSigFirstTimeoutTime" BU_SG_REL_ HMIIOM SG_ 2499751697 DifferentialLockStateFrAxle1_ISi 3000;
BA_REL_ "GenSigTimeoutTime" BU_SG_REL_ HMIIOM SG_ 2499751697 DifferentialLockStateFrAxle1_ISi 600;
BA_REL_ "GenSigFirstTimeoutTime" BU_SG_REL_ BBM SG_ 2499751697 DifferentialLockStateFrAxle1_ISi 3000;
BA_REL_ "GenSigTimeoutTime" BU_SG_REL_ BBM SG_ 2499751697 DifferentialLockStateFrAxle1_ISi 600;
BA_REL_ "GenSigFirstTimeoutTime" BU_SG_REL_ EBS SG_ 2499751697 RearPropulsionStat_Rear2Axle_ISi 3000;
BA_REL_ "GenSigTimeoutTime" BU_SG_REL_ EBS SG_ 2499751697 RearPropulsionStat_Rear2Axle_ISi 600;
BA_REL_ "GenSigFirstTimeoutTime" BU_SG_REL_ BBM SG_ 2499751697 RearPropulsionStat_Rear2Axle_ISi 3000;
BA_REL_ "GenSigTimeoutTime" BU_SG_REL_ BBM SG_ 2499751697 RearPropulsionStat_Rear2Axle_ISi 600;
BA_REL_ "GenSigFirstTimeoutTime" BU_SG_REL_ EMS SG_ 2499751697 RearPropulsionStat_Rear2Axle_ISi 3000;
BA_REL_ "GenSigTimeoutTime" BU_SG_REL_ EMS SG_ 2499751697 RearPropulsionStat_Rear2Axle_ISi 600;
BA_REL_ "GenSigFirstTimeoutTime" BU_SG_REL_ HMIIOM SG_ 2499751697 RearPropulsionStat_Rear2Axle_ISi 3000;
BA_REL_ "GenSigTimeoutTime" BU_SG_REL_ HMIIOM SG_ 2499751697 RearPropulsionStat_Rear2Axle_ISi 600;
BA_REL_ "GenSigFirstTimeoutTime" BU_SG_REL_ DACU SG_ 2499751697 RearPropulsionStat_Rear2Axle_ISi 3000;
BA_REL_ "GenSigTimeoutTime" BU_SG_REL_ DACU SG_ 2499751697 RearPropulsionStat_Rear2Axle_ISi 600;
BA_REL_ "GenSigFirstTimeoutTime" BU_SG_REL_ TECU SG_ 2499751697 RearPropulsionStat_Rear2Axle_ISi 3000;
BA_REL_ "GenSigTimeoutTime" BU_SG_REL_ TECU SG_ 2499751697 RearPropulsionStat_Rear2Axle_ISi 600;
BA_REL_ "GenSigFirstTimeoutTime" BU_SG_REL_ HMIIOM SG_ 2499751697 RearAxle1DiffLock_stat_ISig_3 3000;
BA_REL_ "GenSigTimeoutTime" BU_SG_REL_ HMIIOM SG_ 2499751697 RearAxle1DiffLock_stat_ISig_3 600;
BA_REL_ "GenSigFirstTimeoutTime" BU_SG_REL_ BBM SG_ 2499751697 RearAxle1DiffLock_stat_ISig_3 3000;
BA_REL_ "GenSigTimeoutTime" BU_SG_REL_ BBM SG_ 2499751697 RearAxle1DiffLock_stat_ISig_3 600;
BA_REL_ "GenSigFirstTimeoutTime" BU_SG_REL_ TECU SG_ 2499751697 RearAxle1DiffLock_stat_ISig_3 3000;
BA_REL_ "GenSigTimeoutTime" BU_SG_REL_ TECU SG_ 2499751697 RearAxle1DiffLock_stat_ISig_3 600;
BA_REL_ "GenSigFirstTimeoutTime" BU_SG_REL_ EBS SG_ 2566897425 StretchBrakeEnable_rqst 12000;
BA_REL_ "GenSigTimeoutTime" BU_SG_REL_ EBS SG_ 2566897425 StretchBrakeEnable_rqst 3000;
BA_REL_ "GenSigFirstTimeoutTime" BU_SG_REL_ HMIIOM SG_ 2566897425 FuelLevel_ISig_3 11760;
BA_REL_ "GenSigTimeoutTime" BU_SG_REL_ HMIIOM SG_ 2566897425 FuelLevel_ISig_3 2940;
BA_REL_ "GenSigFirstTimeoutTime" BU_SG_REL_ BBM SG_ 2566897425 FuelLevel_ISig_3 11760;
BA_REL_ "GenSigTimeoutTime" BU_SG_REL_ BBM SG_ 2566897425 FuelLevel_ISig_3 2940;
BA_REL_ "GenSigFirstTimeoutTime" BU_SG_REL_ CIOM SG_ 2566897425 FuelLevel_ISig_3 11760;
BA_REL_ "GenSigTimeoutTime" BU_SG_REL_ CIOM SG_ 2566897425 FuelLevel_ISig_3 2940;
BA_REL_ "GenSigFirstTimeoutTime" BU_SG_REL_ EMS SG_ 2566897425 FuelLevel_ISig_3 12000;
BA_REL_ "GenSigTimeoutTime" BU_SG_REL_ EMS SG_ 2566897425 FuelLevel_ISig_3 3000;
BA_REL_ "GenSigFirstTimeoutTime" BU_SG_REL_ EBS SG_ 2566897425 StaticTrailerBrake_rqst 12000;
BA_REL_ "GenSigTimeoutTime" BU_SG_REL_ EBS SG_ 2566897425 StaticTrailerBrake_rqst 3000;
BA_REL_ "GenSigFirstTimeoutTime" BU_SG_REL_ HMIIOM SG_ 2298429457 SWBrakeSwitch_ISig_3 3000;
BA_REL_ "GenSigTimeoutTime" BU_SG_REL_ HMIIOM SG_ 2298429457 SWBrakeSwitch_ISig_3 500;
BA_REL_ "GenSigFirstTimeoutTime" BU_SG_REL_ EBS SG_ 2298429457 SWBrakeSwitch_ISig_3 3000;
BA_REL_ "GenSigTimeoutTime" BU_SG_REL_ EBS SG_ 2298429457 SWBrakeSwitch_ISig_3 500;
BA_REL_ "GenSigFirstTimeoutTime" BU_SG_REL_ EBS SG_ 2298429457 ClutchPedalPosition_ISig_3 3000;
BA_REL_ "GenSigTimeoutTime" BU_SG_REL_ EBS SG_ 2298429457 ClutchPedalPosition_ISig_3 60;
BA_REL_ "GenSigFirstTimeoutTime" BU_SG_REL_ RECU_Virt SG_ 2298429457 TransmissionOutputShaftSpeed_ISi 3000;
BA_REL_ "GenSigTimeoutTime" BU_SG_REL_ RECU_Virt SG_ 2298429457 TransmissionOutputShaftSpeed_ISi 60;
BA_REL_ "GenSigFirstTimeoutTime" BU_SG_REL_ EMS SG_ 2298429457 TransmissionOutputShaftSpeed_ISi 3000;
BA_REL_ "GenSigTimeoutTime" BU_SG_REL_ EMS SG_ 2298429457 TransmissionOutputShaftSpeed_ISi 60;
BA_REL_ "GenSigFirstTimeoutTime" BU_SG_REL_ BBM SG_ 2298429457 TransmissionOutputShaftSpeed_ISi 3000;
BA_REL_ "GenSigTimeoutTime" BU_SG_REL_ BBM SG_ 2298429457 TransmissionOutputShaftSpeed_ISi 60;
BA_REL_ "GenSigFirstTimeoutTime" BU_SG_REL_ ACM SG_ 2298429457 VehicleMode_ISig_3 3000;
BA_REL_ "GenSigTimeoutTime" BU_SG_REL_ ACM SG_ 2298429457 VehicleMode_ISig_3 500;
BA_REL_ "GenSigFirstTimeoutTime" BU_SG_REL_ HMIIOM SG_ 2298429457 VehicleMode_ISig_3 3000;
BA_REL_ "GenSigTimeoutTime" BU_SG_REL_ HMIIOM SG_ 2298429457 VehicleMode_ISig_3 500;
BA_REL_ "GenSigFirstTimeoutTime" BU_SG_REL_ CIOM SG_ 2298429457 VehicleMode_ISig_3 3000;
BA_REL_ "GenSigTimeoutTime" BU_SG_REL_ CIOM SG_ 2298429457 VehicleMode_ISig_3 500;
BA_REL_ "GenSigFirstTimeoutTime" BU_SG_REL_ DACU SG_ 2298429457 VehicleMode_ISig_3 3000;
BA_REL_ "GenSigTimeoutTime" BU_SG_REL_ DACU SG_ 2298429457 VehicleMode_ISig_3 500;
BA_REL_ "GenSigFirstTimeoutTime" BU_SG_REL_ TECU SG_ 2298429457 VehicleMode_ISig_3 3000;
BA_REL_ "GenSigTimeoutTime" BU_SG_REL_ TECU SG_ 2298429457 VehicleMode_ISig_3 500;
BA_REL_ "GenSigFirstTimeoutTime" BU_SG_REL_ TACHO SG_ 2298429457 VehicleMode_ISig_3 3000;
BA_REL_ "GenSigTimeoutTime" BU_SG_REL_ TACHO SG_ 2298429457 VehicleMode_ISig_3 500;
BA_REL_ "GenSigFirstTimeoutTime" BU_SG_REL_ EMS SG_ 2298429457 VehicleMode_ISig_3 3000;
BA_REL_ "GenSigTimeoutTime" BU_SG_REL_ EMS SG_ 2298429457 VehicleMode_ISig_3 500;
BA_REL_ "GenSigFirstTimeoutTime" BU_SG_REL_ VGGSECUSystem SG_ 2298429457 VehicleMode_ISig_3 3000;
BA_REL_ "GenSigTimeoutTime" BU_SG_REL_ VGGSECUSystem SG_ 2298429457 VehicleMode_ISig_3 500;
BA_REL_ "GenSigFirstTimeoutTime" BU_SG_REL_ BBM SG_ 2298429457 VehicleMode_ISig_3 3000;
BA_REL_ "GenSigTimeoutTime" BU_SG_REL_ BBM SG_ 2298429457 VehicleMode_ISig_3 500;
BA_REL_ "GenSigFirstTimeoutTime" BU_SG_REL_ EBS SG_ 2298429457 VehicleMode_ISig_3 3000;
BA_REL_ "GenSigTimeoutTime" BU_SG_REL_ EBS SG_ 2298429457 VehicleMode_ISig_3 500;
BA_REL_ "GenSigFirstTimeoutTime" BU_SG_REL_ BBM SG_ 2298429457 AcctrPedalKickDownSw_stat_ISig_3 3000;
BA_REL_ "GenSigTimeoutTime" BU_SG_REL_ BBM SG_ 2298429457 AcctrPedalKickDownSw_stat_ISig_3 60;
BA_REL_ "GenSigFirstTimeoutTime" BU_SG_REL_ TECU SG_ 2298429457 AcctrPedalKickDownSw_stat_ISig_3 3000;
BA_REL_ "GenSigTimeoutTime" BU_SG_REL_ TECU SG_ 2298429457 AcctrPedalKickDownSw_stat_ISig_3 60;
BA_REL_ "GenSigFirstTimeoutTime" BU_SG_REL_ HMIIOM SG_ 2298429457 AcctrPedalKickDownSw_stat_ISig_3 3000;
BA_REL_ "GenSigTimeoutTime" BU_SG_REL_ HMIIOM SG_ 2298429457 AcctrPedalKickDownSw_stat_ISig_3 100;
BA_REL_ "GenSigFirstTimeoutTime" BU_SG_REL_ EMS SG_ 2298429457 AcctrPedalKickDownSw_stat_ISig_3 3000;
BA_REL_ "GenSigTimeoutTime" BU_SG_REL_ EMS SG_ 2298429457 AcctrPedalKickDownSw_stat_ISig_3 60;
BA_REL_ "GenSigFirstTimeoutTime" BU_SG_REL_ DACU SG_ 2298429457 AcctrPedalKickDownSw_stat_ISig_3 3000;
BA_REL_ "GenSigTimeoutTime" BU_SG_REL_ DACU SG_ 2298429457 AcctrPedalKickDownSw_stat_ISig_3 60;
BA_REL_ "GenSigFirstTimeoutTime" BU_SG_REL_ HMIIOM SG_ 2298429457 BrakePedalPosition_ISig_3 3000;
BA_REL_ "GenSigTimeoutTime" BU_SG_REL_ HMIIOM SG_ 2298429457 BrakePedalPosition_ISig_3 60;
BA_REL_ "GenSigFirstTimeoutTime" BU_SG_REL_ TECU SG_ 2298429457 BrakePedalPosition_ISig_3 3000;
BA_REL_ "GenSigTimeoutTime" BU_SG_REL_ TECU SG_ 2298429457 BrakePedalPosition_ISig_3 60;
BA_REL_ "GenSigFirstTimeoutTime" BU_SG_REL_ EBS SG_ 2298429457 BrakePedalPosition_ISig_3 3000;
BA_REL_ "GenSigTimeoutTime" BU_SG_REL_ EBS SG_ 2298429457 BrakePedalPosition_ISig_3 60;
BA_REL_ "GenSigFirstTimeoutTime" BU_SG_REL_ CIOM SG_ 2298429457 BrakePedalPosition_ISig_3 3000;
BA_REL_ "GenSigTimeoutTime" BU_SG_REL_ CIOM SG_ 2298429457 BrakePedalPosition_ISig_3 60;
BA_REL_ "GenSigFirstTimeoutTime" BU_SG_REL_ DACU SG_ 2298429457 BrakePedalPosition_ISig_3 3000;
BA_REL_ "GenSigTimeoutTime" BU_SG_REL_ DACU SG_ 2298429457 BrakePedalPosition_ISig_3 60;
BA_REL_ "GenSigFirstTimeoutTime" BU_SG_REL_ BBM SG_ 2298429457 BrakePedalPosition_ISig_3 3000;
BA_REL_ "GenSigTimeoutTime" BU_SG_REL_ BBM SG_ 2298429457 BrakePedalPosition_ISig_3 60;
BA_REL_ "GenSigFirstTimeoutTime" BU_SG_REL_ EBS SG_ 2298429457 BrakePressureSensorDemand_ISig_3 3000;
BA_REL_ "GenSigTimeoutTime" BU_SG_REL_ EBS SG_ 2298429457 BrakePressureSensorDemand_ISig_3 500;
BA_REL_ "GenSigFirstTimeoutTime" BU_SG_REL_ HMIIOM SG_ 2298429457 AcceleratorPedalLowIdleSwitch_IS 3000;
BA_REL_ "GenSigTimeoutTime" BU_SG_REL_ HMIIOM SG_ 2298429457 AcceleratorPedalLowIdleSwitch_IS 60;
BA_REL_ "GenSigFirstTimeoutTime" BU_SG_REL_ BBM SG_ 2298429457 AcceleratorPedalLowIdleSwitch_IS 3000;
BA_REL_ "GenSigTimeoutTime" BU_SG_REL_ BBM SG_ 2298429457 AcceleratorPedalLowIdleSwitch_IS 60;
BA_REL_ "GenSigFirstTimeoutTime" BU_SG_REL_ TECU SG_ 2298429457 AcceleratorPedalLowIdleSwitch_IS 3000;
BA_REL_ "GenSigTimeoutTime" BU_SG_REL_ TECU SG_ 2298429457 AcceleratorPedalLowIdleSwitch_IS 60;
BA_REL_ "GenSigFirstTimeoutTime" BU_SG_REL_ EMS SG_ 2298429457 AcceleratorPedalPosition1_ISig_3 3000;
BA_REL_ "GenSigTimeoutTime" BU_SG_REL_ EMS SG_ 2298429457 AcceleratorPedalPosition1_ISig_3 60;
BA_REL_ "GenSigFirstTimeoutTime" BU_SG_REL_ BBM SG_ 2298429457 AcceleratorPedalPosition1_ISig_3 3000;
BA_REL_ "GenSigTimeoutTime" BU_SG_REL_ BBM SG_ 2298429457 AcceleratorPedalPosition1_ISig_3 60;
BA_REL_ "GenSigFirstTimeoutTime" BU_SG_REL_ DACU SG_ 2298429457 AcceleratorPedalPosition1_ISig_3 3000;
BA_REL_ "GenSigTimeoutTime" BU_SG_REL_ DACU SG_ 2298429457 AcceleratorPedalPosition1_ISig_3 60;
BA_REL_ "GenSigFirstTimeoutTime" BU_SG_REL_ EBS SG_ 2298429457 AcceleratorPedalPosition1_ISig_3 3000;
BA_REL_ "GenSigTimeoutTime" BU_SG_REL_ EBS SG_ 2298429457 AcceleratorPedalPosition1_ISig_3 60;
BA_REL_ "GenSigFirstTimeoutTime" BU_SG_REL_ HMIIOM SG_ 2298429457 AcceleratorPedalPosition1_ISig_3 3000;
BA_REL_ "GenSigTimeoutTime" BU_SG_REL_ HMIIOM SG_ 2298429457 AcceleratorPedalPosition1_ISig_3 60;
BA_REL_ "GenSigFirstTimeoutTime" BU_SG_REL_ TECU SG_ 2298429457 AcceleratorPedalPosition1_ISig_3 3000;
BA_REL_ "GenSigTimeoutTime" BU_SG_REL_ TECU SG_ 2298429457 AcceleratorPedalPosition1_ISig_3 60;
BA_REL_ "GenSigFirstTimeoutTime" BU_SG_REL_ CIOM SG_ 2298429457 AcceleratorPedalPosition1_ISig_3 3000;
BA_REL_ "GenSigTimeoutTime" BU_SG_REL_ CIOM SG_ 2298429457 AcceleratorPedalPosition1_ISig_3 60;
BA_REL_ "GenSigFirstTimeoutTime" BU_SG_REL_ HMIIOM SG_ 2566906094 RemningTimeTillNxtWklyRestPrd_IS 65535;
BA_REL_ "GenSigTimeoutTime" BU_SG_REL_ HMIIOM SG_ 2566906094 RemningTimeTillNxtWklyRestPrd_IS 65535;
BA_REL_ "GenSigFirstTimeoutTime" BU_SG_REL_ HMIIOM SG_ 2566906094 RemainingCurDailyDrivingTime_ISi 65535;
BA_REL_ "GenSigTimeoutTime" BU_SG_REL_ HMIIOM SG_ 2566906094 RemainingCurDailyDrivingTime_ISi 65535;
BA_REL_ "GenSigFirstTimeoutTime" BU_SG_REL_ HMIIOM SG_ 2566906094 RemainingCurrentDrivingTime_ISig 65535;
BA_REL_ "GenSigTimeoutTime" BU_SG_REL_ HMIIOM SG_ 2566906094 RemainingCurrentDrivingTime_ISig 65535;
BA_REL_ "GenSigFirstTimeoutTime" BU_SG_REL_ HMIIOM SG_ 2566906094 SingleMultiDriver_ISig_3 65535;
BA_REL_ "GenSigTimeoutTime" BU_SG_REL_ HMIIOM SG_ 2566906094 SingleMultiDriver_ISig_3 65535;
BA_REL_ "GenSigFirstTimeoutTime" BU_SG_REL_ HMIIOM SG_ 2566906094 UnknownPeriods_ISig_3 65535;
BA_REL_ "GenSigTimeoutTime" BU_SG_REL_ HMIIOM SG_ 2566906094 UnknownPeriods_ISig_3 65535;
BA_REL_ "GenSigFirstTimeoutTime" BU_SG_REL_ HMIIOM SG_ 2566906094 OpenCompensationWeekBfrLast_ISig 65535;
BA_REL_ "GenSigTimeoutTime" BU_SG_REL_ HMIIOM SG_ 2566906094 OpenCompensationWeekBfrLast_ISig 65535;
BA_REL_ "GenSigFirstTimeoutTime" BU_SG_REL_ HMIIOM SG_ 2566906094 RemainingReducedDailyRestPrd_ISi 65535;
BA_REL_ "GenSigTimeoutTime" BU_SG_REL_ HMIIOM SG_ 2566906094 RemainingReducedDailyRestPrd_ISi 65535;
BA_REL_ "GenSigFirstTimeoutTime" BU_SG_REL_ HMIIOM SG_ 2566906094 RemainingDurOfCurBreakRest_ISig_ 65535;
BA_REL_ "GenSigTimeoutTime" BU_SG_REL_ HMIIOM SG_ 2566906094 RemainingDurOfCurBreakRest_ISig_ 65535;
BA_REL_ "GenSigFirstTimeoutTime" BU_SG_REL_ HMIIOM SG_ 2566906094 RemainingTimeTillNextRestBreak_I 65535;
BA_REL_ "GenSigTimeoutTime" BU_SG_REL_ HMIIOM SG_ 2566906094 RemainingTimeTillNextRestBreak_I 65535;
BA_REL_ "GenSigFirstTimeoutTime" BU_SG_REL_ HMIIOM SG_ 2566906094 NextDrivingPeriod_ISig_3 65535;
BA_REL_ "GenSigTimeoutTime" BU_SG_REL_ HMIIOM SG_ 2566906094 NextDrivingPeriod_ISig_3 65535;
BA_REL_ "GenSigFirstTimeoutTime" BU_SG_REL_ HMIIOM SG_ 2566906094 DurationOfNextRestBreak_ISig_3 65535;
BA_REL_ "GenSigTimeoutTime" BU_SG_REL_ HMIIOM SG_ 2566906094 DurationOfNextRestBreak_ISig_3 65535;
BA_REL_ "GenSigFirstTimeoutTime" BU_SG_REL_ HMIIOM SG_ 2566906094 RemainingDrivTimeOfCurWeek_ISig_ 65535;
BA_REL_ "GenSigTimeoutTime" BU_SG_REL_ HMIIOM SG_ 2566906094 RemainingDrivTimeOfCurWeek_ISig_ 65535;
BA_REL_ "GenSigFirstTimeoutTime" BU_SG_REL_ HMIIOM SG_ 2566906094 DurationOfNextDailyRestPeriod_IS 65535;
BA_REL_ "GenSigTimeoutTime" BU_SG_REL_ HMIIOM SG_ 2566906094 DurationOfNextDailyRestPeriod_IS 65535;
BA_REL_ "GenSigFirstTimeoutTime" BU_SG_REL_ HMIIOM SG_ 2566906094 OpenCompensationInTheLastWeek_IS 65535;
BA_REL_ "GenSigTimeoutTime" BU_SG_REL_ HMIIOM SG_ 2566906094 OpenCompensationInTheLastWeek_IS 65535;
BA_REL_ "GenSigFirstTimeoutTime" BU_SG_REL_ HMIIOM SG_ 2566906094 TimeOverlap_ISig_3 65535;
BA_REL_ "GenSigTimeoutTime" BU_SG_REL_ HMIIOM SG_ 2566906094 TimeOverlap_ISig_3 65535;
BA_REL_ "GenSigFirstTimeoutTime" BU_SG_REL_ HMIIOM SG_ 2566906094 TimeBeforeStartOfNxtDrvngPrd_ISi 65535;
BA_REL_ "GenSigTimeoutTime" BU_SG_REL_ HMIIOM SG_ 2566906094 TimeBeforeStartOfNxtDrvngPrd_ISi 65535;
BA_REL_ "GenSigFirstTimeoutTime" BU_SG_REL_ HMIIOM SG_ 2566906094 WklyRestPrdCalcEnabledDisabled_I 65535;
BA_REL_ "GenSigTimeoutTime" BU_SG_REL_ HMIIOM SG_ 2566906094 WklyRestPrdCalcEnabledDisabled_I 65535;
BA_REL_ "GenSigFirstTimeoutTime" BU_SG_REL_ HMIIOM SG_ 2566906094 Remaining10hDrvTime_ISig_3 65535;
BA_REL_ "GenSigTimeoutTime" BU_SG_REL_ HMIIOM SG_ 2566906094 Remaining10hDrvTime_ISig_3 65535;
BA_REL_ "GenSigFirstTimeoutTime" BU_SG_REL_ HMIIOM SG_ 2566906094 RemnngTimeTillNxtDailyRestPrd_IS 65535;
BA_REL_ "GenSigTimeoutTime" BU_SG_REL_ HMIIOM SG_ 2566906094 RemnngTimeTillNxtDailyRestPrd_IS 65535;
BA_REL_ "GenSigFirstTimeoutTime" BU_SG_REL_ HMIIOM SG_ 2566906094 DurationOfNextWeeklyRestPeriod_I 65535;
BA_REL_ "GenSigTimeoutTime" BU_SG_REL_ HMIIOM SG_ 2566906094 DurationOfNextWeeklyRestPeriod_I 65535;
BA_REL_ "GenSigFirstTimeoutTime" BU_SG_REL_ HMIIOM SG_ 2566906094 OpenCompensation2ndWeekBfrLast_I 65535;
BA_REL_ "GenSigTimeoutTime" BU_SG_REL_ HMIIOM SG_ 2566906094 OpenCompensation2ndWeekBfrLast_I 65535;
BA_REL_ "GenSigFirstTimeoutTime" BU_SG_REL_ HMIIOM SG_ 2566906094 SufficientData_ISig_3 65535;
BA_REL_ "GenSigTimeoutTime" BU_SG_REL_ HMIIOM SG_ 2566906094 SufficientData_ISig_3 65535;
BA_REL_ "GenSigFirstTimeoutTime" BU_SG_REL_ HMIIOM SG_ 2566832401 TotalVehicleDistanceHighRes_ISig 24000;
BA_REL_ "GenSigTimeoutTime" BU_SG_REL_ HMIIOM SG_ 2566832401 TotalVehicleDistanceHighRes_ISig 6000;
BA_REL_ "GenSigFirstTimeoutTime" BU_SG_REL_ EBS SG_ 2566832401 TotalVehicleDistanceHighRes_ISig 24000;
BA_REL_ "GenSigTimeoutTime" BU_SG_REL_ EBS SG_ 2566832401 TotalVehicleDistanceHighRes_ISig 6000;
BA_REL_ "GenSigFirstTimeoutTime" BU_SG_REL_ EMS SG_ 2566832401 TotalVehicleDistanceHighRes_ISig 24000;
BA_REL_ "GenSigTimeoutTime" BU_SG_REL_ EMS SG_ 2566832401 TotalVehicleDistanceHighRes_ISig 6000;
BA_REL_ "GenSigFirstTimeoutTime" BU_SG_REL_ ACM SG_ 2566832401 TotalVehicleDistanceHighRes_ISig 24000;
BA_REL_ "GenSigTimeoutTime" BU_SG_REL_ ACM SG_ 2566832401 TotalVehicleDistanceHighRes_ISig 6000;
BA_REL_ "GenSigFirstTimeoutTime" BU_SG_REL_ DACU SG_ 2566832401 TotalVehicleDistanceHighRes_ISig 24000;
BA_REL_ "GenSigTimeoutTime" BU_SG_REL_ DACU SG_ 2566832401 TotalVehicleDistanceHighRes_ISig 6000;
BA_REL_ "GenSigFirstTimeoutTime" BU_SG_REL_ TECU SG_ 2566832401 TotalVehicleDistanceHighRes_ISig 24000;
BA_REL_ "GenSigTimeoutTime" BU_SG_REL_ TECU SG_ 2566832401 TotalVehicleDistanceHighRes_ISig 6000;
BA_REL_ "GenSigFirstTimeoutTime" BU_SG_REL_ CIOM SG_ 2566832401 TotalVehicleDistanceHighRes_ISig 24000;
BA_REL_ "GenSigTimeoutTime" BU_SG_REL_ CIOM SG_ 2566832401 TotalVehicleDistanceHighRes_ISig 6000;
BA_REL_ "GenSigFirstTimeoutTime" BU_SG_REL_ BBM SG_ 2566832401 TotalVehicleDistanceHighRes_ISig 24000;
BA_REL_ "GenSigTimeoutTime" BU_SG_REL_ BBM SG_ 2566832401 TotalVehicleDistanceHighRes_ISig 6000;
BA_REL_ "GenSigFirstTimeoutTime" BU_SG_REL_ VGGSECUSystem SG_ 2566832401 TotalVehicleDistanceHighRes_ISig 24000;
BA_REL_ "GenSigTimeoutTime" BU_SG_REL_ VGGSECUSystem SG_ 2566832401 TotalVehicleDistanceHighRes_ISig 6000;
BA_REL_ "GenSigFirstTimeoutTime" BU_SG_REL_ VMCU SG_ 2566832622 TachoHighResTotalVehDistance 24000;
BA_REL_ "GenSigTimeoutTime" BU_SG_REL_ VMCU SG_ 2566832622 TachoHighResTotalVehDistance 6000;
BA_REL_ "GenSigFirstTimeoutTime" BU_SG_REL_ HMIIOM SG_ 2364541195 LateralAcceleration_ISig_3 3000;
BA_REL_ "GenSigTimeoutTime" BU_SG_REL_ HMIIOM SG_ 2364541195 LateralAcceleration_ISig_3 120;
BA_REL_ "GenSigFirstTimeoutTime" BU_SG_REL_ BBM SG_ 2364541195 LateralAcceleration_ISig_3 3000;
BA_REL_ "GenSigTimeoutTime" BU_SG_REL_ BBM SG_ 2364541195 LateralAcceleration_ISig_3 60;
BA_REL_ "GenSigFirstTimeoutTime" BU_SG_REL_ DACU SG_ 2364541195 LateralAcceleration_ISig_3 3000;
BA_REL_ "GenSigTimeoutTime" BU_SG_REL_ DACU SG_ 2364541195 LateralAcceleration_ISig_3 600;
BA_REL_ "GenSigFirstTimeoutTime" BU_SG_REL_ CIOM SG_ 2364541195 SteeringWheelAngle_ISig_3 3000;
BA_REL_ "GenSigTimeoutTime" BU_SG_REL_ CIOM SG_ 2364541195 SteeringWheelAngle_ISig_3 60;
BA_REL_ "GenSigFirstTimeoutTime" BU_SG_REL_ BBM SG_ 2364541195 SteeringWheelAngle_ISig_3 3000;
BA_REL_ "GenSigTimeoutTime" BU_SG_REL_ BBM SG_ 2364541195 SteeringWheelAngle_ISig_3 120;
BA_REL_ "GenSigFirstTimeoutTime" BU_SG_REL_ VMCU SG_ 2364541195 SteeringWheelAngle_ISig_3 3000;
BA_REL_ "GenSigTimeoutTime" BU_SG_REL_ VMCU SG_ 2364541195 SteeringWheelAngle_ISig_3 120;
BA_REL_ "GenSigFirstTimeoutTime" BU_SG_REL_ DACU SG_ 2364541195 SteeringWheelAngle_ISig_3 3000;
BA_REL_ "GenSigTimeoutTime" BU_SG_REL_ DACU SG_ 2364541195 SteeringWheelAngle_ISig_3 120;
BA_REL_ "GenSigFirstTimeoutTime" BU_SG_REL_ VGGSECUSystem SG_ 2364541195 SteeringWheelAngle_ISig_3 3000;
BA_REL_ "GenSigTimeoutTime" BU_SG_REL_ VGGSECUSystem SG_ 2364541195 SteeringWheelAngle_ISig_3 60;
BA_REL_ "GenSigFirstTimeoutTime" BU_SG_REL_ BBM SG_ 2364541195 SteeringWheelTurnCounter_ISig_3 3000;
BA_REL_ "GenSigTimeoutTime" BU_SG_REL_ BBM SG_ 2364541195 SteeringWheelTurnCounter_ISig_3 120;
BA_REL_ "GenSigFirstTimeoutTime" BU_SG_REL_ BBM SG_ 2364541195 SteeringWheelAngleSensorType_ISi 3000;
BA_REL_ "GenSigTimeoutTime" BU_SG_REL_ BBM SG_ 2364541195 SteeringWheelAngleSensorType_ISi 120;
BA_REL_ "GenSigFirstTimeoutTime" BU_SG_REL_ HMIIOM SG_ 2364541195 YawRate_ISig_3 3000;
BA_REL_ "GenSigTimeoutTime" BU_SG_REL_ HMIIOM SG_ 2364541195 YawRate_ISig_3 120;
BA_REL_ "GenSigFirstTimeoutTime" BU_SG_REL_ BBM SG_ 2364541195 YawRate_ISig_3 3000;
BA_REL_ "GenSigTimeoutTime" BU_SG_REL_ BBM SG_ 2364541195 YawRate_ISig_3 60;
BA_REL_ "GenSigFirstTimeoutTime" BU_SG_REL_ DACU SG_ 2364541195 YawRate_ISig_3 3000;
BA_REL_ "GenSigTimeoutTime" BU_SG_REL_ DACU SG_ 2364541195 YawRate_ISig_3 120;
BA_REL_ "GenSigFirstTimeoutTime" BU_SG_REL_ HMIIOM SG_ 2566803211 ESCHealthStatus_ISig_3 3000;
BA_REL_ "GenSigTimeoutTime" BU_SG_REL_ HMIIOM SG_ 2566803211 ESCHealthStatus_ISig_3 600;
BA_REL_ "GenSigFirstTimeoutTime" BU_SG_REL_ VMCU SG_ 2566803211 ROPEngineControlActive_ISig_3 3000;
BA_REL_ "GenSigTimeoutTime" BU_SG_REL_ VMCU SG_ 2566803211 ROPEngineControlActive_ISig_3 600;
BA_REL_ "GenSigFirstTimeoutTime" BU_SG_REL_ HMIIOM SG_ 2566803211 ROPEngineControlActive_ISig_3 3000;
BA_REL_ "GenSigTimeoutTime" BU_SG_REL_ HMIIOM SG_ 2566803211 ROPEngineControlActive_ISig_3 600;
BA_REL_ "GenSigFirstTimeoutTime" BU_SG_REL_ DACU SG_ 2566803211 ROPEngineControlActive_ISig_3 3000;
BA_REL_ "GenSigTimeoutTime" BU_SG_REL_ DACU SG_ 2566803211 ROPEngineControlActive_ISig_3 600;
BA_REL_ "GenSigFirstTimeoutTime" BU_SG_REL_ TECU SG_ 2566803211 ROPEngineControlActive_ISig_3 3000;
BA_REL_ "GenSigTimeoutTime" BU_SG_REL_ TECU SG_ 2566803211 ROPEngineControlActive_ISig_3 600;
BA_REL_ "GenSigFirstTimeoutTime" BU_SG_REL_ HMIIOM SG_ 2566803211 YCEngineControlActive_ISig_3 3000;
BA_REL_ "GenSigTimeoutTime" BU_SG_REL_ HMIIOM SG_ 2566803211 YCEngineControlActive_ISig_3 600;
BA_REL_ "GenSigFirstTimeoutTime" BU_SG_REL_ DACU SG_ 2566803211 YCEngineControlActive_ISig_3 3000;
BA_REL_ "GenSigTimeoutTime" BU_SG_REL_ DACU SG_ 2566803211 YCEngineControlActive_ISig_3 600;
BA_REL_ "GenSigFirstTimeoutTime" BU_SG_REL_ VMCU SG_ 2566803211 YCEngineControlActive_ISig_3 3000;
BA_REL_ "GenSigTimeoutTime" BU_SG_REL_ VMCU SG_ 2566803211 YCEngineControlActive_ISig_3 600;
BA_REL_ "GenSigFirstTimeoutTime" BU_SG_REL_ TECU SG_ 2566803211 YCEngineControlActive_ISig_3 3000;
BA_REL_ "GenSigTimeoutTime" BU_SG_REL_ TECU SG_ 2566803211 YCEngineControlActive_ISig_3 600;
BA_REL_ "GenSigFirstTimeoutTime" BU_SG_REL_ TECU SG_ 2566803211 ROPBrakeControlActive_ISig_3 3000;
BA_REL_ "GenSigTimeoutTime" BU_SG_REL_ TECU SG_ 2566803211 ROPBrakeControlActive_ISig_3 600;
BA_REL_ "GenSigFirstTimeoutTime" BU_SG_REL_ VMCU SG_ 2566803211 ROPBrakeControlActive_ISig_3 3000;
BA_REL_ "GenSigTimeoutTime" BU_SG_REL_ VMCU SG_ 2566803211 ROPBrakeControlActive_ISig_3 600;
BA_REL_ "GenSigFirstTimeoutTime" BU_SG_REL_ CIOM SG_ 2566803211 ROPBrakeControlActive_ISig_3 3000;
BA_REL_ "GenSigTimeoutTime" BU_SG_REL_ CIOM SG_ 2566803211 ROPBrakeControlActive_ISig_3 600;
BA_REL_ "GenSigFirstTimeoutTime" BU_SG_REL_ DACU SG_ 2566803211 ROPBrakeControlActive_ISig_3 3000;
BA_REL_ "GenSigTimeoutTime" BU_SG_REL_ DACU SG_ 2566803211 ROPBrakeControlActive_ISig_3 600;
BA_REL_ "GenSigFirstTimeoutTime" BU_SG_REL_ HMIIOM SG_ 2566803211 ROPBrakeControlActive_ISig_3 3000;
BA_REL_ "GenSigTimeoutTime" BU_SG_REL_ HMIIOM SG_ 2566803211 ROPBrakeControlActive_ISig_3 600;
BA_REL_ "GenSigFirstTimeoutTime" BU_SG_REL_ HMIIOM SG_ 2566803211 YCBrakeControlActive_ISig_3 3000;
BA_REL_ "GenSigTimeoutTime" BU_SG_REL_ HMIIOM SG_ 2566803211 YCBrakeControlActive_ISig_3 600;
BA_REL_ "GenSigFirstTimeoutTime" BU_SG_REL_ DACU SG_ 2566803211 YCBrakeControlActive_ISig_3 3000;
BA_REL_ "GenSigTimeoutTime" BU_SG_REL_ DACU SG_ 2566803211 YCBrakeControlActive_ISig_3 600;
BA_REL_ "GenSigFirstTimeoutTime" BU_SG_REL_ TECU SG_ 2566803211 YCBrakeControlActive_ISig_3 3000;
BA_REL_ "GenSigTimeoutTime" BU_SG_REL_ TECU SG_ 2566803211 YCBrakeControlActive_ISig_3 600;
BA_REL_ "GenSigFirstTimeoutTime" BU_SG_REL_ VMCU SG_ 2566803211 YCBrakeControlActive_ISig_3 3000;
BA_REL_ "GenSigTimeoutTime" BU_SG_REL_ VMCU SG_ 2566803211 YCBrakeControlActive_ISig_3 600;
BA_REL_ "GenSigFirstTimeoutTime" BU_SG_REL_ CIOM SG_ 2566803211 YCBrakeControlActive_ISig_3 3000;
BA_REL_ "GenSigTimeoutTime" BU_SG_REL_ CIOM SG_ 2566803211 YCBrakeControlActive_ISig_3 600;
BA_REL_ "GenSigFirstTimeoutTime" BU_SG_REL_ DACU SG_ 2566803211 VDCFullyOperational 3000;
BA_REL_ "GenSigTimeoutTime" BU_SG_REL_ DACU SG_ 2566803211 VDCFullyOperational 600;
BA_REL_ "GenSigFirstTimeoutTime" BU_SG_REL_ HMIIOM SG_ 2566803211 VDCFullyOperational 3000;
BA_REL_ "GenSigTimeoutTime" BU_SG_REL_ HMIIOM SG_ 2566803211 VDCFullyOperational 600;
BA_REL_ "GenSigFirstTimeoutTime" BU_SG_REL_ RECU_Virt SG_ 2348814353 TSC1RECUVMCU_EnRSpdSpdLm 3000;
BA_REL_ "GenSigTimeoutTime" BU_SG_REL_ RECU_Virt SG_ 2348814353 TSC1RECUVMCU_EnRSpdSpdLm 300;
BA_REL_ "GenSigFirstTimeoutTime" BU_SG_REL_ EBS SG_ 2348814353 TSC1RECUVMCU_EnRSpdSpdLm 3000;
BA_REL_ "GenSigTimeoutTime" BU_SG_REL_ EBS SG_ 2348814353 TSC1RECUVMCU_EnRSpdSpdLm 300;
BA_REL_ "GenSigFirstTimeoutTime" BU_SG_REL_ EBS SG_ 2348814353 TSC1RECUVMCU_EnOvrdCtrlM 3000;
BA_REL_ "GenSigTimeoutTime" BU_SG_REL_ EBS SG_ 2348814353 TSC1RECUVMCU_EnOvrdCtrlM 300;
BA_REL_ "GenSigFirstTimeoutTime" BU_SG_REL_ RECU_Virt SG_ 2348814353 TSC1RECUVMCU_EnOvrdCtrlM 3000;
BA_REL_ "GenSigTimeoutTime" BU_SG_REL_ RECU_Virt SG_ 2348814353 TSC1RECUVMCU_EnOvrdCtrlM 300;
BA_REL_ "GenSigFirstTimeoutTime" BU_SG_REL_ RECU_Virt SG_ 2348814353 TSC1RECUVMCU_EnRTrqTrqLm 3000;
BA_REL_ "GenSigTimeoutTime" BU_SG_REL_ RECU_Virt SG_ 2348814353 TSC1RECUVMCU_EnRTrqTrqLm 300;
BA_REL_ "GenSigFirstTimeoutTime" BU_SG_REL_ EBS SG_ 2348814353 TSC1RECUVMCU_EnRTrqTrqLm 3000;
BA_REL_ "GenSigTimeoutTime" BU_SG_REL_ EBS SG_ 2348814353 TSC1RECUVMCU_EnRTrqTrqLm 300;
BA_REL_ "GenSigFirstTimeoutTime" BU_SG_REL_ RECU_Virt SG_ 2348814353 TSC1RECUVMCU_EnRSpdCtrlC 3000;
BA_REL_ "GenSigTimeoutTime" BU_SG_REL_ RECU_Virt SG_ 2348814353 TSC1RECUVMCU_EnRSpdCtrlC 300;
BA_REL_ "GenSigFirstTimeoutTime" BU_SG_REL_ EBS SG_ 2348814353 TSC1RECUVMCU_EnRSpdCtrlC 3000;
BA_REL_ "GenSigTimeoutTime" BU_SG_REL_ EBS SG_ 2348814353 TSC1RECUVMCU_EnRSpdCtrlC 300;
BA_REL_ "GenSigFirstTimeoutTime" BU_SG_REL_ EBS SG_ 2348814353 TSC1RECUVMCU_OvrdCtrlMPr 3000;
BA_REL_ "GenSigTimeoutTime" BU_SG_REL_ EBS SG_ 2348814353 TSC1RECUVMCU_OvrdCtrlMPr 300;
BA_REL_ "GenSigFirstTimeoutTime" BU_SG_REL_ RECU_Virt SG_ 2348814353 TSC1RECUVMCU_OvrdCtrlMPr 3000;
BA_REL_ "GenSigTimeoutTime" BU_SG_REL_ RECU_Virt SG_ 2348814353 TSC1RECUVMCU_OvrdCtrlMPr 300;
BA_REL_ "GenSigFirstTimeoutTime" BU_SG_REL_ RECU_Virt SG_ 2348814339 TSC1RECUTECU_EnRTrqTrqLm 3000;
BA_REL_ "GenSigTimeoutTime" BU_SG_REL_ RECU_Virt SG_ 2348814339 TSC1RECUTECU_EnRTrqTrqLm 300;
BA_REL_ "GenSigFirstTimeoutTime" BU_SG_REL_ RECU_Virt SG_ 2348814339 TSC1RECUTECU_EnOvrdCtrlM 3000;
BA_REL_ "GenSigTimeoutTime" BU_SG_REL_ RECU_Virt SG_ 2348814339 TSC1RECUTECU_EnOvrdCtrlM 300;
BA_REL_ "GenSigFirstTimeoutTime" BU_SG_REL_ RECU_Virt SG_ 2348814339 TSC1RECUTECU_OvrdCtrlMPr 3000;
BA_REL_ "GenSigTimeoutTime" BU_SG_REL_ RECU_Virt SG_ 2348814339 TSC1RECUTECU_OvrdCtrlMPr 300;
BA_REL_ "GenSigFirstTimeoutTime" BU_SG_REL_ RECU_Virt SG_ 2348814339 TSC1RECUTECU_EnRSpdCtrlC 3000;
BA_REL_ "GenSigTimeoutTime" BU_SG_REL_ RECU_Virt SG_ 2348814339 TSC1RECUTECU_EnRSpdCtrlC 300;
BA_REL_ "GenSigFirstTimeoutTime" BU_SG_REL_ RECU_Virt SG_ 2348814339 TSC1RECUTECU_EnRSpdSpdLm 3000;
BA_REL_ "GenSigTimeoutTime" BU_SG_REL_ RECU_Virt SG_ 2348814339 TSC1RECUTECU_EnRSpdSpdLm 300;
BA_REL_ "GenSigFirstTimeoutTime" BU_SG_REL_ RECU_Virt SG_ 2348814337 TSC1RECUEMSdap_EnRSpdSpdLm 3000;
BA_REL_ "GenSigTimeoutTime" BU_SG_REL_ RECU_Virt SG_ 2348814337 TSC1RECUEMSdap_EnRSpdSpdLm 300;
BA_REL_ "GenSigFirstTimeoutTime" BU_SG_REL_ RECU_Virt SG_ 2348814337 TSC1RECUEMSdap_OvrdCtrlMPr 3000;
BA_REL_ "GenSigTimeoutTime" BU_SG_REL_ RECU_Virt SG_ 2348814337 TSC1RECUEMSdap_OvrdCtrlMPr 300;
BA_REL_ "GenSigFirstTimeoutTime" BU_SG_REL_ RECU_Virt SG_ 2348814337 TSC1RECUEMSdap_EnOvrdCtrlM 3000;
BA_REL_ "GenSigTimeoutTime" BU_SG_REL_ RECU_Virt SG_ 2348814337 TSC1RECUEMSdap_EnOvrdCtrlM 300;
BA_REL_ "GenSigFirstTimeoutTime" BU_SG_REL_ RECU_Virt SG_ 2348814337 TSC1RECUEMSdap_EnRSpdCtrlC 3000;
BA_REL_ "GenSigTimeoutTime" BU_SG_REL_ RECU_Virt SG_ 2348814337 TSC1RECUEMSdap_EnRSpdCtrlC 300;
BA_REL_ "GenSigFirstTimeoutTime" BU_SG_REL_ RECU_Virt SG_ 2348814337 TSC1RECUEMSdap_EnRTrqTrqLm 3000;
BA_REL_ "GenSigTimeoutTime" BU_SG_REL_ RECU_Virt SG_ 2348814337 TSC1RECUEMSdap_EnRTrqTrqLm 300;
BA_REL_ "GenSigFirstTimeoutTime" BU_SG_REL_ RECU_Virt SG_ 2348814336 TSC1RECUEMSccb_EnRSpdSpdLm 3000;
BA_REL_ "GenSigTimeoutTime" BU_SG_REL_ RECU_Virt SG_ 2348814336 TSC1RECUEMSccb_EnRSpdSpdLm 300;
BA_REL_ "GenSigFirstTimeoutTime" BU_SG_REL_ RECU_Virt SG_ 2348814336 TSC1RECUEMSccb_EnRSpdCtrlC 3000;
BA_REL_ "GenSigTimeoutTime" BU_SG_REL_ RECU_Virt SG_ 2348814336 TSC1RECUEMSccb_EnRSpdCtrlC 300;
BA_REL_ "GenSigFirstTimeoutTime" BU_SG_REL_ RECU_Virt SG_ 2348814336 TSC1RECUEMSccb_EnOvrdCtrlM 3000;
BA_REL_ "GenSigTimeoutTime" BU_SG_REL_ RECU_Virt SG_ 2348814336 TSC1RECUEMSccb_EnOvrdCtrlM 300;
BA_REL_ "GenSigFirstTimeoutTime" BU_SG_REL_ RECU_Virt SG_ 2348814336 TSC1RECUEMSccb_OvrdCtrlMPr 3000;
BA_REL_ "GenSigTimeoutTime" BU_SG_REL_ RECU_Virt SG_ 2348814336 TSC1RECUEMSccb_OvrdCtrlMPr 300;
BA_REL_ "GenSigFirstTimeoutTime" BU_SG_REL_ RECU_Virt SG_ 2348814336 TSC1RECUEMSccb_EnRTrqTrqLm 3000;
BA_REL_ "GenSigTimeoutTime" BU_SG_REL_ RECU_Virt SG_ 2348814336 TSC1RECUEMSccb_EnRTrqTrqLm 300;
BA_REL_ "GenSigFirstTimeoutTime" BU_SG_REL_ RECU_Virt SG_ 2348814347 TSC1RECUABS_EnOvrdCtrlM 3000;
BA_REL_ "GenSigTimeoutTime" BU_SG_REL_ RECU_Virt SG_ 2348814347 TSC1RECUABS_EnOvrdCtrlM 300;
BA_REL_ "GenSigFirstTimeoutTime" BU_SG_REL_ RECU_Virt SG_ 2348814347 TSC1RECUABS_EnRTrqTrqLm 3000;
BA_REL_ "GenSigTimeoutTime" BU_SG_REL_ RECU_Virt SG_ 2348814347 TSC1RECUABS_EnRTrqTrqLm 300;
BA_REL_ "GenSigFirstTimeoutTime" BU_SG_REL_ RECU_Virt SG_ 2348814347 TSC1RECUABS_EnRSpdSpdLm 3000;
BA_REL_ "GenSigTimeoutTime" BU_SG_REL_ RECU_Virt SG_ 2348814347 TSC1RECUABS_EnRSpdSpdLm 300;
BA_REL_ "GenSigFirstTimeoutTime" BU_SG_REL_ RECU_Virt SG_ 2348814347 TSC1RECUABS_OvrdCtrlMPr 3000;
BA_REL_ "GenSigTimeoutTime" BU_SG_REL_ RECU_Virt SG_ 2348814347 TSC1RECUABS_OvrdCtrlMPr 300;
BA_REL_ "GenSigFirstTimeoutTime" BU_SG_REL_ RECU_Virt SG_ 2348814347 TSC1RECUABS_EnRSpdCtrlC 3000;
BA_REL_ "GenSigTimeoutTime" BU_SG_REL_ RECU_Virt SG_ 2348814347 TSC1RECUABS_EnRSpdCtrlC 300;
BA_REL_ "GenSigFirstTimeoutTime" BU_SG_REL_ EMS SG_ 2348810257 TSC1EMSVMCUtr_EnOvrdCtrlM 3000;
BA_REL_ "GenSigTimeoutTime" BU_SG_REL_ EMS SG_ 2348810257 TSC1EMSVMCUtr_EnOvrdCtrlM 120;
BA_REL_ "GenSigFirstTimeoutTime" BU_SG_REL_ EMS SG_ 2348810257 TSC1EMSVMCUtr_EnRSpdCtrlC 3000;
BA_REL_ "GenSigTimeoutTime" BU_SG_REL_ EMS SG_ 2348810257 TSC1EMSVMCUtr_EnRSpdCtrlC 120;
BA_REL_ "GenSigFirstTimeoutTime" BU_SG_REL_ EMS SG_ 2348810257 TSC1EMSVMCUtr_OvrdCtrlMPr 3000;
BA_REL_ "GenSigTimeoutTime" BU_SG_REL_ EMS SG_ 2348810257 TSC1EMSVMCUtr_OvrdCtrlMPr 120;
BA_REL_ "GenSigFirstTimeoutTime" BU_SG_REL_ EMS SG_ 2348810257 TSC1EMSVMCUtr_EnRSpdSpdLm 3000;
BA_REL_ "GenSigTimeoutTime" BU_SG_REL_ EMS SG_ 2348810257 TSC1EMSVMCUtr_EnRSpdSpdLm 120;
BA_REL_ "GenSigFirstTimeoutTime" BU_SG_REL_ EMS SG_ 2348810257 TSC1EMSVMCUtr_EnRTrqTrqLm 3000;
BA_REL_ "GenSigTimeoutTime" BU_SG_REL_ EMS SG_ 2348810257 TSC1EMSVMCUtr_EnRTrqTrqLm 120;
BA_REL_ "GenSigFirstTimeoutTime" BU_SG_REL_ EMS SG_ 2348810288 TSC1EMSVMCUes_OvrdCtrlMPr 3000;
BA_REL_ "GenSigTimeoutTime" BU_SG_REL_ EMS SG_ 2348810288 TSC1EMSVMCUes_OvrdCtrlMPr 120;
BA_REL_ "GenSigFirstTimeoutTime" BU_SG_REL_ TECU SG_ 2348810288 TSC1EMSVMCUes_OvrdCtrlMPr 3000;
BA_REL_ "GenSigTimeoutTime" BU_SG_REL_ TECU SG_ 2348810288 TSC1EMSVMCUes_OvrdCtrlMPr 120;
BA_REL_ "GenSigFirstTimeoutTime" BU_SG_REL_ TECU SG_ 2348810288 TSC1EMSVMCUes_EnRTrqTrqLm 3000;
BA_REL_ "GenSigTimeoutTime" BU_SG_REL_ TECU SG_ 2348810288 TSC1EMSVMCUes_EnRTrqTrqLm 120;
BA_REL_ "GenSigFirstTimeoutTime" BU_SG_REL_ EMS SG_ 2348810288 TSC1EMSVMCUes_EnRTrqTrqLm 3000;
BA_REL_ "GenSigTimeoutTime" BU_SG_REL_ EMS SG_ 2348810288 TSC1EMSVMCUes_EnRTrqTrqLm 120;
BA_REL_ "GenSigFirstTimeoutTime" BU_SG_REL_ TECU SG_ 2348810288 TSC1EMSVMCUes_EnOvrdCtrlM 3000;
BA_REL_ "GenSigTimeoutTime" BU_SG_REL_ TECU SG_ 2348810288 TSC1EMSVMCUes_EnOvrdCtrlM 120;
BA_REL_ "GenSigFirstTimeoutTime" BU_SG_REL_ EMS SG_ 2348810288 TSC1EMSVMCUes_EnOvrdCtrlM 3000;
BA_REL_ "GenSigTimeoutTime" BU_SG_REL_ EMS SG_ 2348810288 TSC1EMSVMCUes_EnOvrdCtrlM 120;
BA_REL_ "GenSigFirstTimeoutTime" BU_SG_REL_ TECU SG_ 2348810288 TSC1EMSVMCUes_EnRSpdSpdLm 3000;
BA_REL_ "GenSigTimeoutTime" BU_SG_REL_ TECU SG_ 2348810288 TSC1EMSVMCUes_EnRSpdSpdLm 120;
BA_REL_ "GenSigFirstTimeoutTime" BU_SG_REL_ EMS SG_ 2348810288 TSC1EMSVMCUes_EnRSpdSpdLm 3000;
BA_REL_ "GenSigTimeoutTime" BU_SG_REL_ EMS SG_ 2348810288 TSC1EMSVMCUes_EnRSpdSpdLm 120;
BA_REL_ "GenSigFirstTimeoutTime" BU_SG_REL_ EMS SG_ 2348810288 TSC1EMSVMCUes_EnRSpdCtrlC 3000;
BA_REL_ "GenSigTimeoutTime" BU_SG_REL_ EMS SG_ 2348810288 TSC1EMSVMCUes_EnRSpdCtrlC 120;
BA_REL_ "GenSigFirstTimeoutTime" BU_SG_REL_ TECU SG_ 2348810288 TSC1EMSVMCUes_EnRSpdCtrlC 3000;
BA_REL_ "GenSigTimeoutTime" BU_SG_REL_ TECU SG_ 2348810288 TSC1EMSVMCUes_EnRSpdCtrlC 120;
BA_REL_ "GenSigFirstTimeoutTime" BU_SG_REL_ EMS SG_ 2348810243 TSC1EMSTECU_EnRSpdSpdLm 3000;
BA_REL_ "GenSigTimeoutTime" BU_SG_REL_ EMS SG_ 2348810243 TSC1EMSTECU_EnRSpdSpdLm 60;
BA_REL_ "GenSigFirstTimeoutTime" BU_SG_REL_ EMS SG_ 2348810243 TSC1EMSTECU_EnOvrdCtrlM 3000;
BA_REL_ "GenSigTimeoutTime" BU_SG_REL_ EMS SG_ 2348810243 TSC1EMSTECU_EnOvrdCtrlM 60;
BA_REL_ "GenSigFirstTimeoutTime" BU_SG_REL_ EMS SG_ 2348810243 TSC1EMSTECU_OvrdCtrlMPr 3000;
BA_REL_ "GenSigTimeoutTime" BU_SG_REL_ EMS SG_ 2348810243 TSC1EMSTECU_OvrdCtrlMPr 60;
BA_REL_ "GenSigFirstTimeoutTime" BU_SG_REL_ EMS SG_ 2348810243 TSC1EMSTECU_EnRSpdCtrlC 3000;
BA_REL_ "GenSigTimeoutTime" BU_SG_REL_ EMS SG_ 2348810243 TSC1EMSTECU_EnRSpdCtrlC 60;
BA_REL_ "GenSigFirstTimeoutTime" BU_SG_REL_ EMS SG_ 2348810243 TSC1EMSTECU_EnRTrqTrqLm 3000;
BA_REL_ "GenSigTimeoutTime" BU_SG_REL_ EMS SG_ 2348810243 TSC1EMSTECU_EnRTrqTrqLm 60;
BA_REL_ "GenSigFirstTimeoutTime" BU_SG_REL_ EMS SG_ 2348810251 TSC1EMSABS_EnRTrqTrqLm 3000;
BA_REL_ "GenSigTimeoutTime" BU_SG_REL_ EMS SG_ 2348810251 TSC1EMSABS_EnRTrqTrqLm 60;
BA_REL_ "GenSigFirstTimeoutTime" BU_SG_REL_ EMS SG_ 2348810251 TSC1EMSABS_EnRSpdCtrlC 3000;
BA_REL_ "GenSigTimeoutTime" BU_SG_REL_ EMS SG_ 2348810251 TSC1EMSABS_EnRSpdCtrlC 60;
BA_REL_ "GenSigFirstTimeoutTime" BU_SG_REL_ EMS SG_ 2348810251 TSC1EMSABS_OvrdCtrlMPr 3000;
BA_REL_ "GenSigTimeoutTime" BU_SG_REL_ EMS SG_ 2348810251 TSC1EMSABS_OvrdCtrlMPr 60;
BA_REL_ "GenSigFirstTimeoutTime" BU_SG_REL_ EMS SG_ 2348810251 TSC1EMSABS_EnOvrdCtrlM 3000;
BA_REL_ "GenSigTimeoutTime" BU_SG_REL_ EMS SG_ 2348810251 TSC1EMSABS_EnOvrdCtrlM 60;
BA_REL_ "GenSigFirstTimeoutTime" BU_SG_REL_ EMS SG_ 2348810251 TSC1EMSABS_EnRSpdSpdLm 3000;
BA_REL_ "GenSigTimeoutTime" BU_SG_REL_ EMS SG_ 2348810251 TSC1EMSABS_EnRSpdSpdLm 60;
BA_REL_ "GenSigFirstTimeoutTime" BU_SG_REL_ EMS SG_ 2348810413 TSC1EMSDACU_OvrdCtrlMPr 3000;
BA_REL_ "GenSigTimeoutTime" BU_SG_REL_ EMS SG_ 2348810413 TSC1EMSDACU_OvrdCtrlMPr 120;
BA_REL_ "GenSigFirstTimeoutTime" BU_SG_REL_ EMS SG_ 2348810413 TSC1EMSDACU_EnRSpdSpdLm 3000;
BA_REL_ "GenSigTimeoutTime" BU_SG_REL_ EMS SG_ 2348810413 TSC1EMSDACU_EnRSpdSpdLm 120;
BA_REL_ "GenSigFirstTimeoutTime" BU_SG_REL_ EMS SG_ 2348810413 TSC1EMSDACU_EnRSpdCtrlC 3000;
BA_REL_ "GenSigTimeoutTime" BU_SG_REL_ EMS SG_ 2348810413 TSC1EMSDACU_EnRSpdCtrlC 120;
BA_REL_ "GenSigFirstTimeoutTime" BU_SG_REL_ EMS SG_ 2348810413 TSC1EMSDACU_EnRTrqTrqLm 3000;
BA_REL_ "GenSigTimeoutTime" BU_SG_REL_ EMS SG_ 2348810413 TSC1EMSDACU_EnRTrqTrqLm 120;
BA_REL_ "GenSigFirstTimeoutTime" BU_SG_REL_ EMS SG_ 2348810413 TSC1EMSDACU_EnOvrdCtrlM 3000;
BA_REL_ "GenSigTimeoutTime" BU_SG_REL_ EMS SG_ 2348810413 TSC1EMSDACU_EnOvrdCtrlM 120;
VAL_ 2349075203 XBRTECU_Priority 3 "Priority_LowPriority" 2 "Priority_MediumPriority" 1 "Priority_HighPriority" 0 "Priority_HighestPriority" ;
VAL_ 2349075203 XBRTECU_EBIMode 3 "XBREBIMode_NotDefined" 2 "XBREBIMode_EnduranceBrakeIntegrationAllowed" 1 "XBREBIMode_OnlyEnduranceBrakesAllowed" 0 "XBREBIMode_NoEnduranceBrakeIntegrationAllowed" ;
VAL_ 2349075203 XBRTECU_ControlMode 3 "XBRControlMode_NotDefined" 2 "XBRControlMode_AccelerationControlWithMaximumMode" 1 "XBRControlMode_AccelerationControlWithAdditionMode" 0 "XBRControlMode_OverrideDisabled" ;
VAL_ 2349075200 XBREMS_ControlMode 3 "XBRControlMode_NotDefined" 2 "XBRControlMode_AccelerationControlWithMaximumMode" 1 "XBRControlMode_AccelerationControlWithAdditionMode" 0 "XBRControlMode_OverrideDisabled" ;
VAL_ 2349075200 XBREMS_EBIMode 3 "XBREBIMode_NotDefined" 2 "XBREBIMode_EnduranceBrakeIntegrationAllowed" 1 "XBREBIMode_OnlyEnduranceBrakesAllowed" 0 "XBREBIMode_NoEnduranceBrakeIntegrationAllowed" ;
VAL_ 2349075200 XBREMS_Priority 3 "Priority_LowPriority" 2 "Priority_MediumPriority" 1 "Priority_HighPriority" 0 "Priority_HighestPriority" ;
VAL_ 2349075373 XBRDACU_EBIMode 3 "XBREBIMode_NotDefined" 2 "XBREBIMode_EnduranceBrakeIntegrationAllowed" 1 "XBREBIMode_OnlyEnduranceBrakesAllowed" 0 "XBREBIMode_NoEnduranceBrakeIntegrationAllowed" ;
VAL_ 2349075373 XBRDACU_ControlMode 3 "XBRControlMode_NotDefined" 2 "XBRControlMode_AccelerationControlWithMaximumMode" 1 "XBRControlMode_AccelerationControlWithAdditionMode" 0 "XBRControlMode_OverrideDisabled" ;
VAL_ 2349075373 XBRDACU_Priority 3 "Priority_LowPriority" 2 "Priority_MediumPriority" 1 "Priority_HighPriority" 0 "Priority_HighestPriority" ;
VAL_ 2349075430 XBRBBM_ControlMode 3 "XBRControlMode_NotDefined" 2 "XBRControlMode_AccelerationControlWithMaximumMode" 1 "XBRControlMode_AccelerationControlWithAdditionMode" 0 "XBRControlMode_OverrideDisabled" ;
VAL_ 2349075430 XBRBBM_Priority 3 "Priority_LowPriority" 2 "Priority_MediumPriority" 1 "Priority_HighPriority" 0 "Priority_HighestPriority" ;
VAL_ 2349075430 XBRBBM_EBIMode 3 "XBREBIMode_NotDefined" 2 "XBREBIMode_EnduranceBrakeIntegrationAllowed" 1 "XBREBIMode_OnlyEnduranceBrakesAllowed" 0 "XBREBIMode_NoEnduranceBrakeIntegrationAllowed" ;
VAL_ 2566848256 WaterInFuelAlarm_ISig_3 3 "NoYes_NotAvailable" 2 "NoYes_Error" 1 "NoYes_Yes" 0 "NoYes_No" ;
VAL_ 2499751697 RearAxle2DiffLock_stat_ISig_3 3 "OffOn_NotAvailable" 2 "OffOn_Error" 1 "OffOn_On" 0 "OffOn_Off" ;
VAL_ 2499751697 EngineStopReqBackup 3 "Request_NotAvailable" 2 "Request_Error" 1 "Request_RequestActive" 0 "Request_NotRequested" ;
VAL_ 2499751697 DifferentialLockStateCentral_ISi 3 "DisengageEngage_NotAvailable" 2 "DisengageEngage_Error" 1 "DisengageEngage_Engage" 0 "DisengageEngage_Disengage" ;
VAL_ 2499751697 RearPropulsionStat_Rear1Axle_ISi 15 "AxlePropulsionStatus_NotAvailable" 14 "AxlePropulsionStatus_Error" 13 "AxlePropulsionStatus_Spare6" 12 "AxlePropulsionStatus_Spare5" 11 "AxlePropulsionStatus_Spare4" 10 "AxlePropulsionStatus_Spare3" 9 "AxlePropulsionStatus_Spare2" 8 "AxlePropulsionStatus_Spare1" 7 "AxlePropulsionStatus_LoweredInterAxleStatusUnknown" 6 "AxlePropulsionStatus_LiftedInterAxleStatusUnknown" 5 "AxlePropulsionStatus_PositionUnknownDriven" 4 "AxlePropulsionStatus_PositionUnknownNonDriven" 3 "AxlePropulsionStatus_LoweredDifferentialLocked" 2 "AxlePropulsionStatus_LoweredDriven" 1 "AxlePropulsionStatus_LoweredNonDriven" 0 "AxlePropulsionStatus_LiftedNonDriven" ;
VAL_ 2499751697 DifferentialLockStateCentral2 3 "DisengagedEngaged_NotAvailable" 2 "DisengagedEngaged_Error" 1 "DisengagedEngaged_Engaged" 0 "DisengagedEngaged_Disengaged" ;
VAL_ 2499751697 SetHSAOperation_ISig_3 7 "SetHSAOperation_NotAvailable" 6 "SetHSAOperation_Error" 5 "SetHSAOperation_Spare2" 4 "SetHSAOperation_Spare1" 3 "SetHSAOperation_Forbid_HSA_WithCaution" 2 "SetHSAOperation_Forbid_HSA_Activation" 1 "SetHSAOperation_Allow_HSA_WithCaution" 0 "SetHSAOperation_Allow_HSA_Activation" ;
VAL_ 2499751697 CentralRearDiffLock_stat_ISig_3 3 "DisengageEngage_NotAvailable" 2 "DisengageEngage_Error" 1 "DisengageEngage_Engage" 0 "DisengageEngage_Disengage" ;
VAL_ 2499751697 LowAirPressureAlert_ISig_3 3 "LowAirPressureAlert_NotAvailable" 2 "LowAirPressureAlert_Error" 1 "LowAirPressureAlert_LowPressure" 0 "LowAirPressureAlert_NormalPressure" ;
VAL_ 2499751697 RearPropulsionStat_Rear3Axle_ISi 15 "AxlePropulsionStatus_NotAvailable" 14 "AxlePropulsionStatus_Error" 13 "AxlePropulsionStatus_Spare6" 12 "AxlePropulsionStatus_Spare5" 11 "AxlePropulsionStatus_Spare4" 10 "AxlePropulsionStatus_Spare3" 9 "AxlePropulsionStatus_Spare2" 8 "AxlePropulsionStatus_Spare1" 7 "AxlePropulsionStatus_LoweredInterAxleStatusUnknown" 6 "AxlePropulsionStatus_LiftedInterAxleStatusUnknown" 5 "AxlePropulsionStatus_PositionUnknownDriven" 4 "AxlePropulsionStatus_PositionUnknownNonDriven" 3 "AxlePropulsionStatus_LoweredDifferentialLocked" 2 "AxlePropulsionStatus_LoweredDriven" 1 "AxlePropulsionStatus_LoweredNonDriven" 0 "AxlePropulsionStatus_LiftedNonDriven" ;
VAL_ 2499751697 DifferentialLockStateFrAxle2 3 "DisengagedEngaged_NotAvailable" 2 "DisengagedEngaged_Error" 1 "DisengagedEngaged_Engaged" 0 "DisengagedEngaged_Disengaged" ;
VAL_ 2499751697 TrailerConnected_ISig_3 3 "NoYes_NotAvailable" 2 "NoYes_Error" 1 "NoYes_Yes" 0 "NoYes_No" ;
VAL_ 2499751697 TrailerWithoutABS_ISig_3 3 "TrailerWithoutABS_NotAvailableOrNotInstalled" 2 "TrailerWithoutABS_ErrorIndicator" 1 "TrailerWithoutABS_YesTrailerWithoutABS" 0 "TrailerWithoutABS_NoNoTrailerPresentOraTrailerWithABS" ;
VAL_ 2499751697 DifferentialLockStateFrAxle1_ISi 3 "DisengageEngage_NotAvailable" 2 "DisengageEngage_Error" 1 "DisengageEngage_Engage" 0 "DisengageEngage_Disengage" ;
VAL_ 2499751697 RearPropulsionStat_Rear2Axle_ISi 15 "AxlePropulsionStatus_NotAvailable" 14 "AxlePropulsionStatus_Error" 13 "AxlePropulsionStatus_Spare6" 12 "AxlePropulsionStatus_Spare5" 11 "AxlePropulsionStatus_Spare4" 10 "AxlePropulsionStatus_Spare3" 9 "AxlePropulsionStatus_Spare2" 8 "AxlePropulsionStatus_Spare1" 7 "AxlePropulsionStatus_LoweredInterAxleStatusUnknown" 6 "AxlePropulsionStatus_LiftedInterAxleStatusUnknown" 5 "AxlePropulsionStatus_PositionUnknownDriven" 4 "AxlePropulsionStatus_PositionUnknownNonDriven" 3 "AxlePropulsionStatus_LoweredDifferentialLocked" 2 "AxlePropulsionStatus_LoweredDriven" 1 "AxlePropulsionStatus_LoweredNonDriven" 0 "AxlePropulsionStatus_LiftedNonDriven" ;
VAL_ 2499751697 RearAxle1DiffLock_stat_ISig_3 3 "OffOn_NotAvailable" 2 "OffOn_Error" 1 "OffOn_On" 0 "OffOn_Off" ;
VAL_ 2566897425 StretchBrakeEnable_rqst 7 "StretchBrakeEnable_rqst_NotAvailable" 6 "StretchBrakeEnable_rqst_Error" 5 "StretchBrakeEnable_rqst_Spare_2" 4 "StretchBrakeEnable_rqst_Spare_1" 3 "StretchBrakeEnable_rqst_Enable_PulseLevel3" 2 "StretchBrakeEnable_rqst_Enable_PulseLevel2" 1 "StretchBrakeEnable_rqst_Enable_PulseLevel1" 0 "StretchBrakeEnable_rqst_Disabled" ;
VAL_ 2566897425 StaticTrailerBrake_rqst 3 "DeactivateActivate_NotAvailable" 2 "DeactivateActivate_Error" 1 "DeactivateActivate_Activate" 0 "DeactivateActivate_Deactivate" ;
VAL_ 2298429457 SWBrakeSwitch_ISig_3 3 "BrakeSwitch_NotAvailable" 2 "BrakeSwitch_Error" 1 "BrakeSwitch_BrakePedalDepressed" 0 "BrakeSwitch_BrakePedalReleased" ;
VAL_ 2298429457 VehicleMode_ISig_3 15 "VehicleMode_NotAvailable" 14 "VehicleMode_Error" 13 "VehicleMode_Spare_7" 12 "VehicleMode_Spare_6" 11 "VehicleMode_Spare_5" 10 "VehicleMode_Spare_4" 9 "VehicleMode_Spare_3" 8 "VehicleMode_Spare_2" 7 "VehicleMode_Spare_1" 6 "VehicleMode_Running" 5 "VehicleMode_Cranking" 4 "VehicleMode_PreRunning" 3 "VehicleMode_Accessory" 2 "VehicleMode_Living" 1 "VehicleMode_Parked" 0 "VehicleMode_Hibernate" ;
VAL_ 2298429457 AcctrPedalKickDownSw_stat_ISig_3 3 "PassiveActive_NotAvailable" 2 "PassiveActive_Error" 1 "PassiveActive_Active" 0 "PassiveActive_Passive" ;
VAL_ 2298429457 AcceleratorPedalLowIdleSwitch_IS 3 "AcceleratorPedalLowIdleSwitch_NotAvailable" 2 "AcceleratorPedalLowIdleSwitch_Error" 1 "AcceleratorPedalLowIdleSwitch_INLowIdleCondition" 0 "AcceleratorPedalLowIdleSwitch_NotInLowIdleCondition" ;
VAL_ 2566906094 SingleMultiDriver_ISig_3 3 "SingleMultiDriver_NotAvailable" 2 "SingleMultiDriver_Error" 1 "SingleMultiDriver_MultiManningForCurrentShiftDetected" 0 "SingleMultiDriver_SingleDriverForCurrentShiftDetected" ;
VAL_ 2566906094 UnknownPeriods_ISig_3 3 "UnknownPeriods_NotAvailable" 2 "UnknownPeriods_Error" 1 "UnknownPeriods_AtLeastOneUnknownPeriod" 0 "UnknownPeriods_NoUNKNOWNPeriods" ;
VAL_ 2566906094 RemainingReducedDailyRestPrd_ISi 7 "RemainingReducedDailyRestPrd_NotAvailable" 6 "RemainingReducedDailyRestPrd_Error" 5 "RemainingReducedDailyRestPrd_Spare_02" 4 "RemainingReducedDailyRestPrd_Spare_01" 3 "RemainingReducedDailyRestPrd_3RemainingReducedDailyRestPeriods" 2 "RemainingReducedDailyRestPrd_2RemainingReducedDailyRestPeriods" 1 "RemainingReducedDailyRestPrd_1RemainingReducedDailyRestPeriods" 0 "RemainingReducedDailyRestPrd_0RemainingReducedDailyRestPeriods" ;
VAL_ 2566906094 TimeOverlap_ISig_3 3 "TimeOverlap_NotAvailable" 2 "TimeOverlap_Error" 1 "TimeOverlap_TimeOverlapDetected" 0 "TimeOverlap_NoTimeOverlapInTheDataSet" ;
VAL_ 2566906094 WklyRestPrdCalcEnabledDisabled_I 3 "DisableEnable_NotAvailable" 2 "DisableEnable_Error" 1 "DisableEnable_Enable" 0 "DisableEnable_Disable" ;
VAL_ 2566906094 Remaining10hDrvTime_ISig_3 7 "Remaining10hDrvTime_NotAvailable" 6 "Remaining10hDrvTime_Error" 5 "Remaining10hDrvTime_Spare_03" 4 "Remaining10hDrvTime_Spare_02" 3 "Remaining10hDrvTime_Spare_01" 2 "Remaining10hDrvTime_2Remaining10hDrivingTimes" 1 "Remaining10hDrvTime_1Remaining10hDrivingTimes" 0 "Remaining10hDrvTime_0Remaining10hDrivingTimes" ;
VAL_ 2566906094 SufficientData_ISig_3 3 "SufficientData_NotAvailable" 2 "SufficientData_Error" 1 "SufficientData_NoSufficientDataOnTheDriverCard" 0 "SufficientData_SufficientDataOnDriverCardAvailable" ;
VAL_ 2364541195 SteeringWheelAngleSensorType_ISi 3 "SteeringWheelAngleSensorType_NotAvailable" 2 "SteeringWheelAngleSensorType_Reserved" 1 "SteeringWheelAngleSensorType_AbsoluteMeasuringPrinciple" 0 "SteeringWheelAngleSensorType_RelativeMeasuringPrinciple" ;
VAL_ 2566803211 ESCHealthStatus_ISig_3 3 "OffOnSpare_NotAvailable" 2 "OffOnSpare_Spare" 1 "OffOnSpare_On" 0 "OffOnSpare_Off" ;
VAL_ 2566803211 ROPEngineControlActive_ISig_3 3 "PassiveActive2_DontCareTakeNoAction" 2 "PassiveActive2_Reserved" 1 "PassiveActive2_Active" 0 "PassiveActive2_PassiveButInstalled" ;
VAL_ 2566803211 YCEngineControlActive_ISig_3 3 "PassiveActive2_DontCareTakeNoAction" 2 "PassiveActive2_Reserved" 1 "PassiveActive2_Active" 0 "PassiveActive2_PassiveButInstalled" ;
VAL_ 2566803211 ROPBrakeControlActive_ISig_3 3 "PassiveActive2_DontCareTakeNoAction" 2 "PassiveActive2_Reserved" 1 "PassiveActive2_Active" 0 "PassiveActive2_PassiveButInstalled" ;
VAL_ 2566803211 YCBrakeControlActive_ISig_3 3 "PassiveActive2_DontCareTakeNoAction" 2 "PassiveActive2_Reserved" 1 "PassiveActive2_Active" 0 "PassiveActive2_PassiveButInstalled" ;
VAL_ 2566803211 VDCFullyOperational 3 "FullyOperational_NotAvailable" 2 "FullyOperational_Reserved" 1 "FullyOperational_FullyOperational" 0 "FullyOperational_NotFullyOperational" ;
VAL_ 2348814353 TSC1RECUVMCU_EnOvrdCtrlM 3 "TSC1EngOverrideCtrlMode_SpeedTorqueLimitControl" 2 "TSC1EngOverrideCtrlMode_TorqueControl" 1 "TSC1EngOverrideCtrlMode_SpeedControl" 0 "TSC1EngOverrideCtrlMode_OverrideDisabled" ;
VAL_ 2348814353 TSC1RECUVMCU_EnRSpdCtrlC 3 "TSC1EngReqSpeedCtrlCond_StabilityOptDrvlnEngLockup2" 2 "TSC1EngReqSpeedCtrlCond_StabilityOptDrvlnEngLockup1" 1 "TSC1EngReqSpeedCtrlCond_StabilityOptDrvlnDisengNonLockup" 0 "TSC1EngReqSpeedCtrlCond_TransientOptimized" ;
VAL_ 2348814353 TSC1RECUVMCU_OvrdCtrlMPr 3 "Priority_LowPriority" 2 "Priority_MediumPriority" 1 "Priority_HighPriority" 0 "Priority_HighestPriority" ;
VAL_ 2348814339 TSC1RECUTECU_EnOvrdCtrlM 3 "TSC1EngOverrideCtrlMode_SpeedTorqueLimitControl" 2 "TSC1EngOverrideCtrlMode_TorqueControl" 1 "TSC1EngOverrideCtrlMode_SpeedControl" 0 "TSC1EngOverrideCtrlMode_OverrideDisabled" ;
VAL_ 2348814339 TSC1RECUTECU_OvrdCtrlMPr 3 "Priority_LowPriority" 2 "Priority_MediumPriority" 1 "Priority_HighPriority" 0 "Priority_HighestPriority" ;
VAL_ 2348814339 TSC1RECUTECU_EnRSpdCtrlC 3 "TSC1EngReqSpeedCtrlCond_StabilityOptDrvlnEngLockup2" 2 "TSC1EngReqSpeedCtrlCond_StabilityOptDrvlnEngLockup1" 1 "TSC1EngReqSpeedCtrlCond_StabilityOptDrvlnDisengNonLockup" 0 "TSC1EngReqSpeedCtrlCond_TransientOptimized" ;
VAL_ 2348814337 TSC1RECUEMSdap_OvrdCtrlMPr 3 "Priority_LowPriority" 2 "Priority_MediumPriority" 1 "Priority_HighPriority" 0 "Priority_HighestPriority" ;
VAL_ 2348814337 TSC1RECUEMSdap_EnOvrdCtrlM 3 "TSC1EngOverrideCtrlMode_SpeedTorqueLimitControl" 2 "TSC1EngOverrideCtrlMode_TorqueControl" 1 "TSC1EngOverrideCtrlMode_SpeedControl" 0 "TSC1EngOverrideCtrlMode_OverrideDisabled" ;
VAL_ 2348814337 TSC1RECUEMSdap_EnRSpdCtrlC 3 "TSC1EngReqSpeedCtrlCond_StabilityOptDrvlnEngLockup2" 2 "TSC1EngReqSpeedCtrlCond_StabilityOptDrvlnEngLockup1" 1 "TSC1EngReqSpeedCtrlCond_StabilityOptDrvlnDisengNonLockup" 0 "TSC1EngReqSpeedCtrlCond_TransientOptimized" ;
VAL_ 2348814336 TSC1RECUEMSccb_EnRSpdCtrlC 3 "TSC1EngReqSpeedCtrlCond_StabilityOptDrvlnEngLockup2" 2 "TSC1EngReqSpeedCtrlCond_StabilityOptDrvlnEngLockup1" 1 "TSC1EngReqSpeedCtrlCond_StabilityOptDrvlnDisengNonLockup" 0 "TSC1EngReqSpeedCtrlCond_TransientOptimized" ;
VAL_ 2348814336 TSC1RECUEMSccb_EnOvrdCtrlM 3 "TSC1EngOverrideCtrlMode_SpeedTorqueLimitControl" 2 "TSC1EngOverrideCtrlMode_TorqueControl" 1 "TSC1EngOverrideCtrlMode_SpeedControl" 0 "TSC1EngOverrideCtrlMode_OverrideDisabled" ;
VAL_ 2348814336 TSC1RECUEMSccb_OvrdCtrlMPr 3 "Priority_LowPriority" 2 "Priority_MediumPriority" 1 "Priority_HighPriority" 0 "Priority_HighestPriority" ;
VAL_ 2348814347 TSC1RECUABS_EnOvrdCtrlM 3 "TSC1EngOverrideCtrlMode_SpeedTorqueLimitControl" 2 "TSC1EngOverrideCtrlMode_TorqueControl" 1 "TSC1EngOverrideCtrlMode_SpeedControl" 0 "TSC1EngOverrideCtrlMode_OverrideDisabled" ;
VAL_ 2348814347 TSC1RECUABS_OvrdCtrlMPr 3 "Priority_LowPriority" 2 "Priority_MediumPriority" 1 "Priority_HighPriority" 0 "Priority_HighestPriority" ;
VAL_ 2348814347 TSC1RECUABS_EnRSpdCtrlC 3 "TSC1EngReqSpeedCtrlCond_StabilityOptDrvlnEngLockup2" 2 "TSC1EngReqSpeedCtrlCond_StabilityOptDrvlnEngLockup1" 1 "TSC1EngReqSpeedCtrlCond_StabilityOptDrvlnDisengNonLockup" 0 "TSC1EngReqSpeedCtrlCond_TransientOptimized" ;
VAL_ 2348810257 TSC1EMSVMCUtr_EnOvrdCtrlM 3 "TSC1EngOverrideCtrlMode_SpeedTorqueLimitControl" 2 "TSC1EngOverrideCtrlMode_TorqueControl" 1 "TSC1EngOverrideCtrlMode_SpeedControl" 0 "TSC1EngOverrideCtrlMode_OverrideDisabled" ;
VAL_ 2348810257 TSC1EMSVMCUtr_EnRSpdCtrlC 3 "TSC1EngReqSpeedCtrlCond_StabilityOptDrvlnEngLockup2" 2 "TSC1EngReqSpeedCtrlCond_StabilityOptDrvlnEngLockup1" 1 "TSC1EngReqSpeedCtrlCond_StabilityOptDrvlnDisengNonLockup" 0 "TSC1EngReqSpeedCtrlCond_TransientOptimized" ;
VAL_ 2348810257 TSC1EMSVMCUtr_OvrdCtrlMPr 3 "Priority_LowPriority" 2 "Priority_MediumPriority" 1 "Priority_HighPriority" 0 "Priority_HighestPriority" ;
VAL_ 2348810288 TSC1EMSVMCUes_OvrdCtrlMPr 3 "Priority_LowPriority" 2 "Priority_MediumPriority" 1 "Priority_HighPriority" 0 "Priority_HighestPriority" ;
VAL_ 2348810288 TSC1EMSVMCUes_EnOvrdCtrlM 3 "TSC1EngOverrideCtrlMode_SpeedTorqueLimitControl" 2 "TSC1EngOverrideCtrlMode_TorqueControl" 1 "TSC1EngOverrideCtrlMode_SpeedControl" 0 "TSC1EngOverrideCtrlMode_OverrideDisabled" ;
VAL_ 2348810288 TSC1EMSVMCUes_EnRSpdCtrlC 3 "TSC1EngReqSpeedCtrlCond_StabilityOptDrvlnEngLockup2" 2 "TSC1EngReqSpeedCtrlCond_StabilityOptDrvlnEngLockup1" 1 "TSC1EngReqSpeedCtrlCond_StabilityOptDrvlnDisengNonLockup" 0 "TSC1EngReqSpeedCtrlCond_TransientOptimized" ;
VAL_ 2348810243 TSC1EMSTECU_EnOvrdCtrlM 3 "TSC1EngOverrideCtrlMode_SpeedTorqueLimitControl" 2 "TSC1EngOverrideCtrlMode_TorqueControl" 1 "TSC1EngOverrideCtrlMode_SpeedControl" 0 "TSC1EngOverrideCtrlMode_OverrideDisabled" ;
VAL_ 2348810243 TSC1EMSTECU_OvrdCtrlMPr 3 "Priority_LowPriority" 2 "Priority_MediumPriority" 1 "Priority_HighPriority" 0 "Priority_HighestPriority" ;
VAL_ 2348810243 TSC1EMSTECU_EnRSpdCtrlC 3 "TSC1EngReqSpeedCtrlCond_StabilityOptDrvlnEngLockup2" 2 "TSC1EngReqSpeedCtrlCond_StabilityOptDrvlnEngLockup1" 1 "TSC1EngReqSpeedCtrlCond_StabilityOptDrvlnDisengNonLockup" 0 "TSC1EngReqSpeedCtrlCond_TransientOptimized" ;
VAL_ 2348810251 TSC1EMSABS_EnRSpdCtrlC 3 "TSC1EngReqSpeedCtrlCond_StabilityOptDrvlnEngLockup2" 2 "TSC1EngReqSpeedCtrlCond_StabilityOptDrvlnEngLockup1" 1 "TSC1EngReqSpeedCtrlCond_StabilityOptDrvlnDisengNonLockup" 0 "TSC1EngReqSpeedCtrlCond_TransientOptimized" ;
VAL_ 2348810251 TSC1EMSABS_OvrdCtrlMPr 3 "Priority_LowPriority" 2 "Priority_MediumPriority" 1 "Priority_HighPriority" 0 "Priority_HighestPriority" ;
VAL_ 2348810251 TSC1EMSABS_EnOvrdCtrlM 3 "TSC1EngOverrideCtrlMode_SpeedTorqueLimitControl" 2 "TSC1EngOverrideCtrlMode_TorqueControl" 1 "TSC1EngOverrideCtrlMode_SpeedControl" 0 "TSC1EngOverrideCtrlMode_OverrideDisabled" ;
VAL_ 2348810413 TSC1EMSDACU_OvrdCtrlMPr 3 "Priority_LowPriority" 2 "Priority_MediumPriority" 1 "Priority_HighPriority" 0 "Priority_HighestPriority" ;
VAL_ 2348810413 TSC1EMSDACU_EnRSpdCtrlC 3 "TSC1EngReqSpeedCtrlCond_StabilityOptDrvlnEngLockup2" 2 "TSC1EngReqSpeedCtrlCond_StabilityOptDrvlnEngLockup1" 1 "TSC1EngReqSpeedCtrlCond_StabilityOptDrvlnDisengNonLockup" 0 "TSC1EngReqSpeedCtrlCond_TransientOptimized" ;
VAL_ 2348810413 TSC1EMSDACU_EnOvrdCtrlM 3 "TSC1EngOverrideCtrlMode_SpeedTorqueLimitControl" 2 "TSC1EngOverrideCtrlMode_TorqueControl" 1 "TSC1EngOverrideCtrlMode_SpeedControl" 0 "TSC1EngOverrideCtrlMode_OverrideDisabled" ;
SIG_GROUP_ 2349075203 XBRTECU_sg 1 : XBRTECU_Priority XBRTECU_MsgChecksum XBRTECU_EBIMode XBRTECU_Urgency XBRTECU_ControlMode XBRTECU_ExtAccelDemand XBRTECU_MsgCounter;
SIG_GROUP_ 2349075200 XBREMS_sg 1 : XBREMS_ControlMode XBREMS_MsgCounter XBREMS_Urgency XBREMS_EBIMode XBREMS_ExtAccelDemand XBREMS_Priority XBREMS_MsgChecksum;
SIG_GROUP_ 2349075373 XBRDACU_sg 1 : XBRDACU_Urgency XBRDACU_EBIMode XBRDACU_ExtAccelDemand XBRDACU_MsgCounter XBRDACU_MsgChecksum XBRDACU_ControlMode XBRDACU_Priority;
SIG_GROUP_ 2349075430 XBRBBM_sg 1 : XBRBBM_Urgency XBRBBM_ControlMode XBRBBM_Priority XBRBBM_MsgCounter XBRBBM_MsgChecksum XBRBBM_EBIMode XBRBBM_ExtAccelDemand;
SIG_GROUP_ 2499751697 RearPropulsionStat_sg_ISig_3 1 : RearPropulsionStat_Rear1Axle_ISi RearPropulsionStat_Rear3Axle_ISi RearPropulsionStat_Rear2Axle_ISi;
SIG_GROUP_ 2348814353 TSC1RECUVMCU_sg 1 : TSC1RECUVMCU_EnRSpdSpdLm TSC1RECUVMCU_EnOvrdCtrlM TSC1RECUVMCU_EnRTrqTrqLm TSC1RECUVMCU_EnRSpdCtrlC TSC1RECUVMCU_OvrdCtrlMPr;
SIG_GROUP_ 2348814339 TSC1RECUTECU_sg 1 : TSC1RECUTECU_EnRTrqTrqLm TSC1RECUTECU_EnOvrdCtrlM TSC1RECUTECU_OvrdCtrlMPr TSC1RECUTECU_EnRSpdCtrlC TSC1RECUTECU_EnRSpdSpdLm;
SIG_GROUP_ 2348814337 TSC1RECUEMSdap_sg 1 : TSC1RECUEMSdap_EnRSpdSpdLm TSC1RECUEMSdap_OvrdCtrlMPr TSC1RECUEMSdap_EnOvrdCtrlM TSC1RECUEMSdap_EnRSpdCtrlC TSC1RECUEMSdap_EnRTrqTrqLm;
SIG_GROUP_ 2348814336 TSC1RECUEMSccb_sg 1 : TSC1RECUEMSccb_EnRSpdSpdLm TSC1RECUEMSccb_EnRSpdCtrlC TSC1RECUEMSccb_EnOvrdCtrlM TSC1RECUEMSccb_OvrdCtrlMPr TSC1RECUEMSccb_EnRTrqTrqLm;
SIG_GROUP_ 2348814347 TSC1RECUABS_sg 1 : TSC1RECUABS_EnOvrdCtrlM TSC1RECUABS_EnRTrqTrqLm TSC1RECUABS_EnRSpdSpdLm TSC1RECUABS_OvrdCtrlMPr TSC1RECUABS_EnRSpdCtrlC;
SIG_GROUP_ 2348810257 TSC1EMSVMCUtr_sg 1 : TSC1EMSVMCUtr_EnOvrdCtrlM TSC1EMSVMCUtr_EnRSpdCtrlC TSC1EMSVMCUtr_OvrdCtrlMPr TSC1EMSVMCUtr_EnRSpdSpdLm TSC1EMSVMCUtr_EnRTrqTrqLm;
SIG_GROUP_ 2348810288 TSC1EMSVMCUes_sg 1 : TSC1EMSVMCUes_OvrdCtrlMPr TSC1EMSVMCUes_EnRTrqTrqLm TSC1EMSVMCUes_EnOvrdCtrlM TSC1EMSVMCUes_EnRSpdSpdLm TSC1EMSVMCUes_EnRSpdCtrlC;
SIG_GROUP_ 2348810243 TSC1EMSTECU_sg 1 : TSC1EMSTECU_EnRSpdSpdLm TSC1EMSTECU_EnOvrdCtrlM TSC1EMSTECU_OvrdCtrlMPr TSC1EMSTECU_EnRSpdCtrlC TSC1EMSTECU_EnRTrqTrqLm;
SIG_GROUP_ 2348810251 TSC1EMSABS_sg 1 : TSC1EMSABS_EnRTrqTrqLm TSC1EMSABS_EnRSpdCtrlC TSC1EMSABS_OvrdCtrlMPr TSC1EMSABS_EnOvrdCtrlM TSC1EMSABS_EnRSpdSpdLm;
SIG_GROUP_ 2348810413 TSC1EMSDACU_sg 1 : TSC1EMSDACU_OvrdCtrlMPr TSC1EMSDACU_EnRSpdSpdLm TSC1EMSDACU_EnRSpdCtrlC TSC1EMSDACU_EnRTrqTrqLm TSC1EMSDACU_EnOvrdCtrlM;
